VERSION "HNNBNNNYNNNNNNNNNNNNNNNNNNNNNNNNNNNNNNNNNN/4/%%%/4/'%**4NNN///"

NS_ :

BS_:

BU_: Airbag Allrad_Haldex BAP_Tester DCC_Gen3 EBKV_MQBW ESC_MQBW Gateway_Max Lenkhilfe_REPS

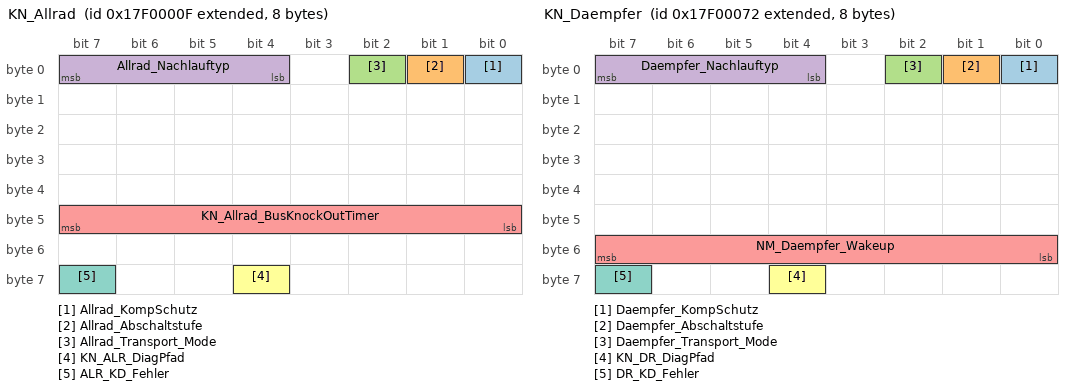
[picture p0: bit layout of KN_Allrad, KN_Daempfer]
BO_ 2549088271 KN_Allrad: 8 Allrad_Haldex
 SG_ Allrad_KompSchutz : 0|1@1+ (1.0,0.0) [0.0|1] ""  Vector__XXX
 SG_ Allrad_Abschaltstufe : 1|1@1+ (1.0,0.0) [0.0|1] ""  Vector__XXX
 SG_ Allrad_Transport_Mode : 2|1@1+ (1.0,0.0) [0.0|1] ""  Vector__XXX
 SG_ Allrad_Nachlauftyp : 4|4@1+ (1.0,0.0) [0.0|15] ""  Gateway_Max
 SG_ KN_Allrad_BusKnockOutTimer : 40|8@1+ (1,0) [0|254] ""  Vector__XXX
 SG_ KN_ALR_DiagPfad : 60|1@1+ (1.0,0.0) [0.0|1] ""  Gateway_Max
 SG_ ALR_KD_Fehler : 63|1@1+ (1.0,0.0) [0.0|1] ""  Gateway_Max

BO_ 2549088370 KN_Daempfer: 8 DCC_Gen3
 SG_ Daempfer_KompSchutz : 0|1@1+ (1.0,0.0) [0.0|1] ""  Vector__XXX
 SG_ Daempfer_Abschaltstufe : 1|1@1+ (1.0,0.0) [0.0|1] ""  Vector__XXX
 SG_ Daempfer_Transport_Mode : 2|1@1+ (1.0,0.0) [0.0|1] ""  Vector__XXX
 SG_ Daempfer_Nachlauftyp : 4|4@1+ (1.0,0.0) [0.0|15] ""  Gateway_Max
 SG_ NM_Daempfer_Wakeup : 48|8@1+ (1.0,0.0) [0.0|255] ""  Vector__XXX
 SG_ KN_DR_DiagPfad : 60|1@1+ (1.0,0.0) [0.0|1] ""  Gateway_Max
 SG_ DR_KD_Fehler : 63|1@1+ (1.0,0.0) [0.0|1] ""  Gateway_Max

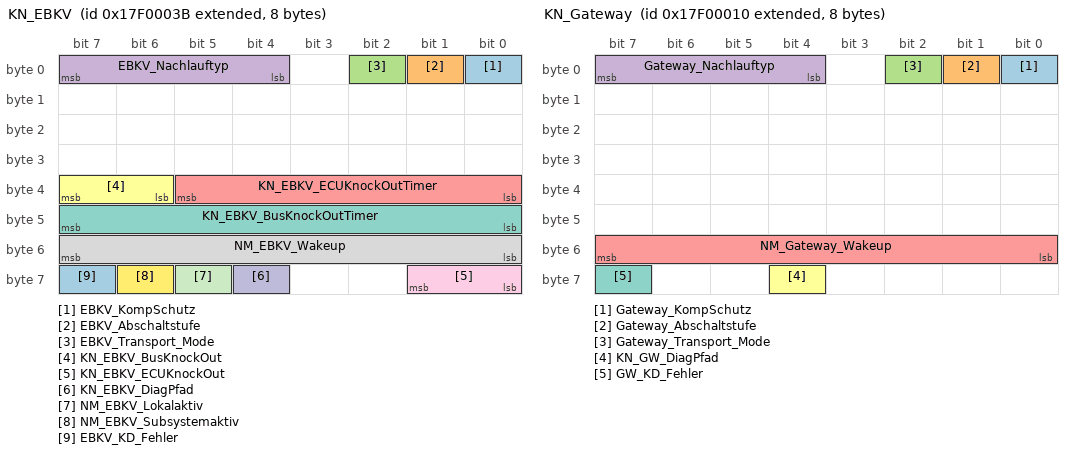
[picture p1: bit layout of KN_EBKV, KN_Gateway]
BO_ 2549088315 KN_EBKV: 8 EBKV_MQBW
 SG_ EBKV_KompSchutz : 0|1@1+ (1.0,0.0) [0.0|1] ""  Vector__XXX
 SG_ EBKV_Abschaltstufe : 1|1@1+ (1.0,0.0) [0.0|1] ""  Vector__XXX
 SG_ EBKV_Transport_Mode : 2|1@1+ (1.0,0.0) [0.0|1] ""  Vector__XXX
 SG_ EBKV_Nachlauftyp : 4|4@1+ (1.0,0.0) [0.0|15] ""  Gateway_Max
 SG_ KN_EBKV_ECUKnockOutTimer : 32|6@1+ (1,0) [0|62] "Unit_Minut"  Vector__XXX
 SG_ KN_EBKV_BusKnockOut : 38|2@1+ (1.0,0.0) [0.0|3] ""  Vector__XXX
 SG_ KN_EBKV_BusKnockOutTimer : 40|8@1+ (1,0) [0|254] ""  Vector__XXX
 SG_ NM_EBKV_Wakeup : 48|8@1+ (1.0,0.0) [0.0|255] ""  Vector__XXX
 SG_ KN_EBKV_ECUKnockOut : 56|2@1+ (1.0,0.0) [0.0|3] ""  Vector__XXX
 SG_ KN_EBKV_DiagPfad : 60|1@1+ (1.0,0.0) [0.0|1] ""  Gateway_Max
 SG_ NM_EBKV_Lokalaktiv : 61|1@1+ (1.0,0.0) [0.0|1] ""  Vector__XXX
 SG_ NM_EBKV_Subsystemaktiv : 62|1@1+ (1.0,0.0) [0.0|1] ""  Vector__XXX
 SG_ EBKV_KD_Fehler : 63|1@1+ (1.0,0.0) [0.0|1] ""  Gateway_Max

BO_ 2549088272 KN_Gateway: 8 Gateway_Max
 SG_ Gateway_KompSchutz : 0|1@1+ (1.0,0.0) [0.0|1] ""  Vector__XXX
 SG_ Gateway_Abschaltstufe : 1|1@1+ (1.0,0.0) [0.0|1] ""  Vector__XXX
 SG_ Gateway_Transport_Mode : 2|1@1+ (1.0,0.0) [0.0|1] ""  Vector__XXX
 SG_ Gateway_Nachlauftyp : 4|4@1+ (1.0,0.0) [0.0|15] ""  Vector__XXX
 SG_ NM_Gateway_Wakeup : 48|8@1+ (1.0,0.0) [0.0|255] ""  Vector__XXX
 SG_ KN_GW_DiagPfad : 60|1@1+ (1.0,0.0) [0.0|1] ""  Vector__XXX
 SG_ GW_KD_Fehler : 63|1@1+ (1.0,0.0) [0.0|1] ""  Vector__XXX

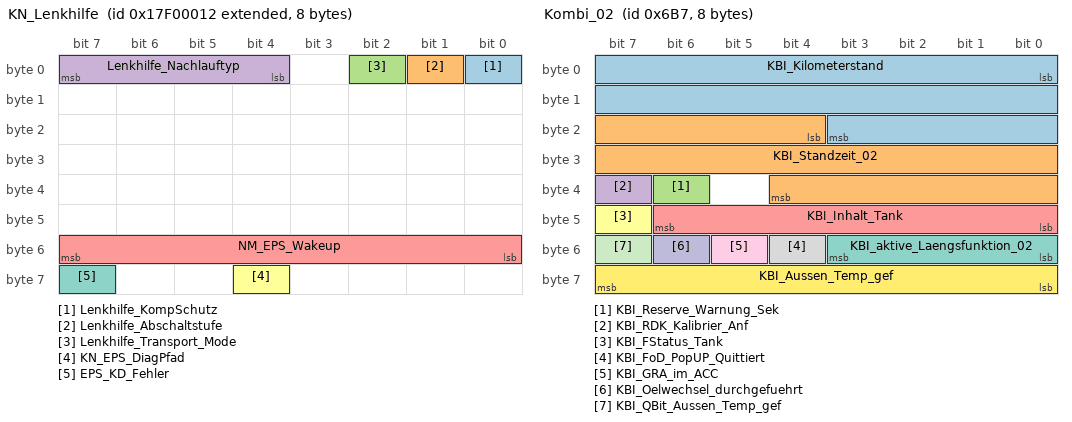
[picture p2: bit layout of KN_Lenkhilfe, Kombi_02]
BO_ 2549088274 KN_Lenkhilfe: 8 Lenkhilfe_REPS
 SG_ Lenkhilfe_KompSchutz : 0|1@1+ (1.0,0.0) [0.0|1] ""  Vector__XXX
 SG_ Lenkhilfe_Abschaltstufe : 1|1@1+ (1.0,0.0) [0.0|1] ""  Vector__XXX
 SG_ Lenkhilfe_Transport_Mode : 2|1@1+ (1.0,0.0) [0.0|1] ""  Vector__XXX
 SG_ Lenkhilfe_Nachlauftyp : 4|4@1+ (1.0,0.0) [0.0|15] ""  Gateway_Max
 SG_ NM_EPS_Wakeup : 48|8@1+ (1.0,0.0) [0.0|255] ""  Vector__XXX
 SG_ KN_EPS_DiagPfad : 60|1@1+ (1.0,0.0) [0.0|1] ""  Gateway_Max
 SG_ EPS_KD_Fehler : 63|1@1+ (1.0,0.0) [0.0|1] ""  Gateway_Max

BO_ 779 Kombi_01: 8 Gateway_Max
 SG_ KBI_ABS_Lampe : 0|1@1+ (1.0,0.0) [0.0|1] ""  Vector__XXX
 SG_ KBI_ESP_Lampe : 1|1@1+ (1.0,0.0) [0.0|1] ""  Vector__XXX
 SG_ KBI_BKL_Lampe : 2|1@1+ (1.0,0.0) [0.0|1] ""  Vector__XXX
 SG_ KBI_Airbag_Lampe : 3|1@1+ (1.0,0.0) [0.0|1] ""  Vector__XXX
 SG_ KBI_SILA_gueltig : 4|1@1+ (1.0,0.0) [0.0|1] ""  Vector__XXX
 SG_ KBI_Lenkung_Lampe : 5|1@1+ (1,0) [0|1] ""  Vector__XXX
 SG_ KBI_Vorglueh_System_Lampe : 6|1@1+ (1.0,0.0) [0.0|1] ""  Vector__XXX
 SG_ KBI_NV_in_Anzeige : 7|1@1+ (1.0,0.0) [0.0|1] ""  Vector__XXX
 SG_ Kombi_01_BZ : 8|4@1+ (1,0) [0|15] ""  Vector__XXX
 SG_ KBI_Anzeigestatus_ACC : 12|1@1+ (1.0,0.0) [0.0|1] ""  Vector__XXX
 SG_ KBI_Anzeigestatus_GRA : 13|2@1+ (1.0,0.0) [0.0|3] ""  Vector__XXX
 SG_ KBI_Oeldruck_Schalter : 15|1@1+ (1.0,0.0) [0.0|1] ""  Vector__XXX
 SG_ KBI_Tankwarnung : 16|1@1+ (1.0,0.0) [0.0|1] ""  Vector__XXX
 SG_ KBI_MFA_v_Einheit_01 : 17|1@1+ (1.0,0.0) [0.0|1] ""  Vector__XXX
 SG_ KBI_im_Stellgliedtest : 18|1@1+ (1.0,0.0) [0.0|1] ""  Vector__XXX
 SG_ KBI_Anzeigefehler_LDW : 19|2@1+ (1.0,0.0) [0.0|3] ""  Vector__XXX
 SG_ KBI_Tankwarnung_ungueltig : 21|1@1+ (1.0,0.0) [0.0|1] ""  Vector__XXX
 SG_ KBI_Oeldruckwarnung : 22|1@1+ (1.0,0.0) [0.0|1] ""  Vector__XXX
 SG_ KBI_Handbremse : 23|1@1+ (1.0,0.0) [0.0|1] ""  Vector__XXX
 SG_ KBI_V_Digital : 24|9@1+ (1,0) [0|511] ""  Vector__XXX
 SG_ KBI_PLA_in_Anzeige : 33|1@1+ (1.0,0.0) [0.0|1] ""  Vector__XXX
 SG_ KBI_Anzeigefehler_NV : 34|1@1+ (1.0,0.0) [0.0|1] ""  Vector__XXX
 SG_ KBI_Anzeigestatus_LIM : 35|2@1+ (1.0,0.0) [0.0|3] ""  Vector__XXX
 SG_ KBI_ARA_in_Anzeige : 37|1@1+ (1.0,0.0) [0.0|1] ""  Vector__XXX
 SG_ KBI_Taster_Lift : 38|1@1+ (1.0,0.0) [0.0|1] ""  Vector__XXX
 SG_ KBI_Taster_Fahrwerk : 39|1@1+ (1.0,0.0) [0.0|1] ""  Vector__XXX
 SG_ KBI_Audioabsenkung_MIB : 40|2@1+ (1.0,0.0) [0.0|3] ""  Vector__XXX
 SG_ KBI_Bestaetigung_ESP_Off : 42|2@1+ (1.0,0.0) [0.0|3] ""  ESC_MQBW
 SG_ KBI_Anzeigestatus_RHP : 44|2@1+ (1.0,0.0) [0.0|3] ""  Vector__XXX
 SG_ KBI_angez_Geschw : 48|10@1+ (0.32,0) [0.00|325.12] "Unit_KiloMeterPerHour"  Airbag
 SG_ KBI_Konsistenz_ACC : 59|1@1+ (1.0,0.0) [0.0|1] ""  Vector__XXX
 SG_ KBI_Fehler_Anzeige_ACC : 60|1@1+ (1.0,0.0) [0.0|1] ""  Vector__XXX
 SG_ KBI_Anzeigefehler_SWA : 61|2@1+ (1.0,0.0) [0.0|3] ""  Vector__XXX
 SG_ KBI_Systemstatus : 63|1@1+ (1.0,0.0) [0.0|1] ""  Vector__XXX

BO_ 1719 Kombi_02: 8 Gateway_Max
 SG_ KBI_Kilometerstand : 0|20@1+ (1,0) [0|1048573] "Unit_KiloMeter"  Vector__XXX
 SG_ KBI_Standzeit_02 : 20|17@1+ (1,0) [0|131068] "Unit_Secon"  Allrad_Haldex,ESC_MQBW
 SG_ KBI_Reserve_Warnung_Sek : 38|1@1+ (1.0,0.0) [0.0|1] ""  Vector__XXX
 SG_ KBI_RDK_Kalibrier_Anf : 39|1@1+ (1.0,0.0) [0.0|1] ""  Vector__XXX
 SG_ KBI_Inhalt_Tank : 40|7@1+ (1,0) [0|125] "Unit_Liter"  Vector__XXX
 SG_ KBI_FStatus_Tank : 47|1@1+ (1.0,0.0) [0.0|1] ""  Vector__XXX
 SG_ KBI_aktive_Laengsfunktion_02 : 48|4@1+ (1.0,0.0) [0.0|15] ""  Vector__XXX
 SG_ KBI_FoD_PopUP_Quittiert : 52|1@1+ (1.0,0.0) [0.0|1] ""  Vector__XXX
 SG_ KBI_GRA_im_ACC : 53|1@1+ (1.0,0.0) [0.0|1] ""  Vector__XXX
 SG_ KBI_Oelwechsel_durchgefuehrt : 54|1@1+ (1.0,0.0) [0.0|1] ""  Vector__XXX
 SG_ KBI_QBit_Aussen_Temp_gef : 55|1@1+ (1.0,0.0) [0.0|1] ""  Airbag,Allrad_Haldex,ESC_MQBW
 SG_ KBI_Aussen_Temp_gef : 56|8@1+ (0.5,-50) [-50.0|75.0] "Unit_DegreCelsi"  Airbag,Allrad_Haldex,ESC_MQBW

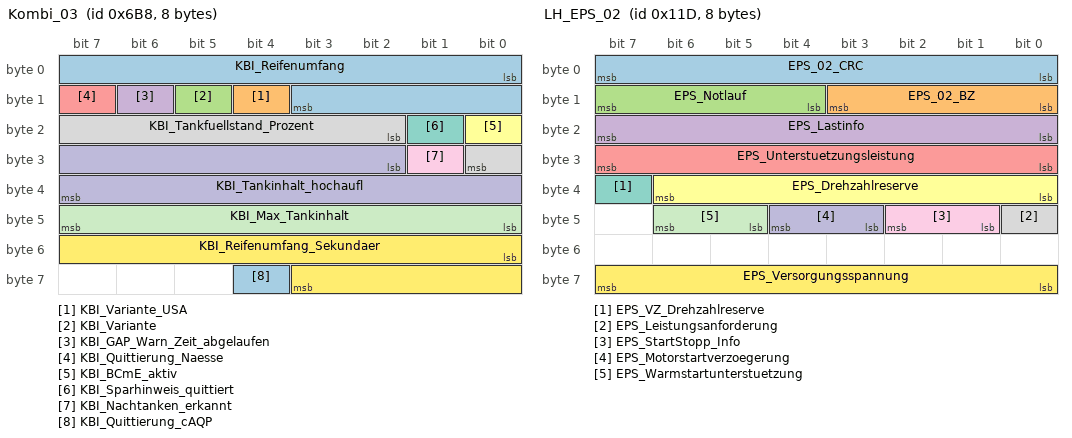
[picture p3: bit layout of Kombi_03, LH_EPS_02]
BO_ 1720 Kombi_03: 8 Gateway_Max
 SG_ KBI_Reifenumfang : 0|12@1+ (1,0) [0|4095] "Unit_MilliMeter"  ESC_MQBW
 SG_ KBI_Variante_USA : 12|1@1+ (1.0,0.0) [0.0|1] ""  Vector__XXX
 SG_ KBI_Variante : 13|1@1+ (1.0,0.0) [0.0|1] ""  Vector__XXX
 SG_ KBI_GAP_Warn_Zeit_abgelaufen : 14|1@1+ (1.0,0.0) [0.0|1] ""  Vector__XXX
 SG_ KBI_Quittierung_Naesse : 15|1@1+ (1.0,0.0) [0.0|1] ""  Vector__XXX
 SG_ KBI_BCmE_aktiv : 16|1@1+ (1.0,0.0) [0.0|1] ""  Vector__XXX
 SG_ KBI_Sparhinweis_quittiert : 17|1@1+ (1.0,0.0) [0.0|1] ""  Vector__XXX
 SG_ KBI_Tankfuellstand_Prozent : 18|7@1+ (1,0) [0|100] "Unit_PerCent"  Vector__XXX
 SG_ KBI_Nachtanken_erkannt : 25|1@1+ (1.0,0.0) [0.0|1] ""  Vector__XXX
 SG_ KBI_Tankinhalt_hochaufl : 26|14@1+ (0.01,0) [0.00|163.81] "Unit_Liter"  Vector__XXX
 SG_ KBI_Max_Tankinhalt : 40|8@1+ (0.5,0) [0.0|126.5] ""  Vector__XXX
 SG_ KBI_Reifenumfang_Sekundaer : 48|12@1+ (1,0) [0|4095] "Unit_MilliMeter"  Vector__XXX
 SG_ KBI_Quittierung_cAQP : 60|1@1+ (1.0,0.0) [0.0|1] ""  Vector__XXX

BO_ 2621440277 KS_Airbag_01_Req_FD: 16 Gateway_Max
 SG_ KS_Airbag_01_Req_FD_Data : 0|128@1+ (1.0,0.0) [0.0|340282366920938463463374607431768211455] ""  Airbag

BO_ 2621571349 KS_Airbag_01_Resp_FD: 16 Airbag
 SG_ KS_Airbag_01_Resp_FD_Data : 0|128@1+ (1.0,0.0) [0.0|340282366920938463463374607431768211455] ""  Gateway_Max

BO_ 810 LH_EPS_01: 8 Lenkhilfe_REPS
 SG_ EPS_01_CRC : 0|8@1+ (1,0) [0|255] ""  Gateway_Max
 SG_ EPS_01_BZ : 8|4@1+ (1,0) [0|15] ""  Gateway_Max
 SG_ EPS_SpannungsAnf : 12|2@1+ (1.0,0.0) [0.0|3] ""  Gateway_Max
 SG_ EPS_Endanschlag : 14|2@1+ (1.0,0.0) [0.0|3] ""  Gateway_Max
 SG_ EPS_Akustiksignal : 16|1@1+ (1.0,0.0) [0.0|1] ""  Gateway_Max
 SG_ EPS_Fehlerlampe : 17|1@1+ (1.0,0.0) [0.0|1] ""  Gateway_Max
 SG_ EPS_Warnungen : 19|3@1+ (1.0,0.0) [0.0|7] ""  Gateway_Max
 SG_ EPS_PLA_Abbruch : 22|4@1+ (1,0) [0|15] ""  Gateway_Max
 SG_ EPS_PLA_Fehler : 26|4@1+ (1,0) [0|15] ""  Gateway_Max
 SG_ EPS_PLA_Status : 30|4@1+ (1.0,0.0) [0.0|15] ""  Gateway_Max
 SG_ EPS_Charisma_FahrPr : 34|4@1+ (1.0,0.0) [0.0|15] ""  Gateway_Max
 SG_ EPS_Charisma_Status : 38|2@1+ (1.0,0.0) [0.0|3] ""  Gateway_Max
 SG_ EPS_VZ_Zst_Offset_Geradeaus : 40|1@1+ (1.0,0.0) [0.0|1] ""  Gateway_Max
 SG_ EPS_Lenkerposition : 41|2@1+ (1.0,0.0) [0.0|3] ""  Gateway_Max
 SG_ EPS_Anf_KL : 43|1@1+ (1.0,0.0) [0.0|1] ""  Gateway_Max
 SG_ EPS_ARA_Status : 44|4@1+ (1.0,0.0) [0.0|15] ""  Gateway_Max
 SG_ EPS_Zst_Offset_Geradeaus : 48|9@1+ (0.00306,0) [0.00000|1.55754] "Unit_MilliMeter"  Gateway_Max

BO_ 285 LH_EPS_02: 8 Lenkhilfe_REPS
 SG_ EPS_02_CRC : 0|8@1+ (1,0) [0|255] ""  Gateway_Max
 SG_ EPS_02_BZ : 8|4@1+ (1,0) [0|15] ""  Gateway_Max
 SG_ EPS_Notlauf : 12|4@1+ (1.0,0.0) [0.0|15] ""  Gateway_Max
 SG_ EPS_Lastinfo : 16|8@1+ (1,0) [0|253] "Unit_Amper"  Gateway_Max
 SG_ EPS_Unterstuetzungsleistung : 24|8@1+ (0.5,0) [0.0|100.0] "Unit_PerCent"  Gateway_Max
 SG_ EPS_Drehzahlreserve : 32|7@1+ (10,0) [0|1000] "Unit_DegreOfArcPerSecon"  Gateway_Max
 SG_ EPS_VZ_Drehzahlreserve : 39|1@1+ (1.0,0.0) [0.0|1] ""  Gateway_Max
 SG_ EPS_Leistungsanforderung : 40|1@1+ (1.0,0.0) [0.0|1] ""  Gateway_Max
 SG_ EPS_StartStopp_Info : 41|2@1+ (1.0,0.0) [0.0|3] ""  Gateway_Max
 SG_ EPS_Motorstartverzoegerung : 43|2@1+ (1.0,0.0) [0.0|3] ""  Gateway_Max
 SG_ EPS_Warmstartunterstuetzung : 45|2@1+ (1.0,0.0) [0.0|3] ""  Gateway_Max
 SG_ EPS_Versorgungsspannung : 56|8@1+ (0.05,5.05) [5.05|17.70] "Unit_Volt"  Gateway_Max

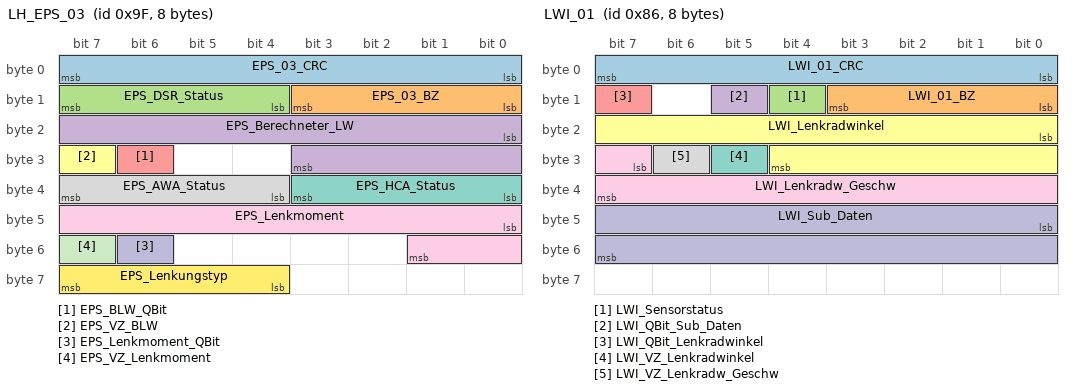
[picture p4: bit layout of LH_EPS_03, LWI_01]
BO_ 159 LH_EPS_03: 8 Lenkhilfe_REPS
 SG_ EPS_03_CRC : 0|8@1+ (1,0) [0|255] ""  Gateway_Max
 SG_ EPS_03_BZ : 8|4@1+ (1,0) [0|15] ""  Gateway_Max
 SG_ EPS_DSR_Status : 12|4@1+ (1.0,0.0) [0.0|15] ""  Gateway_Max
 SG_ EPS_Berechneter_LW : 16|12@1+ (0.15,0) [0.00|613.95] "Unit_DegreOfArc"  Gateway_Max
 SG_ EPS_BLW_QBit : 30|1@1+ (1.0,0.0) [0.0|1] ""  Gateway_Max
 SG_ EPS_VZ_BLW : 31|1@1+ (1.0,0.0) [0.0|1] ""  Gateway_Max
 SG_ EPS_HCA_Status : 32|4@1+ (1.0,0.0) [0.0|15] ""  Gateway_Max
 SG_ EPS_AWA_Status : 36|4@1+ (1.0,0.0) [0.0|15] ""  Gateway_Max
 SG_ EPS_Lenkmoment : 40|10@1+ (0.01,0) [0.00|8.00] "Unit_NewtoMeter"  Gateway_Max
 SG_ EPS_Lenkmoment_QBit : 54|1@1+ (1.0,0.0) [0.0|1] ""  Gateway_Max
 SG_ EPS_VZ_Lenkmoment : 55|1@1+ (1.0,0.0) [0.0|1] ""  Gateway_Max
 SG_ EPS_Lenkungstyp : 60|4@1+ (1.0,0.0) [0.0|15] ""  Gateway_Max

BO_ 110 LH_EPS_05_Auth: 12 Lenkhilfe_REPS
 SG_ EPS_05_CRC : 0|8@1+ (1,0) [0|255] ""  ESC_MQBW,Gateway_Max
 SG_ EPS_05_BZ : 8|4@1+ (1,0) [0|15] ""  ESC_MQBW,Gateway_Max
 SG_ EPS_QBit_Zahnstangen_Grad : 29|1@1+ (1.0,0.0) [0.0|1] ""  Gateway_Max
 SG_ EPS_Sensorikstatus : 30|1@1+ (1.0,0.0) [0.0|1] ""  Gateway_Max
 SG_ EPS_QBit_Zahnstangen_Pos : 31|1@1+ (1.0,0.0) [0.0|1] ""  ESC_MQBW,Gateway_Max
 SG_ EPS_Zahnstangen_Pos_02 : 32|15@1+ (0.00306,0) [0.00000|100.00080] "Unit_MilliMeter"  DCC_Gen3,ESC_MQBW,Gateway_Max
 SG_ EPS_VZ_Zahnstangenposition : 47|1@1+ (1.0,0.0) [0.0|1] ""  DCC_Gen3,ESC_MQBW,Gateway_Max
 SG_ EPS_Zahnstangen_Grad : 48|15@1+ (0.0000078125,0) [0E-10|0.2559843750] "Unit_MeterPerSecon"  DCC_Gen3,ESC_MQBW,Gateway_Max
 SG_ EPS_VZ_Zahnstangen_Grad : 63|1@1+ (1.0,0.0) [0.0|1] ""  DCC_Gen3,ESC_MQBW,Gateway_Max
 SG_ SOK_LH_EPS_05_Signatur : 64|32@1+ (1,0) [0|4294967295] ""  Gateway_Max

BO_ 981 Licht_Anf_01: 8 Gateway_Max
 SG_ Licht_Anf_01_CRC : 0|8@1+ (1,0) [0|255] ""  Vector__XXX
 SG_ Licht_Anf_01_BZ : 8|4@1+ (1,0) [0|15] ""  Vector__XXX
 SG_ BCM1_Kurvenlicht_links_Anf : 12|1@1+ (1.0,0.0) [0.0|1] ""  Vector__XXX
 SG_ BCM1_Kurvenlicht_rechts_Anf : 13|1@1+ (1.0,0.0) [0.0|1] ""  Vector__XXX
 SG_ BCM1_Standlicht_Anf : 14|1@1+ (1.0,0.0) [0.0|1] ""  Vector__XXX
 SG_ BCM1_Abblendlicht_Anf : 15|1@1+ (1.0,0.0) [0.0|1] ""  Vector__XXX
 SG_ BCM1_Fernlicht_Anf : 16|1@1+ (1.0,0.0) [0.0|1] ""  Vector__XXX
 SG_ BCM1_Nebellicht_Anf : 17|1@1+ (1.0,0.0) [0.0|1] ""  Vector__XXX
 SG_ BCM1_Parklicht_li_Anf : 18|1@1+ (1.0,0.0) [0.0|1] ""  Vector__XXX
 SG_ BCM1_Parklicht_re_Anf : 19|1@1+ (1.0,0.0) [0.0|1] ""  Vector__XXX
 SG_ BCM1_Nebelschluss_Ahg_Anf : 20|1@1+ (1.0,0.0) [0.0|1] ""  Vector__XXX
 SG_ BCM1_Nebelschluss_Fzg_Anf : 21|1@1+ (1.0,0.0) [0.0|1] ""  Vector__XXX
 SG_ BCM1_Schlusslicht_Anf : 22|1@1+ (1.0,0.0) [0.0|1] ""  Vector__XXX
 SG_ BCM_Rueckfahrlicht_Anf : 23|1@1+ (1.0,0.0) [0.0|1] ""  EBKV_MQBW
 SG_ BCM1_Signaturlicht_Anf : 24|1@1+ (1.0,0.0) [0.0|1] ""  Vector__XXX
 SG_ BCM1_Umfeldleuchten_Anf : 25|1@1+ (1.0,0.0) [0.0|1] ""  Vector__XXX
 SG_ BCM1_Tagfahrlicht_Anf : 26|1@1+ (1.0,0.0) [0.0|1] ""  Vector__XXX
 SG_ BCM1_Regenlicht_Anf : 27|1@1+ (1.0,0.0) [0.0|1] ""  Vector__XXX
 SG_ BCM1_Autobahnlicht_Anf : 28|1@1+ (1.0,0.0) [0.0|1] ""  Vector__XXX
 SG_ BCM1_Touristen_Licht_Anf : 29|1@1+ (1.0,0.0) [0.0|1] ""  Vector__XXX
 SG_ BCM1_CH_aktiv : 30|1@1+ (1.0,0.0) [0.0|1] ""  Vector__XXX
 SG_ BCM1_LH_aktiv : 31|1@1+ (1.0,0.0) [0.0|1] ""  Vector__XXX
 SG_ BCM1_Gleitende_Leuchtw_Anf : 32|1@1+ (1.0,0.0) [0.0|1] ""  Vector__XXX
 SG_ BCM1_GLW_Fernlicht_Anf : 33|1@1+ (1.0,0.0) [0.0|1] ""  Vector__XXX
 SG_ BCM1_Adaptive_Lichtvert_Anf : 34|1@1+ (1.0,0.0) [0.0|1] ""  Vector__XXX
 SG_ BCM1_Animationssperrung : 39|1@1+ (1.0,0.0) [0.0|1] ""  Vector__XXX
 SG_ BCM1_CH_LH_aktiv : 40|1@1+ (1.0,0.0) [0.0|1] ""  Vector__XXX
 SG_ BCM1_Allwetterlicht_Anf : 41|1@1+ (1.0,0.0) [0.0|1] ""  Vector__XXX
 SG_ TFL_Matrix_Variante01_Anf : 42|1@1+ (1.0,0.0) [0.0|1] ""  Vector__XXX
 SG_ TFL_Matrix_Variante02_Anf : 43|1@1+ (1.0,0.0) [0.0|1] ""  Vector__XXX
 SG_ TFL_Matrix_Variante03_Anf : 44|1@1+ (1.0,0.0) [0.0|1] ""  Vector__XXX
 SG_ TFL_Matrix_Variante04_Anf : 45|1@1+ (1.0,0.0) [0.0|1] ""  Vector__XXX

BO_ 982 Licht_hinten_01: 8 Gateway_Max
 SG_ Licht_hinten_01_BZ : 0|4@1+ (1,0) [0|15] ""  ESC_MQBW
 SG_ BCM2_Bremsl_durch_ECD_invers : 4|1@1+ (1.0,0.0) [0.0|1] ""  ESC_MQBW
 SG_ BCM2_Bremsl_durch_ECD : 5|1@1+ (1.0,0.0) [0.0|1] ""  ESC_MQBW
 SG_ LH_Aussenlicht_def : 7|1@1+ (1.0,0.0) [0.0|1] ""  Vector__XXX
 SG_ LH_Standlicht_H_aktiv : 8|1@1+ (1.0,0.0) [0.0|1] ""  Vector__XXX
 SG_ LH_Parklicht_HL_aktiv : 9|1@1+ (1.0,0.0) [0.0|1] ""  Vector__XXX
 SG_ LH_Parklicht_HR_aktiv : 10|1@1+ (1.0,0.0) [0.0|1] ""  Vector__XXX
 SG_ LH_Bremslicht_H_aktiv : 11|1@1+ (1.0,0.0) [0.0|1] ""  Vector__XXX
 SG_ LH_Nebelschluss_aktiv : 12|1@1+ (1.0,0.0) [0.0|1] ""  Vector__XXX
 SG_ LH_Rueckfahrlicht_aktiv : 13|1@1+ (1.0,0.0) [0.0|1] ""  Vector__XXX
 SG_ LH_Blinker_HL_akt : 14|1@1+ (1.0,0.0) [0.0|1] ""  Vector__XXX
 SG_ LH_Blinker_HR_akt : 15|1@1+ (1.0,0.0) [0.0|1] ""  Vector__XXX
 SG_ LH_Blinker_li_def : 16|1@1+ (1.0,0.0) [0.0|1] ""  Vector__XXX
 SG_ LH_Bremsl_li_def : 17|1@1+ (1.0,0.0) [0.0|1] ""  ESC_MQBW
 SG_ LH_Schlusslicht_li_def : 18|1@1+ (1.0,0.0) [0.0|1] ""  Vector__XXX
 SG_ LH_Rueckf_li_def : 19|1@1+ (1.0,0.0) [0.0|1] ""  Vector__XXX
 SG_ LH_Nebel_li_def : 20|1@1+ (1.0,0.0) [0.0|1] ""  Vector__XXX
 SG_ LH_Schluss_Brems_Nebel_li_def : 21|1@1+ (1.0,0.0) [0.0|1] ""  Vector__XXX
 SG_ LH_Schluss_Brems_Nebel_re_def : 22|1@1+ (1.0,0.0) [0.0|1] ""  Vector__XXX
 SG_ LH_Zusatzschlussl_def : 23|1@1+ (1.0,0.0) [0.0|1] ""  Vector__XXX
 SG_ LH_Schluss_Brems_li_def : 24|1@1+ (1.0,0.0) [0.0|1] ""  Vector__XXX
 SG_ LH_Schluss_Nebel_li_def : 25|1@1+ (1.0,0.0) [0.0|1] ""  Vector__XXX
 SG_ LH_SL_BRL_BLK_li_def : 26|1@1+ (1.0,0.0) [0.0|1] ""  Vector__XXX
 SG_ LH_Brems_Blk_li_def : 27|1@1+ (1.0,0.0) [0.0|1] ""  Vector__XXX
 SG_ LH_Diag_Status_re_def : 28|1@1+ (1.0,0.0) [0.0|1] ""  Vector__XXX
 SG_ LH_Diag_Status_li_def : 29|1@1+ (1.0,0.0) [0.0|1] ""  Vector__XXX
 SG_ LH_Diag_LED_li_def : 30|1@1+ (1.0,0.0) [0.0|1] ""  Vector__XXX
 SG_ LH_Diag_LED_re_def : 31|1@1+ (1.0,0.0) [0.0|1] ""  Vector__XXX
 SG_ LH_Blinker_re_def : 32|1@1+ (1.0,0.0) [0.0|1] ""  Vector__XXX
 SG_ LH_Bremsl_re_def : 33|1@1+ (1.0,0.0) [0.0|1] ""  ESC_MQBW
 SG_ LH_Schlusslicht_re_def : 34|1@1+ (1.0,0.0) [0.0|1] ""  Vector__XXX
 SG_ LH_Rueckf_re_def : 35|1@1+ (1.0,0.0) [0.0|1] ""  Vector__XXX
 SG_ LH_Nebel_re_def : 36|1@1+ (1.0,0.0) [0.0|1] ""  Vector__XXX
 SG_ LH_Schluss_Brems_re_def : 40|1@1+ (1.0,0.0) [0.0|1] ""  Vector__XXX
 SG_ LH_Schluss_Nebel_re_def : 41|1@1+ (1.0,0.0) [0.0|1] ""  Vector__XXX
 SG_ LH_SL_BRL_BLK_re_def : 42|1@1+ (1.0,0.0) [0.0|1] ""  Vector__XXX
 SG_ LH_Brems_Blk_re_def : 43|1@1+ (1.0,0.0) [0.0|1] ""  Vector__XXX
 SG_ LH_Kennzl_def : 48|1@1+ (1.0,0.0) [0.0|1] ""  Vector__XXX
 SG_ LH_3_Bremsl_def : 49|1@1+ (1.0,0.0) [0.0|1] ""  Vector__XXX
 SG_ LH_Nebel_mi_def : 50|1@1+ (1.0,0.0) [0.0|1] ""  Vector__XXX
 SG_ LH_Rueckf_mi_def : 51|1@1+ (1.0,0.0) [0.0|1] ""  Vector__XXX
 SG_ LH_Bremsl_li_ges_def : 54|1@1+ (1.0,0.0) [0.0|1] ""  ESC_MQBW
 SG_ LH_Bremsl_re_ges_def : 55|1@1+ (1.0,0.0) [0.0|1] ""  ESC_MQBW

BO_ 134 LWI_01: 8 Lenkhilfe_REPS
 SG_ LWI_01_CRC : 0|8@1+ (1,0) [0|255] ""  Airbag,ESC_MQBW,Gateway_Max
 SG_ LWI_01_BZ : 8|4@1+ (1,0) [0|15] ""  Airbag,Allrad_Haldex,ESC_MQBW,Gateway_Max
 SG_ LWI_Sensorstatus : 12|1@1+ (1.0,0.0) [0.0|1] ""  Airbag,Allrad_Haldex,ESC_MQBW,Gateway_Max
 SG_ LWI_QBit_Sub_Daten : 13|1@1+ (1.0,0.0) [0.0|1] ""  Gateway_Max
 SG_ LWI_QBit_Lenkradwinkel : 15|1@1+ (1.0,0.0) [0.0|1] ""  Airbag,Allrad_Haldex,ESC_MQBW,Gateway_Max
 SG_ LWI_Lenkradwinkel : 16|13@1+ (0.1,0) [0.0|800.0] "Unit_DegreOfArc"  Airbag,Allrad_Haldex,ESC_MQBW,Gateway_Max
 SG_ LWI_VZ_Lenkradwinkel : 29|1@1+ (1.0,0.0) [0.0|1] ""  Airbag,Allrad_Haldex,ESC_MQBW,Gateway_Max
 SG_ LWI_VZ_Lenkradw_Geschw : 30|1@1+ (1.0,0.0) [0.0|1] ""  ESC_MQBW,Gateway_Max
 SG_ LWI_Lenkradw_Geschw : 31|9@1+ (5,0) [0|2500] "Unit_DegreOfArcPerSecon"  Airbag,ESC_MQBW,Gateway_Max
 SG_ LWI_Sub_Daten : 40|16@1+ (1,0) [0|65535] ""  Gateway_Max

BO_ 2463978889 Mem_BFS_Fond_03: 8 Gateway_Max
 SG_ Mem_BFS_Fond_03_CRC : 0|8@1+ (1,0) [0|255] ""  Airbag
 SG_ Mem_BFS_Fond_03_BZ : 8|4@1+ (1,0) [0|15] ""  Airbag
 SG_ Mem_HBFSFo_Warnung_Softstop : 12|2@1+ (1.0,0.0) [0.0|3] ""  Vector__XXX
 SG_ Mem_HBFSFo_Stoerung : 14|2@1+ (1.0,0.0) [0.0|3] ""  Vector__XXX
 SG_ Mem_HBFSFo_globaler_Lehnenwinkel : 16|8@1+ (1,0) [0|253] ""  Airbag
 SG_ Mem_HBFSFo_globaler_Sitzflachenw : 24|8@1+ (1,0) [0|253] ""  Airbag
 SG_ Mem_HBFSFo_Sperre_Sitzdisplay : 32|1@1+ (1.0,0.0) [0.0|1] ""  Vector__XXX
 SG_ Mem_HBFSFo_Abschaltanf_SRAB : 33|2@1+ (1.0,0.0) [0.0|3] ""  Airbag
 SG_ Mem_HBFSFo_Anzeige_Komfort_HBFS : 35|3@1+ (1.0,0.0) [0.0|7] ""  Vector__XXX
 SG_ Mem_HBFSFo_Status_Schalter_Ki_Si : 38|2@1+ (1.0,0.0) [0.0|3] ""  Airbag
 SG_ Mem_HBFSFo_ARMTuer_aktiv : 40|1@1+ (1.0,0.0) [0.0|1] ""  Vector__XXX
 SG_ Mem_HBFSFo_ARMTunnel_aktiv : 41|1@1+ (1.0,0.0) [0.0|1] ""  Vector__XXX
 SG_ Mem_HBFSFo_SHV_aktiv : 42|1@1+ (1.0,0.0) [0.0|1] ""  Vector__XXX
 SG_ Mem_HBFSFo_SLV_aktiv : 43|1@1+ (1.0,0.0) [0.0|1] ""  Vector__XXX
 SG_ Mem_HBFSFo_SLV_hinten : 44|1@1+ (1.0,0.0) [0.0|1] ""  Vector__XXX
 SG_ Mem_HBFSFo_BATV_aktiv : 45|1@1+ (1.0,0.0) [0.0|1] ""  Vector__XXX
 SG_ Mem_HBFSFo_EE_Entriegl_Motor : 46|1@1+ (1.0,0.0) [0.0|1] ""  Vector__XXX
 SG_ Mem_HBFSFo_EE_Verr_Sensor_re : 47|3@1+ (1.0,0.0) [0.0|7] ""  Vector__XXX
 SG_ Mem_HBFSFo_Verr_Sensor_oben_re : 50|3@1+ (1.0,0.0) [0.0|7] ""  Vector__XXX
 SG_ Mem_HBFSFo_Verr_Sensor_unten_re : 53|3@1+ (1.0,0.0) [0.0|7] ""  Vector__XXX
 SG_ Mem_HBFSFo_LNV_aktiv : 56|1@1+ (1.0,0.0) [0.0|1] ""  Vector__XXX
 SG_ Mem_HBFSFo_SNV_aktiv : 57|1@1+ (1.0,0.0) [0.0|1] ""  Vector__XXX
 SG_ Mem_HBFSFo_KSV_aktiv : 58|1@1+ (1.0,0.0) [0.0|1] ""  Vector__XXX
 SG_ Mem_HBFSFo_LKV_aktiv : 59|1@1+ (1.0,0.0) [0.0|1] ""  Vector__XXX
 SG_ Mem_HBFSFo_STV_aktiv : 60|1@1+ (1.0,0.0) [0.0|1] ""  Vector__XXX
 SG_ Mem_HBFSFo_BANV_aktiv : 61|1@1+ (1.0,0.0) [0.0|1] ""  Vector__XXX
 SG_ Mem_HBFSFo_LED_EA_Taster : 62|2@1+ (1.0,0.0) [0.0|3] ""  Vector__XXX

BO_ 2463978890 Mem_FS_Fond_03: 8 Gateway_Max
 SG_ Mem_FS_Fond_03_CRC : 0|8@1+ (1,0) [0|255] ""  Airbag
 SG_ Mem_FS_Fond_03_BZ : 8|4@1+ (1,0) [0|15] ""  Airbag
 SG_ Mem_HFSFo_Warnung_Softstop : 12|2@1+ (1.0,0.0) [0.0|3] ""  Vector__XXX
 SG_ Mem_HFSFo_Stoerung : 14|2@1+ (1.0,0.0) [0.0|3] ""  Vector__XXX
 SG_ Mem_HFSFo_globaler_Lehnenwinkel : 16|8@1+ (1,0) [0|253] ""  Airbag
 SG_ Mem_HFSFo_globaler_Sitzflachenwi : 24|8@1+ (1,0) [0|253] ""  Airbag
 SG_ Mem_HFSFo_Sperre_Sitzdisplay : 32|1@1+ (1.0,0.0) [0.0|1] ""  Vector__XXX
 SG_ Mem_HFSFo_Abschaltanf_SRAB : 33|2@1+ (1.0,0.0) [0.0|3] ""  Airbag
 SG_ Mem_HFSFo_Anzeige_Komfort_HFS : 35|3@1+ (1.0,0.0) [0.0|7] ""  Vector__XXX
 SG_ Mem_HFSFo_Status_Schalter_Ki_Si : 38|2@1+ (1.0,0.0) [0.0|3] ""  Airbag
 SG_ Mem_HFSFo_ARMTuer_aktiv : 40|1@1+ (1.0,0.0) [0.0|1] ""  Vector__XXX
 SG_ Mem_HFSFo_ARMTunnel_aktiv : 41|1@1+ (1.0,0.0) [0.0|1] ""  Vector__XXX
 SG_ Mem_HFSFo_SHV_aktiv : 42|1@1+ (1.0,0.0) [0.0|1] ""  Vector__XXX
 SG_ Mem_HFSFo_SLV_aktiv : 43|1@1+ (1.0,0.0) [0.0|1] ""  Vector__XXX
 SG_ Mem_HFSFo_SLV_hinten : 44|1@1+ (1.0,0.0) [0.0|1] ""  Vector__XXX
 SG_ Mem_HFSFo_BATV_aktiv : 45|1@1+ (1.0,0.0) [0.0|1] ""  Vector__XXX
 SG_ Mem_HFSFo_EE_Verr_Sensor_li : 46|3@1+ (1.0,0.0) [0.0|7] ""  Vector__XXX
 SG_ Mem_HFSFo_Verr_Sensor_oben_li : 49|3@1+ (1.0,0.0) [0.0|7] ""  Vector__XXX
 SG_ Mem_HFSFo_Verr_Sensor_unten_li : 52|3@1+ (1.0,0.0) [0.0|7] ""  Vector__XXX
 SG_ Mem_HFSFo_LNV_aktiv : 55|1@1+ (1.0,0.0) [0.0|1] ""  Vector__XXX
 SG_ Mem_HFSFo_SNV_aktiv : 56|1@1+ (1.0,0.0) [0.0|1] ""  Vector__XXX
 SG_ Mem_HFSFo_KSV_aktiv : 57|1@1+ (1.0,0.0) [0.0|1] ""  Vector__XXX
 SG_ Mem_HFSFo_LKV_aktiv : 58|1@1+ (1.0,0.0) [0.0|1] ""  Vector__XXX
 SG_ Mem_HFSFo_STV_aktiv : 59|1@1+ (1.0,0.0) [0.0|1] ""  Vector__XXX
 SG_ Mem_HFSFo_BANV_aktiv : 60|1@1+ (1.0,0.0) [0.0|1] ""  Vector__XXX
 SG_ Mem_HFSFo_LED_EA_Taster : 61|2@1+ (1.0,0.0) [0.0|3] ""  Vector__XXX
 SG_ Mem_HFSFo_EA_Position : 63|1@1+ (1.0,0.0) [0.0|1] ""  Vector__XXX

BO_ 245 MFDR_01: 24 ESC_MQBW
 SG_ MFDR_01_CRC : 0|8@1+ (1,0) [0|255] ""  Vector__XXX
 SG_ MFDR_01_BZ : 8|4@1+ (1,0) [0|15] ""  Vector__XXX
 SG_ MFDR_01_Sendestatus : 12|1@1+ (1.0,0.0) [0.0|1] ""  Vector__XXX
 SG_ MFDR_Active_DCC : 18|2@1+ (1.0,0.0) [0.0|3] ""  DCC_Gen3
 SG_ MFDR_Kurvenrichtung : 20|2@1+ (1.0,0.0) [0.0|3] ""  DCC_Gen3
 SG_ MFDR_UnterUebersteuern : 22|10@1+ (0.002,-1) [-1.000|1.042] "Unit_RadiaPerSecon"  Vector__XXX
 SG_ MFDR_Sollfaktor_DCC_HL : 32|8@1+ (0.8,-100) [-100.0|100.0] "Unit_PerCent"  Vector__XXX
 SG_ MFDR_Sollfaktor_DCC_HR : 40|8@1+ (0.8,-100) [-100.0|100.0] "Unit_PerCent"  Vector__XXX
 SG_ MFDR_Sollfaktor_DCC_VL : 48|8@1+ (0.8,-100) [-100.0|100.0] "Unit_PerCent"  Vector__XXX
 SG_ MFDR_Sollfaktor_DCC_VR : 56|8@1+ (0.8,-100) [-100.0|100.0] "Unit_PerCent"  Vector__XXX
 SG_ MFDR_Beschleunigung_yAchse : 64|12@1+ (0.00782,-16) [-16.00000|16.00726] "Unit_MeterPerSeconSquar"  Vector__XXX
 SG_ MFDR_DeltaKuppMom_Soll_L : 76|12@1+ (1.2211,-2500) [-2500.0000|2497.9623] "Unit_NewtoMeter"  Vector__XXX
 SG_ MFDR_DeltaKuppMom_Soll_R : 88|12@1+ (1.2211,-2500) [-2500.0000|2497.9623] "Unit_NewtoMeter"  Vector__XXX
 SG_ MFDR_Offset_DCC_HL : 100|10@1+ (2,-500) [-500|1542] "Unit_MilliAmper"  DCC_Gen3
 SG_ MFDR_Offset_DCC_HR : 110|10@1+ (2,-500) [-500|1542] "Unit_MilliAmper"  DCC_Gen3
 SG_ MFDR_Offset_DCC_VL : 120|10@1+ (2,-500) [-500|1542] "Unit_MilliAmper"  DCC_Gen3
 SG_ MFDR_Offset_DCC_VR : 130|10@1+ (2,-500) [-500|1542] "Unit_MilliAmper"  DCC_Gen3

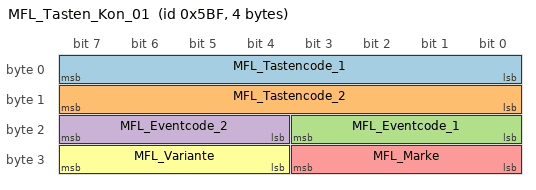
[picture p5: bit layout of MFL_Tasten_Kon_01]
BO_ 1471 MFL_Tasten_Kon_01: 4 Gateway_Max
 SG_ MFL_Tastencode_1 : 0|8@1+ (1.0,0.0) [0.0|255] ""  Vector__XXX
 SG_ MFL_Tastencode_2 : 8|8@1+ (1.0,0.0) [0.0|255] ""  Vector__XXX
 SG_ MFL_Eventcode_1 : 16|4@1+ (1.0,0.0) [0.0|15] ""  Vector__XXX
 SG_ MFL_Eventcode_2 : 20|4@1+ (1.0,0.0) [0.0|15] ""  Vector__XXX
 SG_ MFL_Marke : 24|4@1+ (1.0,0.0) [0.0|15] ""  Vector__XXX
 SG_ MFL_Variante : 28|4@1+ (1,0) [0|15] ""  Vector__XXX

BO_ 1600 Motor_07: 8 Gateway_Max
 SG_ MO_QBit_Ansaugluft_Temp : 0|1@1+ (1.0,0.0) [0.0|1] ""  Vector__XXX
 SG_ MO_QBit_Oel_Temp : 1|1@1+ (1.0,0.0) [0.0|1] ""  Vector__XXX
 SG_ MO_QBit_Kuehlmittel_Temp : 2|1@1+ (1.0,0.0) [0.0|1] ""  Vector__XXX
 SG_ MO_KL15_Abschaltempfehlung : 3|1@1+ (1.0,0.0) [0.0|1] ""  Lenkhilfe_REPS
 SG_ MO_HYB_Fehler_HV_Netz : 4|1@1+ (1.0,0.0) [0.0|1] ""  Vector__XXX
 SG_ MO_aktives_Getriebeheizen : 5|1@1+ (1.0,0.0) [0.0|1] ""  Vector__XXX
 SG_ MO_Absperrventil_oeffnen : 6|2@1+ (1.0,0.0) [0.0|3] ""  Vector__XXX
 SG_ MO_Ansaugluft_Temp : 8|8@1+ (0.75,-48) [-48.00|141.75] "Unit_DegreCelsi"  Vector__XXX
 SG_ MO_Oel_Temp : 16|8@1+ (1,-60) [-60|192] "Unit_DegreCelsi"  Vector__XXX
 SG_ MO_Kuehlmittel_Temp : 24|8@1+ (0.75,-48) [-48.00|141.75] "Unit_DegreCelsi"  Vector__XXX
 SG_ MO_Hoeheninfo : 32|8@1+ (0.00781,0) [0.00000|1.98374] ""  ESC_MQBW
 SG_ MO_Kennfeldk : 40|1@1+ (1.0,0.0) [0.0|1] ""  Vector__XXX
 SG_ MO_Versionsinfo_02 : 41|5@1+ (1.0,0.0) [0.0|31] ""  Vector__XXX
 SG_ MO_QBit_Hoeheninfo : 46|1@1+ (1.0,0.0) [0.0|1] ""  Vector__XXX
 SG_ MO_Getriebe_kuehlen : 47|1@1+ (1.0,0.0) [0.0|1] ""  Vector__XXX
 SG_ MO_Mom_Traegheit_02 : 48|5@1+ (0.01,0) [0.00|0.31] "Unit_KiloGramMeterSquar"  ESC_MQBW
 SG_ MO_Heizungspumpenansteuerung : 53|4@1+ (10,0) [0|100] "Unit_PerCent"  Vector__XXX
 SG_ MO_SpannungsAnf : 57|1@1+ (1.0,0.0) [0.0|1] ""  Vector__XXX
 SG_ MO_Nachlaufzeit_Heizungspumpe : 58|6@1+ (15,0) [0|945] "Unit_Secon"  Vector__XXX

CM_ BO_ 779 "MQB";
CM_ BO_ 810 "MQB: 50ms (für CAN-SG), geändertes Charisma, Entfall KD-Fehler";
CM_ BO_ 159 "C7 und B8

Zykluszeit 10ms zyklisch";
CM_ BO_ 982 "MQB";
CM_ BO_ 134 "ab MQB mit CRC in Byte 1";
CM_ BO_ 1600 "ab MQB mit QBit Höheneinfo und MO_Versionsinfo_02";

CM_ SG_ 2549088271 Allrad_Abschaltstufe "Funktionseinschränkung aufgrund aktiver Abschaltstufe";
CM_ SG_ 2549088271 Allrad_KompSchutz "Funktionseinschraenkung aufgrund Komponentenschutz aktiv";
CM_ SG_ 2549088271 Allrad_Nachlauftyp "Abgebildet wird die von der Hardware vorgegebene Möglichkeit, die Kommunikation nach Klemme 15 = AUS aufrecht zu erhalten. Es wird ein Init-Wert gesendet.";
CM_ SG_ 2549088271 Allrad_Transport_Mode "Funktionseinschränkung aufgrund aktivem Transport Mode und/oder Transport Schutz";
CM_ SG_ 2549088271 ALR_KD_Fehler "Bei gesetztem Bit ist mindestens ein Kundendienstfehler eingetragen";
CM_ SG_ 2549088271 KN_Allrad_BusKnockOutTimer "Ausgabe des BusKnockOut-Timer";
CM_ SG_ 2549088271 KN_ALR_DiagPfad "Kennzeichnung der Diagnosefähigkeit des BusInterfaces eines Steuergerätes (Knoten)
Umfang LAH 80127

Bei Nutzung des Signal explizit pro angebundenem BusInterface zu setzen:
MLBevo auf FlexRay A-Kanal = 0 (aktiv)
MQB A0 auf A-CAN = 0 (aktiv)
MQB AB ";

CM_ SG_ 2549088370 Daempfer_Abschaltstufe "Funktionseinschränkung aufgrund aktiver Abschaltstufe";
CM_ SG_ 2549088370 Daempfer_KompSchutz "Funktionseinschränkung aufgrund Komponentenschutz aktiv";
CM_ SG_ 2549088370 Daempfer_Nachlauftyp "Abgebildet wird die von der Hardware vorgegebene Möglichkeit, die Kommunikation nach Klemme 15 = AUS aufrecht zu erhalten. Es wird ein Init-Wert gesendet.
0 = Kommunikation nur bei KL15=EIN (kein Nachlauf, nicht weckfähig)
1 = Kommunikation nach KL15=AU";
CM_ SG_ 2549088370 Daempfer_Transport_Mode "Funktionseinschränkung aufgrund aktivem Transport Mode und/oder Transport Schutz";
CM_ SG_ 2549088370 KN_DR_DiagPfad "Kennzeichnung der Diagnosefähigkeit des BusInterfaces eines Steuergerätes (Knoten)
Umfang LAH 80127

Bei Nutzung des Signal explizit pro angebundenem BusInterface zu setzen:
MQB AB auf A-CAN,F-CAN = 0 (aktiv)
MQB A0 auf A-CAN = 0 (aktiv)
MQB2020 auf";
CM_ SG_ 2549088370 NM_Daempfer_Wakeup "enthält die Weckursache; stehen mehrere Weckursachen parallel an, dann muss der kleinste Wert übertragen werden";

CM_ SG_ 2549088315 EBKV_Abschaltstufe "Funktionseinschränkung aufgrund aktiver Abschaltstufe";
CM_ SG_ 2549088315 EBKV_KompSchutz "Funktionseinschränkung aufgrund Komponentenschutz aktiv";
CM_ SG_ 2549088315 EBKV_Nachlauftyp "Abgebildet wird die von der Hardware vorgegebene Möglichkeit, die Kommunikation nach Klemme 15 = AUS aufrecht zu erhalten. Es wird ein Init-Wert gesendet.
0 = Kommunikation nur bei KL15=EIN (kein Nachlauf, nicht weckfähig)
1 = Kommunikation nach KL15=AU";
CM_ SG_ 2549088315 EBKV_Transport_Mode "Funktionseinschränkung aufgrund aktivem Transport Mode und/oder Transport Schutz";
CM_ SG_ 2549088315 KN_EBKV_BusKnockOut "Ausgabe des BusKnockout-Status in der Knotenbotschaft";
CM_ SG_ 2549088315 KN_EBKV_BusKnockOutTimer "Ausgabe des BusKnockOut-Timer in der Knotenbotschaft";
CM_ SG_ 2549088315 KN_EBKV_DiagPfad "Kennzeichnung der Diagnosefähigkeit des BusInterfaces eines Steuergerätes (Knoten)
Umfang LAH 80127

Bei Nutzung des Signal explizit pro angebundenem BusInterface zu setzen:
MQB AB auf A-CAN,F-CAN = 0 (aktiv)
MQB2020 auf F-CAN = 0 (aktiv)
MLBevo auf";
CM_ SG_ 2549088315 KN_EBKV_ECUKnockOut "Ausgabe des ECUKnockout-Status in der Knotenbotschaft";
CM_ SG_ 2549088315 KN_EBKV_ECUKnockOutTimer "Ausgabe des ECUKnockOut-Timer in der Knotenbotschaft";
CM_ SG_ 2549088315 NM_EBKV_Lokalaktiv "Zeigt an ob das SG nach Klemme15 AUS und nach entsprechender MAX Aktivzeit noch aktiv war";
CM_ SG_ 2549088315 NM_EBKV_Subsystemaktiv "Zeigt an ob ein Subsystem des SGs nach Klemme15 AUS und nach entsprechender MAX Aktivzeit noch aktiv war";
CM_ SG_ 2549088315 NM_EBKV_Wakeup "enthält die Weckursache; stehen mehrere Weckursachen parallel an, dann muss der kleinste Wert übertragen werden";

CM_ SG_ 2549088272 Gateway_Abschaltstufe "Funktionseinschränkung aufgrund aktiver Abschaltstufe";
CM_ SG_ 2549088272 Gateway_KompSchutz "Funktionseinschränkung aufgrund Komponentenschutz aktiv";
CM_ SG_ 2549088272 Gateway_Nachlauftyp "Abgebildet wird die von der Hardware vorgegebene Möglichkeit, die Kommunikation nach Klemme 15 = AUS aufrecht zu erhalten. Es wird ein Init-Wert gesendet.";
CM_ SG_ 2549088272 Gateway_Transport_Mode "Funktionseinschränkung aufgrund aktivem Transport Mode und/oder Transport Schutz";
CM_ SG_ 2549088272 GW_KD_Fehler "Kundendienstfehlerbit Gateway zur Anzeige eines im Gateway abgelegten Fehlerspeichereintrages.";
CM_ SG_ 2549088272 KN_GW_DiagPfad "Kennzeichnung der Diagnosefähigkeit des BusInterfaces eines Steuergerätes (Knoten)
Umfang LAH 80127

Bei Nutzung des Signal explizit pro angebundenem BusInterface zu setzen:
MQB auf Diag-CAN = 0 (aktiv)
MLBevo auf Diag-CAN = 0 (aktiv)
alle weiteren ";
CM_ SG_ 2549088272 NM_Gateway_Wakeup "enthält die Weckursache; stehen mehrere Weckursachen parallel an, dann muss der kleinste Wert übertragen werden";

CM_ SG_ 2549088274 KN_EPS_DiagPfad "Kennzeichnung der Diagnosefähigkeit des BusInterfaces eines Steuergerätes (Knoten)
Umfang LAH 80127

Bei Nutzung des Signal explizit pro angebundenem BusInterface zu setzen:
MQB AB auf A-CAN,F-CAN = 0 (aktiv)
MQB A0 auf A-CAN = 0 (aktiv)
MQB2020 auf";
CM_ SG_ 2549088274 Lenkhilfe_Abschaltstufe "Funktionseinschränkung aufgrund aktiver Abschaltstufe";
CM_ SG_ 2549088274 Lenkhilfe_KompSchutz "Funktionseinschränkung aufgrund Komponentenschutz aktiv";
CM_ SG_ 2549088274 Lenkhilfe_Nachlauftyp "Abgebildet wird die von der Hardware vorgegebene Möglichkeit, die Kommunikation nach Klemme 15 = AUS aufrecht zu erhalten. Es wird ein Init-Wert gesendet.";
CM_ SG_ 2549088274 Lenkhilfe_Transport_Mode "Funktionseinschränkung aufgrund aktivem Transport Mode und/oder Transport Schutz";
CM_ SG_ 2549088274 NM_EPS_Wakeup "enthält die Weckursache; stehen mehrere Weckursachen parallel an, dann muss der kleinste Wert übertragen werden";

CM_ SG_ 779 KBI_ABS_Lampe "ABS-Sicherheits-Lampe wurde eingeschaltet.";
CM_ SG_ 779 KBI_Airbag_Lampe "Airbag Sicherheits-Lampe wurde eingeschaltet ";
CM_ SG_ 779 KBI_angez_Geschw "Im Tacho angezeigte Geschwindigkeit inklusive der Voreilung

";
CM_ SG_ 779 KBI_Anzeigefehler_NV "Über dieses Signal teilt das Kombiinstrument dem Nightvision-Steuergerät mit, dass ein Fehler vom Kombiinstrument diagnostiziert wurde, der zur Abschaltung der Nightvision-Funktion führen muss.";
CM_ SG_ 779 KBI_Anzeigefehler_SWA "Signal bezieht sich nur auf die SWA-Lampe, Vorhalt für Kombis mit SWA-Lampe. ";
CM_ SG_ 779 KBI_Anzeigestatus_ACC "Status der ACC-Anzeige im nicht permanenten Displaybereich";
CM_ SG_ 779 KBI_Anzeigestatus_GRA "Anzeigestatus der GRA High Wunschgeschwindigkeitsanzeige im Kombiinstrument.
Bei VW bedeutet 'nicht vorhanden' GRA-low fähig (LED immer verbaut).
0 = nicht vorhanden
1 = Wunschgeschwindigkeits-Anzeigemöglichkeit vorhanden
2 = reserviert
3 = Fehler (B";
CM_ SG_ 779 KBI_Anzeigestatus_LIM "Anzeigestatus der Speedlimiter Wunschgeschwindigkeitsanzeige im Kombiinstrument (permanenter Anzeigebereich)
0 = nicht vorhanden
1 = Wunschgeschwindigkeits-Anzeigemöglichkeit vorhanden
2 = reserviert
3 = Fehler (Botschaftsüberwachung, Timeout, Akustik";
CM_ SG_ 779 KBI_Anzeigestatus_RHP "Anzeigestatus des roten RHP-Symbols.";
CM_ SG_ 779 KBI_ARA_in_Anzeige "Anzeige von ARA im Kombi aktiv";
CM_ SG_ 779 KBI_Audioabsenkung_MIB "Anforderung der Audioabsenkung im MIB";
CM_ SG_ 779 KBI_Bestaetigung_ESP_Off "ESP Off Bestätigung vom Kombi ans ESC";
CM_ SG_ 779 KBI_BKL_Lampe "Sicherheits-Lampe Bremskontrolle wurde eingeschaltet;
";
CM_ SG_ 779 KBI_ESP_Lampe "ESP-Sicherheits-Lampe wurde eingeschaltet ";
CM_ SG_ 779 KBI_Fehler_Anzeige_ACC "Rückmeldung an ACC, dass mindestens eine der ACC-relevanten Anzeigen -rote Fahrerübernahme, Mitteldisplay, Gong - fehlerhaft sind.";
CM_ SG_ 779 KBI_Handbremse "Handbremsen-Information vom Kombi.
Das Signal bezieht sich ausschließlich auf den Zustand der konventionellen Handbremse.";
CM_ SG_ 779 KBI_im_Stellgliedtest "Kombi im Stellgliedtest, Signal muss eingelesen werden, um Fehlfunktion aufgrund der Bewegung der Stellglieder (Drehzahlmesser, Tacho) des Kombis zu verhindern";
CM_ SG_ 779 KBI_Konsistenz_ACC "Rückmeldung an ACC, dass die Botschaften zur Ansteuerung von Anzeigen nicht bzw. nicht konsistent empfangen wurden (Timeout-, BZ-, CHK- und DLC-Fehler)                                                                                                        ";
CM_ SG_ 779 KBI_Lenkung_Lampe "Sicherheits-Lampe der Lenkung (Lenkhilfe EPS, Audi-Dynamic-Steering ...) wurde eingeschaltet.

0x0 = Lenkungs-Lampe aus
0x1 = Lenkungs-Lampe ein";
CM_ SG_ 779 KBI_MFA_v_Einheit_01 "Einheit der Geschwindigkeit, die vom Fahrer im Car-Menü gewählt wurde. Veränderliche Grösse, im Gegensatz zur Einheit des Tachokranzes.";
CM_ SG_ 779 KBI_NV_in_Anzeige "Das Bit gibt dem NV die Information, ob NV-Bild im Kombi in der Anzeige ist. (Information ist notwendig um Kontrasverstellungen nur dann zuzulassen, wenn der Fahrer das Feedback über das  Kombidisplay bekommt.)";
CM_ SG_ 779 KBI_Oeldruck_Schalter "Das Signal bildet den Status des Öldrucks über den am Kombi angeschlossenen Öldruckschalter ab.";
CM_ SG_ 779 KBI_Oeldruckwarnung "Öldruckwarnung im Kombi aktiv";
CM_ SG_ 779 KBI_PLA_in_Anzeige "Das Signal wird als aktive Rückmeldung genutzt, ob die Info des PLA im Kombi angezeigt wird. Wenn nach Anforderung des Displays das Signal zweimal auf 0 ist, wird der Parkvorgang abgebrochen.
Ein Kombi, dass PLA Anzeige nicht unterstützt, schickt dauerha";
CM_ SG_ 779 KBI_SILA_gueltig "Rückmeldeinformation (Bit 1-6) ist gültig";
CM_ SG_ 779 KBI_Systemstatus "Signalisiert erkannte FuSi-relevante Fehler im Kombi
(keinen Ausfall der Akustik oder des Displays)";
CM_ SG_ 779 KBI_Tankwarnung "Fahrer wird gewarnt, dass er den Reservebereich erreicht hat. Fzg.spezifische Warnschwelle";
CM_ SG_ 779 KBI_Tankwarnung_ungueltig "Validiert den Inhalt des Signales KBI_Tankwarnung";
CM_ SG_ 779 KBI_Taster_Fahrwerk "Betätigung Taster 'Fahrwerk' im Kombi";
CM_ SG_ 779 KBI_Taster_Lift "Betätigung Taster 'Lift' im Kombi J1 zur Verarbeitung im Porsche EFP Steuergerät";
CM_ SG_ 779 KBI_V_Digital "Ausgabe der im Kombi angezeigten digitalen Geschwindigkeit.

Einheit ist im KBI_MFA_v_Einheit_01 definiert";
CM_ SG_ 779 KBI_Vorglueh_System_Lampe "Rückmeldung der Vorglühlampe bzw. Motor Systemlampe (MO_Systemlampe) an den Motor (bei Diesel und Otto!). Hardwaremässig gleiche LED im Kombi (EPC- oder Glühwendel), Unterscheidung nur über Ziffernblatt.";

CM_ SG_ 1719 KBI_aktive_Laengsfunktion_02 "Auswahl, der vom Fahrer gewünschten Laengsregelfunktion";
CM_ SG_ 1719 KBI_FoD_PopUP_Quittiert "Angezeigte FoD-Warnung im Kombi wurde vom Fahrer quittiert; 
Signal wird für die Dauer von 2 Sekunden gesendet";
CM_ SG_ 1719 KBI_FStatus_Tank "Signal wird gesetzt:

a) Während der Fehlerentprellzeit (20 s Entprellung)

b) Bei erkanntem Fehler wird der Tankinhalt während der laufenden KL15-Phase über den 
    Verbrauch zurückgerechnet. In dieser Zeit ist das Bit ebenfalls gesetzt. Nach einem";
CM_ SG_ 1719 KBI_GRA_im_ACC "Gibt den vom Fahrer ausgewählten Modus (ACC oder GRA_im_ACC) an.";
CM_ SG_ 1719 KBI_Inhalt_Tank "Restmenge 2 bzw. 2,5l nicht auflösbar

";
CM_ SG_ 1719 KBI_Kilometerstand "Fehler wird ausgegeben, falls Kilometerstand nicht restaurierbar
";
CM_ SG_ 1719 KBI_Oelwechsel_durchgefuehrt "Nach einen Ölwechsel (Service) ist die Ethanol Warmfahrwarnung zu unterdrücken.";
CM_ SG_ 1719 KBI_QBit_Aussen_Temp_gef "0x0 = gültiger Wert
0x1 = Ersatz-, Init- oder Fehlerwert";
CM_ SG_ 1719 KBI_RDK_Kalibrier_Anf "Bei gesetztem Bit soll die RDK die aktuellen Istdrücke zu Solldrücken übernehmen (nur bei Nichtverbau einer Headunit erforderlich).";
CM_ SG_ 1719 KBI_Reserve_Warnung_Sek "Signalisiert die Reservewarnung für die Energiespeicher CNG, LPG, HV-Batterie.
Fahrer wird gewarnt, dass er den Reservebereich erreicht hat. Fzg.spezifische Warnschwelle.";
CM_ SG_ 1719 KBI_Standzeit_02 "Zähler welcher die Standzeit des Motors wiedergibt.
Das Signal beschreibt den Anteil der Motor-Standzeit zwischen Zündung aus und nächstem Motorstart.";

CM_ SG_ 1720 KBI_BCmE_aktiv "Anzeige BCmE aktiv (BCmE-Screen oder Einsparhinweis in der Anzeige)";
CM_ SG_ 1720 KBI_GAP_Warn_Zeit_abgelaufen "Die Zeit, z.B. 1460 Tage, bis zur finalen Warnstufe der Gasanlagenprüfung wurde berechnet. Berechnung erfolgt auf Basis der aktuellen Uhrzeit mit einem Tageszähler. Keine Berechnung des Zählers bei Kl.30 AUS.";
CM_ SG_ 1720 KBI_Max_Tankinhalt "Mitteilung des maximalen Tankinhalts an das Reichweitenmodul";
CM_ SG_ 1720 KBI_Nachtanken_erkannt "Statusinformation Nachtankmodus";
CM_ SG_ 1720 KBI_Quittierung_cAQP "Quittierungsbestätigung vom Fahrer für Funktion cAQP";
CM_ SG_ 1720 KBI_Quittierung_Naesse "Quittierungsbestätigung vom Fahrer";
CM_ SG_ 1720 KBI_Reifenumfang "Mittlerer Radumfang aus der K-Zahl gerechnet in Millimeter.  Byte 2 Bit 5,4 reserviert, Byte 2 Bit 3..0 und Byte 1 Bit 7..0; Wertebereich 0..4096 mm
";
CM_ SG_ 1720 KBI_Reifenumfang_Sekundaer "Fahrzeuge mit unterschiedlichen Reifenumfängen Vorderachse / Hinterachse:

Primärachse: KBI_Reifenumfang
Sekundärachse: KBI_Reifenumfang_Sekundaer
";
CM_ SG_ 1720 KBI_Sparhinweis_quittiert "angezeigter Sparhinweis ist quittiert. Signal wird nach zwei Sendebotschaften wieder auf '0' gesetzt.";
CM_ SG_ 1720 KBI_Tankfuellstand_Prozent "Tankfüllstand in %";
CM_ SG_ 1720 KBI_Tankinhalt_hochaufl "angezeigter Tankinhalt hochauflösend zur Restreichweitenberechnung";
CM_ SG_ 1720 KBI_Variante "Zeigt an ob es sich um ein konventionelles Zeiger-Kombiinstrument handelt oder um eine Volldisplay-Kombiinstrument";
CM_ SG_ 1720 KBI_Variante_USA "In diesem Signal wird die HW-Variante des Kombis ausgegeben, ACC plausibilisiert auf dieses Signal hin seine US-Codierung";

CM_ SG_ 2621440277 KS_Airbag_01_Req_FD_Data "Komponentenschutz über ISO TP.";

CM_ SG_ 2621571349 KS_Airbag_01_Resp_FD_Data "Komponentenschutz über ISO TP.";

CM_ SG_ 810 EPS_01_CRC "Für MLB:
'Berechnung siehe Lastenheft 'Kommunikationsabsicherung für FlexRay und CAN''

Ab MQB und MLBevo:
'Berechnung siehe Lastenheft 'End-to-End Kommunikationsabsicherung''

Endwerte siehe Begleitdokument 'S-PDU Kennungsfolgen'
";
CM_ SG_ 810 EPS_Akustiksignal "Ansteuerung eines Akustiksignals im Kombi";
CM_ SG_ 810 EPS_Anf_KL "Nach Überschreiten einer oberen Grenztemperatur innerhalb des Steuergerätes der Lenkhilfe fordert die EPS die Zuschaltung einer externen Kühlung durch den Kühlerlüfter an.
Es besteht kein technischer Zusammenhang mit einer Batterie_ab - Erkennung in der ";
CM_ SG_ 810 EPS_ARA_Status "Anforderung vom Anhängerrangierassistent. 
16 Statuswerte";
CM_ SG_ 810 EPS_Charisma_FahrPr "MLBevo: Aktuelles Fahrprogramm des Charisma-Teilnehmers (siehe Systemlastenheft Drive Select)
MQB: Istwert der Kennlinie (siehe Systemlastenheft MQB FPA)";
CM_ SG_ 810 EPS_Charisma_Status "Rückmeldung an den Charisma-Master

Wert 0x3 ist nur für Fahrzeuge ab MQB relevant";
CM_ SG_ 810 EPS_Endanschlag "Die EPS muss applikativ ein Lenkhubmapping umsetzen. Das Lenkhubmapping muss für jeden NR-Reglerstatus den Defaultendanschlag oder die Lenkhubaufweitung zuordnen.";
CM_ SG_ 810 EPS_Fehlerlampe "Steuert direkt die Fehlerlampe Lenkhilfe (gelb); kein Aufprüfen bei Neustart, keine Rückleseinformation in Kombi-Botschaft (nur für VW526 Hybrid)";
CM_ SG_ 810 EPS_Lenkerposition "Position des Lenkers im Fahrzeug";
CM_ SG_ 810 EPS_PLA_Abbruch "Art des Fehlers ohne Eintrag, 16 Werte möglich (siehe LH EPS/PLA)";
CM_ SG_ 810 EPS_PLA_Fehler "Art des Fehlers ohne Eintrag, 16 Werte möglich (siehe LH EPS/PLA)";
CM_ SG_ 810 EPS_PLA_Status "Zustand der Statusmaschine der EPS für die korrespondierenden Statusmaschine im PLA.";
CM_ SG_ 810 EPS_SpannungsAnf "Forderung des EPS-SG's zur Spannungsanhebung.";
CM_ SG_ 810 EPS_VZ_Zst_Offset_Geradeaus "Vorzeichen des Offset Geradeauslauf gem. Schnittstellenbeschreibung Lenkhilfe";
CM_ SG_ 810 EPS_Warnungen "Diese Bits werden verwendet, um im Kombi Texte, Lampen oder Bilder für die Lenkhilfe darzustellen
Audi MLB/RSe:
Text_1: Lenkung defekt (Prio 1)
Text_2: Lenkung Systemstörung (Prio 2)
VW526:
Text_1 (ID_TXT_1026.1): Ausfall Lenkunterstützung
Text_2 (I";
CM_ SG_ 810 EPS_Zst_Offset_Geradeaus "Lenkungsinterner Offset Geradeauslauf Nutzung gemaess Schnittstellendokumentation Lenkhilfe";

CM_ SG_ 285 EPS_02_CRC "Für MLB:
'Berechnung siehe Lastenheft 'Kommunikationsabsicherung für FlexRay und CAN''

Ab MQB und MLBevo:
'Berechnung siehe Lastenheft 'End-to-End Kommunikationsabsicherung''

Endwerte siehe Begleitdokument 'S-PDU Kennungsfolgen'
";
CM_ SG_ 285 EPS_Drehzahlreserve "Signal beschreibt wieviel Drehzahlreserve in EPS besteht (abhängig von Bordnetzspannung)";
CM_ SG_ 285 EPS_Lastinfo "entspricht Stromaufnahme des Lenkhilfe-SG, Auflösung = 1A";
CM_ SG_ 285 EPS_Leistungsanforderung "Signal informiert BEM, daß EPS einen erhöhten Leistungs-/Spannungsbedarf hat";
CM_ SG_ 285 EPS_Motorstartverzoegerung "Das Signal gibt eine Empfehlung, ob der Motorstart verzögert werden sollte. Es beschreibt aber kein Motorstartverbot. Der Motor darf trotz gesetztem Bit einen Motorstart vollziehen.";
CM_ SG_ 285 EPS_Notlauf "Bit-Feld zeigt an, dass sich die Lenkhilfe in einem Notlaufprogramm 
befindet und durch welche Ursache dieses aktiviert wurde; 
das Betriebsverhalten der Lenkhilfe wird an das bestehende Defizit angepasst.

Erläuterung Notlauf-Ursachen:

- Unterspan";
CM_ SG_ 285 EPS_StartStopp_Info "Das Signal gibt eine Motorstoppempfehlung für StartStop. 
Bei einem zu großem Handlenkmoment von X Nm wird eine Empfehlung ausgesprochen keinen Motorstopp durchzuführen.";
CM_ SG_ 285 EPS_Unterstuetzungsleistung "Die Unterstützungsleistung gibt prozentual an, in welchem Verhältnis die tatsächlich abgegebene Leistung zur Nominalleistung steht, d.h.:

0% = keine Servounterstützung

100% = maximale Servounterstützung (Nominalleistung);

0% < Unterstützungsleist";
CM_ SG_ 285 EPS_Versorgungsspannung "Gibt die am Steuergerät anliegende Spannung aus.
";
CM_ SG_ 285 EPS_VZ_Drehzahlreserve "Vorzeichen zur Drehzahlsreserve";
CM_ SG_ 285 EPS_Warmstartunterstuetzung "Erweiterte Spannungsanforderung für den Start-Stopp-Wiederstart";

CM_ SG_ 159 EPS_03_CRC "Für MLB:
'Berechnung siehe Lastenheft 'Kommunikationsabsicherung für FlexRay und CAN''

Ab MQB und MLBevo:
'Berechnung siehe Lastenheft 'End-to-End Kommunikationsabsicherung''

Endwerte siehe Begleitdokument 'S-PDU Kennungsfolgen'";
CM_ SG_ 159 EPS_AWA_Status "beschreibt den Status der AWA-Funktion im EPS-Steuergerät. (Ausweich-Assistent)";
CM_ SG_ 159 EPS_Berechneter_LW "Berechneter Lenkradwinkel (BLW)
MLB: Ausgabe des berechneten Lenkwinkels mit Geradeauslaufkorrektur aus der Position des Lenkmotors (Absolutwert)
MQB: Ausgabe des berechneten Lenkwinkels aus der Position des Lenkmotors (Absolutwert) und ggf. unter Berüc";
CM_ SG_ 159 EPS_BLW_QBit "beschreibt die Qualität/Vertrauenswürdigkeit des berechneten LW";
CM_ SG_ 159 EPS_DSR_Status "Interner DSR-Status des EPS-Steuergerätes";
CM_ SG_ 159 EPS_HCA_Status "Beschreibt den Status der HCA-Funktion im EPS-Steuergerät.";
CM_ SG_ 159 EPS_Lenkmoment "Gibt das durch den Momentensensor detektiertes Lenkhandmoment (Absolutmoment) aus

Wertebereich von 0x321 - 0x3FD reserviert (z.Zt. nicht bedient)";
CM_ SG_ 159 EPS_Lenkungstyp "Signal beschreibt den eingebauten Lenkungstyp. Enthält z. B. implizit auch die Information, welche Ritzelübersetzung verbaut ist. Wichtig für die Regelsysteme HCA und DSR.
Im MQB gilt das 'EPS LH CAN-Schnittstelle'.";
CM_ SG_ 159 EPS_VZ_BLW "Vorzeichen Berechneter Lenkwinkel

(für EPS_Berechneter_LW)";
CM_ SG_ 159 EPS_VZ_Lenkmoment "Vorzeichen Lenkhandmoment";

CM_ SG_ 110 EPS_05_BZ "4bit Botschaftszähler, wird mit jeder Sendebotschaft inkrementiert";
CM_ SG_ 110 EPS_05_CRC "Für MLB:
Berechnung siehe Lastenheft 'Kommunikationsabsicherung für FlexRay und CAN'
Ab MQB und MLBevo:
Berechnung siehe Lastenheft 'End-to-End Kommunikationsabsicherung'

Endwerte siehe Begleitdokument 'S-PDU Kennungsfolgen'";
CM_ SG_ 110 EPS_QBit_Zahnstangen_Grad "QBit zum Signal EPS_Zahnstangen_Grad";
CM_ SG_ 110 EPS_QBit_Zahnstangen_Pos "beschreibt die Qualität/Vertrauenswürdigkeit der Zahnstangenposition";
CM_ SG_ 110 EPS_Sensorikstatus "Status des Sensors";
CM_ SG_ 110 EPS_VZ_Zahnstangen_Grad "Vorzeichen Zahnstangengradient";
CM_ SG_ 110 EPS_VZ_Zahnstangenposition "Vorzeichen der Position/Verschiebung der Zahnstange bzgl. Lenkungsmitte
Vorzeichen:
(Fahreransicht: positiv = links von der Nullstellung des Lenkrades)
Nullstellung = +0mm";
CM_ SG_ 110 EPS_Zahnstangen_Grad "Zahnstangengeschwindigkeit";
CM_ SG_ 110 EPS_Zahnstangen_Pos_02 "Position der Zahnstange des Lenkgetriebes in mm";
CM_ SG_ 110 SOK_LH_EPS_05_Signatur "Signatur im Rahmen der durch SOK geschützen Broadcast-Kommunikation

Geschützte Funktion: FAS-Systeme, Bremse-Funktionen
Geschützte Botschaft: LH_EPS_05";

CM_ SG_ 981 BCM1_Abblendlicht_Anf "Anforderung Abblendlicht
";
CM_ SG_ 981 BCM1_Adaptive_Lichtvert_Anf "Funktion 'Adaptive Lichtverteilung' im AFS-SG  Ein- und Ausschalten";
CM_ SG_ 981 BCM1_Allwetterlicht_Anf "Anforderung eines Allwetterlichts (über AFS-SG realisiert): Licht für schlechte Sichtverhältnisse";
CM_ SG_ 981 BCM1_Animationssperrung "Sperrung der Scheinwerfer- und Heckleuchten-Animationen. Grund für Sperrung sind allgemeine Rahmenbedingungen, wie beispielseweise eine LDS-Stellung ungleich 'Auto'";
CM_ SG_ 981 BCM1_Autobahnlicht_Anf "Anforderung Autobahnlicht
";
CM_ SG_ 981 BCM1_CH_aktiv "Coming Home (zusätzlich zum Signal 'BCM1_CH_LH_aktiv' in der Botschaft BCM1_01)";
CM_ SG_ 981 BCM1_CH_LH_aktiv "Status Comming / Leaving Home
";
CM_ SG_ 981 BCM1_Fernlicht_Anf "Anforderung Fernlicht
";
CM_ SG_ 981 BCM1_Gleitende_Leuchtw_Anf "Funktion 'Gleitende Leuchtweite' im AFS-SG  freischalten";
CM_ SG_ 981 BCM1_GLW_Fernlicht_Anf "Harte Fernlichtanforderung von BCM1 an die Funktion 'gleitende Leuchtweite' im AFS-SG";
CM_ SG_ 981 BCM1_Kurvenlicht_links_Anf "Ansteuerung linkes Kurvenlicht/Abbiegelicht duch BCM1";
CM_ SG_ 981 BCM1_Kurvenlicht_rechts_Anf "Ansteuerung rechtes Kurvenlicht/Abbiegelicht duch BCM1";
CM_ SG_ 981 BCM1_LH_aktiv "Leaving Home (zusätzlich zum Signal 'BCM1_CH_LH_aktiv' in der Botschaft BCM1_01)";
CM_ SG_ 981 BCM1_Nebellicht_Anf "Anforderung Nebellicht
";
CM_ SG_ 981 BCM1_Nebelschluss_Ahg_Anf "Anforderung: Nebelschlusslicht Anhänger (Sollzustand)
";
CM_ SG_ 981 BCM1_Nebelschluss_Fzg_Anf "Anforderung: Nebelschlusslicht Fahrzeug (Sollzustand)";
CM_ SG_ 981 BCM1_Parklicht_li_Anf "Anforderung: Parklicht links (Sollzustand)
";
CM_ SG_ 981 BCM1_Parklicht_re_Anf "Anforderung: Parklicht rechts (Sollzustand)
";
CM_ SG_ 981 BCM1_Regenlicht_Anf "Anforderung: Regenlicht (Sollzustand)
";
CM_ SG_ 981 BCM1_Schlusslicht_Anf "Anforderung: Schlusslicht Fahrzeug (Sollzustand)
";
CM_ SG_ 981 BCM1_Signaturlicht_Anf "Signal zur Anforderung des Signaturlichts";
CM_ SG_ 981 BCM1_Standlicht_Anf "Anforderung: Schlusslicht (Sollzustand)";
CM_ SG_ 981 BCM1_Tagfahrlicht_Anf "Anforderung: Tagfahrlicht (Sollzustand)";
CM_ SG_ 981 BCM1_Touristen_Licht_Anf "Anforderung: Touristenlicht (Sollzustand)";
CM_ SG_ 981 BCM1_Umfeldleuchten_Anf "Anforderung für Umfeldleuchten";
CM_ SG_ 981 BCM_Rueckfahrlicht_Anf "Anforderung Rückfahrlicht (Sollzustand). 
Das Signal wird entprellt (typisch 400ms) und bei KL15EIN gesendet. Das Signal ist unabhängig von der Position des Heckdeckels (kein Überhitzungsschutz).";
CM_ SG_ 981 Licht_Anf_01_BZ "4bit Botschaftszaehler, wird mit jeder Sendebotschaft inkrementiert";
CM_ SG_ 981 Licht_Anf_01_CRC "Für MLB:
'Berechnung siehe Lastenheft 'Kommunikationsabsicherung für FlexRay und CAN''

Ab MQB und MLBevo:
'Berechnung siehe Lastenheft 'End-to-End Kommunikationsabsicherung''

Endwerte siehe Begleitdokument 'S-PDU Kennungsfolgen'";
CM_ SG_ 981 TFL_Matrix_Variante01_Anf "Gibt die einzustellende Variante der Tagfahrlicht-Matrix an.";
CM_ SG_ 981 TFL_Matrix_Variante02_Anf "Gibt die einzustellende Variante der Tagfahrlicht-Matrix an.";
CM_ SG_ 981 TFL_Matrix_Variante03_Anf "Gibt die einzustellende Variante der Tagfahrlicht-Matrix an.";
CM_ SG_ 981 TFL_Matrix_Variante04_Anf "Gibt die einzustellende Variante der Tagfahrlicht-Matrix an.";

CM_ SG_ 982 BCM2_Bremsl_durch_ECD "Bremslicht (ECD-Bremsung)
";
CM_ SG_ 982 BCM2_Bremsl_durch_ECD_invers "Inversbit Bremslicht (ECD-Bremsung) (Kommunikationsabsicherung)";
CM_ SG_ 982 LH_3_Bremsl_def "Fehlerstatus 3. Bremsleuchte
";
CM_ SG_ 982 LH_Aussenlicht_def "Aussenlicht kann nicht mehr korrekt angesteuert werden (EEPROM Codierung kann nicht mehr ausgelesen werden)
";
CM_ SG_ 982 LH_Blinker_HL_akt "Blinker hinten links
";
CM_ SG_ 982 LH_Blinker_HR_akt "Blinker hinten rechts
";
CM_ SG_ 982 LH_Blinker_li_def "Fehlerstatus Blinker hinten links
";
CM_ SG_ 982 LH_Blinker_re_def "Fehlerstatus Blinker hinten rechts
";
CM_ SG_ 982 LH_Brems_Blk_li_def "Konfiguration BRL + BLK links 
";
CM_ SG_ 982 LH_Brems_Blk_re_def "Konfiguration BRL + BLK rechts
";
CM_ SG_ 982 LH_Bremsl_li_def "Fehlerstatus Bremslicht hinten links (Detektion Einzelausfall)
";
CM_ SG_ 982 LH_Bremsl_li_ges_def "Fehlerstatus Bremslicht hinten links (Detektion Totalausfall)
";
CM_ SG_ 982 LH_Bremsl_re_def "Fehlerstatus Bremslicht hinten rechts  (Detektion Einzelausfall)
";
CM_ SG_ 982 LH_Bremsl_re_ges_def "Fehlerstatus Bremslicht hinten rechts (Detektion Totalausfall)";
CM_ SG_ 982 LH_Bremslicht_H_aktiv "Bremslicht hinten
";
CM_ SG_ 982 LH_Diag_LED_li_def "Heckleuchte links defekt";
CM_ SG_ 982 LH_Diag_LED_re_def "Heckleuchte rechts defekt";
CM_ SG_ 982 LH_Diag_Status_li_def "Außenlicht Diagnose 
Systemstörung links";
CM_ SG_ 982 LH_Diag_Status_re_def "Außenlicht Diagnose Systemstörung rechts ";
CM_ SG_ 982 LH_Kennzl_def "Fehlerstatus Kennzeichenbeleuchtung hinten
";
CM_ SG_ 982 LH_Nebel_li_def "Fehlererkennung Nebelschlusslicht hinten links";
CM_ SG_ 982 LH_Nebel_mi_def "Fehlererkennung Nebelschlusslicht hinten Mitte


";
CM_ SG_ 982 LH_Nebel_re_def "Fehlererkennung Nebelschlusslicht hinten rechts
";
CM_ SG_ 982 LH_Nebelschluss_aktiv "Nebelschlusslicht
";
CM_ SG_ 982 LH_Parklicht_HL_aktiv "Parklicht hinten links 
";
CM_ SG_ 982 LH_Parklicht_HR_aktiv "Parklicht hinten rechts 
";
CM_ SG_ 982 LH_Rueckf_li_def "Fehlererkennung Rückfahrlicht hinten links
";
CM_ SG_ 982 LH_Rueckf_mi_def "Fehlererkennung Rückfahrlicht Mitte
";
CM_ SG_ 982 LH_Rueckf_re_def "Fehlererkennung Rückfahrlicht hinten rechts
";
CM_ SG_ 982 LH_Rueckfahrlicht_aktiv "Rueckfahrlicht";
CM_ SG_ 982 LH_Schluss_Brems_li_def "Konfiguration SL+ BRL + PL links und SL+ BRL  links
";
CM_ SG_ 982 LH_Schluss_Brems_Nebel_li_def "Signal wird gesetzt, wenn eine Unterbrechung oder  ein Kurzschluss am Lampenausgang für Schluss_Brems_Nebelschlusslicht erkannt wird.";
CM_ SG_ 982 LH_Schluss_Brems_Nebel_re_def "Signal wird gesetzt, wenn eine Unterbrechung oder  ein Kurzschluss am Lampenausgang für Schluss_Brems_Nebelschlusslicht erkannt wird.";
CM_ SG_ 982 LH_Schluss_Brems_re_def "Konfiguration SL+ BRL + PL rechts und SL+ BRL  rechts
";
CM_ SG_ 982 LH_Schluss_Nebel_li_def "Konfiguration SL + NSL links oder SL + NSL + PL links
";
CM_ SG_ 982 LH_Schluss_Nebel_re_def "Konfiguration SL + NSL rechts oder SL + NSL + PL rechts
";
CM_ SG_ 982 LH_Schlusslicht_li_def "Fehlererkennung Schlusslicht hinten links
";
CM_ SG_ 982 LH_Schlusslicht_re_def "Fehlererkennung Schlusslicht hinten rechts";
CM_ SG_ 982 LH_SL_BRL_BLK_li_def "Konfiguration SL + BRL + BLK links oder SL + BRL + BLK + PL links
";
CM_ SG_ 982 LH_SL_BRL_BLK_re_def "Konfiguration SL + BRL + BLK rechts oder SL + BRL + BLK + PL rechts
";
CM_ SG_ 982 LH_Standlicht_H_aktiv "Standlicht hinten
";
CM_ SG_ 982 LH_Zusatzschlussl_def "mindestens ein Zusatzschlusslicht in der Heckbeleuchtung defekt.";
CM_ SG_ 982 Licht_hinten_01_BZ "überlaufender 4bit Botschaftszaehler; wird in jeder Sendebotschaft inkrementiert";

CM_ SG_ 134 LWI_01_CRC "Für MLB:
'Berechnung siehe Lastenheft 'Kommunikationsabsicherung für FlexRay und CAN''

Ab MQB und MLBevo:
'Berechnung siehe Lastenheft 'End-to-End Kommunikationsabsicherung'

Endwerte siehe Begleitdokument 'S-PDU Kennungsfolgen'";
CM_ SG_ 134 LWI_Lenkradw_Geschw "Wertebereich = +/- 2500 Grad/s
Auflösung = 5 Grad/s

Hinweis: Zusätzlich gestellte Winkel bei Dynamiklenkung beachten !";
CM_ SG_ 134 LWI_Lenkradwinkel "Wertebereich = +/- 800 Grad
Auflösung = 0,1 Grad
ACHTUNG: spezifizierte Interne Auflösung des Sensors beträgt aber nur Schrittweite 0,5 Grad!

Hinweis:
MLB: Zusätzlich gestellte Winkel bei Dynamiklenkung beachten !
MQB: Nicht konstante Lenkübersetzu";
CM_ SG_ 134 LWI_QBit_Lenkradwinkel "Das QBit wird auch bei nicht abgeglichenem Lenkradwinkelsensor gesetzt";
CM_ SG_ 134 LWI_QBit_Sub_Daten "Es gilt die Signalspezifikation laut LAH";
CM_ SG_ 134 LWI_Sub_Daten "Verschlüsseltes Datenpaket vom Sub-Rechner des LWS, Verwendung nur durch SCU und ESP_ADS
Verwendung gemäß 'Sicherheitsanforderungen an Empfängersteuergeräte'

Im MLB gilt die Signalspezifikation: LAH 8K0953B
Im MLBevo gilt die Signalspezifikation LAH.";
CM_ SG_ 134 LWI_VZ_Lenkradw_Geschw "Vorzeichen Lenkradwinkelgeschwindigkeit gemäss DIN70000; 
Nullstellung = +0";
CM_ SG_ 134 LWI_VZ_Lenkradwinkel "Vorzeichen Lenkradwinkel gemäss DIN70000; 
Nullstellung = +0";

CM_ SG_ 2463978889 Mem_BFS_Fond_03_BZ "4bit Botschaftszähler, wird mit jeder Sendebotschaft inkrementiert";
CM_ SG_ 2463978889 Mem_BFS_Fond_03_CRC "Für MLB:
Berechnung siehe Lastenheft 'Kommunikationsabsicherung für FlexRay und CAN'
Ab MQB und MLBevo:
Berechnung siehe Lastenheft 'End-to-End Kommunikationsabsicherung'

Endwerte siehe Begleitdokument 'S-PDU Kennungsfolgen'";
CM_ SG_ 2463978889 Mem_HBFSFo_Abschaltanf_SRAB "Lehnenwinkel SRAB HBFS";
CM_ SG_ 2463978889 Mem_HBFSFo_Anzeige_Komfort_HBFS "Meldung Komfortposition überschritten HBFS";
CM_ SG_ 2463978889 Mem_HBFSFo_ARMTuer_aktiv "Verstellung Armlehne Tuer";
CM_ SG_ 2463978889 Mem_HBFSFo_ARMTunnel_aktiv "Verstellung Armlehne  Tunnel";
CM_ SG_ 2463978889 Mem_HBFSFo_BANV_aktiv "Verstellung Beinauflageneigung";
CM_ SG_ 2463978889 Mem_HBFSFo_BATV_aktiv "Verstellung Beinauflagentiefe";
CM_ SG_ 2463978889 Mem_HBFSFo_EE_Entriegl_Motor "EasyEntry Entriegelungsmotor rechts";
CM_ SG_ 2463978889 Mem_HBFSFo_EE_Verr_Sensor_re "EasyEntry Verriegelungssensor rechts außen";
CM_ SG_ 2463978889 Mem_HBFSFo_globaler_Lehnenwinkel "globaler Lehnenwinkel HBFS";
CM_ SG_ 2463978889 Mem_HBFSFo_globaler_Sitzflachenw "globaler Sitzflächenwinkel HBFS";
CM_ SG_ 2463978889 Mem_HBFSFo_KSV_aktiv "Verstellung Kopfstütze";
CM_ SG_ 2463978889 Mem_HBFSFo_LED_EA_Taster "EasyEntry Taster rechts LED Rotanzeige";
CM_ SG_ 2463978889 Mem_HBFSFo_LKV_aktiv "Verstellung Lehnenkopf";
CM_ SG_ 2463978889 Mem_HBFSFo_LNV_aktiv "Verstellung Lehnenneigung";
CM_ SG_ 2463978889 Mem_HBFSFo_SHV_aktiv "Verstellung Sitzhöhe";
CM_ SG_ 2463978889 Mem_HBFSFo_SLV_aktiv "Sitzlängsverstellung";
CM_ SG_ 2463978889 Mem_HBFSFo_SLV_hinten "SLV rechts (hinterste Position)";
CM_ SG_ 2463978889 Mem_HBFSFo_SNV_aktiv "Verstellung Sitzneigung";
CM_ SG_ 2463978889 Mem_HBFSFo_Sperre_Sitzdisplay "Aufforderung MCC4-ABT Sperre/Kindersicherung HBFS zu aktivieren, durch Betätigung Hardkey HBFS für kindgerechte Sitzposition";
CM_ SG_ 2463978889 Mem_HBFSFo_Status_Schalter_Ki_Si "Status Schalter HBFS an ZAE";
CM_ SG_ 2463978889 Mem_HBFSFo_Stoerung "Störung des HBFS-Sitz-SG an Kombi";
CM_ SG_ 2463978889 Mem_HBFSFo_STV_aktiv "Verstellung Sitztiefe";
CM_ SG_ 2463978889 Mem_HBFSFo_Verr_Sensor_oben_re "Lehne oben rechts (Verriegelung)";
CM_ SG_ 2463978889 Mem_HBFSFo_Verr_Sensor_unten_re "Lehne unten rechts (Verriegelung)";
CM_ SG_ 2463978889 Mem_HBFSFo_Warnung_Softstop "HMI Warnung nach Softstop Lehnenverstellung";

CM_ SG_ 2463978890 Mem_FS_Fond_03_BZ "4bit Botschaftszähler, wird mit jeder Sendebotschaft inkrementiert";
CM_ SG_ 2463978890 Mem_FS_Fond_03_CRC "Für MLB:
Berechnung siehe Lastenheft 'Kommunikationsabsicherung für FlexRay und CAN'
Ab MQB und MLBevo:
Berechnung siehe Lastenheft 'End-to-End Kommunikationsabsicherung'

Endwerte siehe Begleitdokument 'S-PDU Kennungsfolgen'";
CM_ SG_ 2463978890 Mem_HFSFo_Abschaltanf_SRAB "Lehnenwinkel SRAB HFS";
CM_ SG_ 2463978890 Mem_HFSFo_Anzeige_Komfort_HFS "Meldung Komfortposition überschritten HFS";
CM_ SG_ 2463978890 Mem_HFSFo_ARMTuer_aktiv "Verstellung Armlehne Tuer";
CM_ SG_ 2463978890 Mem_HFSFo_ARMTunnel_aktiv "Verstellung Armlehne Tunnel";
CM_ SG_ 2463978890 Mem_HFSFo_BANV_aktiv "Verstellung Beinauflageneigung";
CM_ SG_ 2463978890 Mem_HFSFo_BATV_aktiv "Verstellung Beinauflagentiefe";
CM_ SG_ 2463978890 Mem_HFSFo_EA_Position "Sitz links EA Position";
CM_ SG_ 2463978890 Mem_HFSFo_EE_Verr_Sensor_li "EasyEntry Verriegelungssensor links außen & innen";
CM_ SG_ 2463978890 Mem_HFSFo_globaler_Lehnenwinkel "globaler Lehnenwinkel HFS";
CM_ SG_ 2463978890 Mem_HFSFo_globaler_Sitzflachenwi "globaler Sitzflächenwinkel HFS";
CM_ SG_ 2463978890 Mem_HFSFo_KSV_aktiv "Verstellung Kopfstütze";
CM_ SG_ 2463978890 Mem_HFSFo_LED_EA_Taster "EasyEntry Taster links LED Rotanzeige";
CM_ SG_ 2463978890 Mem_HFSFo_LKV_aktiv "Verstellung Lehnenkopf";
CM_ SG_ 2463978890 Mem_HFSFo_LNV_aktiv "Verstellung Lehnenneigung";
CM_ SG_ 2463978890 Mem_HFSFo_SHV_aktiv "Verstellung Sitzhöhe";
CM_ SG_ 2463978890 Mem_HFSFo_SLV_aktiv "Sitzlängsverstellung";
CM_ SG_ 2463978890 Mem_HFSFo_SLV_hinten "SLV links (hinterste Position)";
CM_ SG_ 2463978890 Mem_HFSFo_SNV_aktiv "Verstellung Sitzneigung";
CM_ SG_ 2463978890 Mem_HFSFo_Sperre_Sitzdisplay "Aufforderung MCC4-ABT Sperre/Kindersicherung HFS zu aktivieren, durch Betätigung Hardkey HFS für kindgerechte Sitzposition";
CM_ SG_ 2463978890 Mem_HFSFo_Status_Schalter_Ki_Si "Status Schalter HFS an ZAE";
CM_ SG_ 2463978890 Mem_HFSFo_Stoerung "Störung des HFS-Sitz-SG an Kombi";
CM_ SG_ 2463978890 Mem_HFSFo_STV_aktiv "Verstellung Sitztiefe";
CM_ SG_ 2463978890 Mem_HFSFo_Verr_Sensor_oben_li "Lehne oben links (Verriegelung)";
CM_ SG_ 2463978890 Mem_HFSFo_Verr_Sensor_unten_li "Lehne unten links (Verriegelung)";
CM_ SG_ 2463978890 Mem_HFSFo_Warnung_Softstop "HMI Warnung nach Softstop Lehnenverstellung";

CM_ SG_ 245 MFDR_01_BZ "4bit Botschaftszähler, wird mit jeder Sendebotschaft inkrementiert";
CM_ SG_ 245 MFDR_01_CRC "Für MLB:
Berechnung siehe Lastenheft 'Kommunikationsabsicherung für FlexRay und CAN'
Ab MQB und MLBevo:
Berechnung siehe Lastenheft 'End-to-End Kommunikationsabsicherung'

Endwerte siehe Begleitdokument 'S-PDU Kennungsfolgen'";
CM_ SG_ 245 MFDR_01_Sendestatus "Gibt den Sendestatus der Botschaft MFDR_01 an (notwendig für IL-Unterstützung)";
CM_ SG_ 245 MFDR_Active_DCC "Status ob im mFDR dieDCC-Teilfunktion zur Verfügung steht.";
CM_ SG_ 245 MFDR_Beschleunigung_yAchse "Beschleunigungswert in y-Achse, bezogen auf den Schwerpunkt
Positive Werte: Linkskurve";
CM_ SG_ 245 MFDR_DeltaKuppMom_Soll_L "Solldeltamoment an der Kupplung kommandiert vom mFDR. Postive Werte erhöhen entsprechend das linke Kupplungsmoment, niedrigere Werte reduzieren das linke Kupplungsmoment.";
CM_ SG_ 245 MFDR_DeltaKuppMom_Soll_R "Solldeltamoment an der Kupplung kommandiert vom mFDR. Postive Werte erhöhen entsprechend das rechte Kupplungsmoment, niedrigere Werte reduzieren das rechte Kupplungsmoment.";
CM_ SG_ 245 MFDR_Kurvenrichtung "Anzeigen der Kurvenrichtung
0 Linkskurve
1 Rechtskurve
2 Init
3 Fehler";
CM_ SG_ 245 MFDR_Offset_DCC_HL "Signal zur Generierung eines Strom-Offsets im DCC";
CM_ SG_ 245 MFDR_Offset_DCC_HR "Signal zur Generierung eines Strom-Offsets im DCC";
CM_ SG_ 245 MFDR_Offset_DCC_VL "Signal zur Generierung eines Strom-Offsets im DCC";
CM_ SG_ 245 MFDR_Offset_DCC_VR "Signal zur Generierung eines Strom-Offsets im DCC";
CM_ SG_ 245 MFDR_Sollfaktor_DCC_HL "Signal zur Modulation der Dämpferhärte in Abhängigkeit der Querdynamik";
CM_ SG_ 245 MFDR_Sollfaktor_DCC_HR "Signal zur Modulation der Dämpferhärte in Abhängigkeit der Querdynamik";
CM_ SG_ 245 MFDR_Sollfaktor_DCC_VL "Signal zur Modulation der Dämpferhärte in Abhängigkeit der Querdynamik";
CM_ SG_ 245 MFDR_Sollfaktor_DCC_VR "Signal zur Modulation der Dämpferhärte in Abhängigkeit der Querdynamik";
CM_ SG_ 245 MFDR_UnterUebersteuern "-1 … 0 Untersteuern (Aus Gierratenabweichung)
0 … 1 Übersteuern (Aus Gierratenabweichung)";

CM_ SG_ 1471 MFL_Eventcode_1 "Siehe Q-LAH MFL-Protokoll";
CM_ SG_ 1471 MFL_Eventcode_2 "Siehe Q-LAH MFL-Protokoll";
CM_ SG_ 1471 MFL_Marke "Marke für markenspezifische Variantennummer des MFL";
CM_ SG_ 1471 MFL_Tastencode_1 "Beschreibt die Funktion einer fest zugeordneten Taste/Walze auf dem MFL. Bei Betätigung ändert sich der Wert von 0x0 auf den jeweiligen Tastencode.";
CM_ SG_ 1471 MFL_Tastencode_2 "Beschreibt die Funktion einer fest zugeordneten Taste/Walze auf dem MFL. Ist MFL_Tastencode_1 wegen Betätigung einer Taste/Walze bereits mit einem Wert ungleich 0x0 belegt, so ändert sich bei Betätigung einer weiteren Taste/Walze der Wert dieses Signals v";
CM_ SG_ 1471 MFL_Variante "Markenspezifische Variantennummer des MFL";

CM_ SG_ 1600 MO_Absperrventil_oeffnen "Signal an Klima-SG das Absperrrventil anzusteuern. Ab D4 auch 0x3 Ventil_schließen.

Im MQB wird hier der Soll-Status des Absperrventils ausgegeben.
Achtung: bei z. B. klemmendem Ventil entspricht das Signal nicht dem tatsächlichen Status!";
CM_ SG_ 1600 MO_aktives_Getriebeheizen "Information für Getriebe, ob ein Ventil für Getriebheizen angesteuert werden muss";
CM_ SG_ 1600 MO_Ansaugluft_Temp "In Fahrzeugen ohne Außentemperatur vom Kombi kann aus der Ansauglufttemperatur auf die Außentemperatur geschlossen werden. Beim SDI ist das mit einer gewissen Genauigkeit gegeben. Genutzt wird es vom ASG.";
CM_ SG_ 1600 MO_Getriebe_kuehlen "Anforderung Getriebekühlventilansteuerung";
CM_ SG_ 1600 MO_Heizungspumpenansteuerung "Anforderung Heizungspumpenansteuerung
MQB und Hybrid: Status der Heizungsunterstützungspumpe am MSG
";
CM_ SG_ 1600 MO_Hoeheninfo "Korrekturfaktor Höhe (1 entspricht 1013 mbar)";
CM_ SG_ 1600 MO_HYB_Fehler_HV_Netz "Im HV-Bordnetz ist fehlerbedingt kein generatorischer Betrieb möglich. Das 12V-Bordnetz wird über den DC/DC-Wandler allein aus der Traktionsbatterie gespeist. Um diesen Zustand möglichst lange aufrechterhalten zu können, sollten Komfort-Verbraucher abgesc";
CM_ SG_ 1600 MO_Kennfeldk "Die Kennfeldkühlung ist in diesem Fahrzeug verbaut und hat keinen Systemfehler";
CM_ SG_ 1600 MO_KL15_Abschaltempfehlung "Kessy Abschaltempfehlung nach Verlassen des Fahrzeugs";
CM_ SG_ 1600 MO_Kuehlmittel_Temp "Kuehlmitteltemperatur";
CM_ SG_ 1600 MO_Mom_Traegheit_02 "Massenträgheit (J) der Motors bzw. der Antriebsmaschinen in kgm².

Zur Berücksichtigung des E-Motor in Hybrid-Projekten:
in MLB-Projekten wird nur der J-Wert des Verbrennungsmotors und nicht der J-Wert des E-Motors berücksichtigt.
In MQB/MLBevo-Projek";
CM_ SG_ 1600 MO_Nachlaufzeit_Heizungspumpe "Nachlaufzeit für Heizungspumpe für Turboladerschutz";
CM_ SG_ 1600 MO_Oel_Temp "Realer Meßbereich ca. -40..150 Grad";
CM_ SG_ 1600 MO_QBit_Ansaugluft_Temp "
";
CM_ SG_ 1600 MO_QBit_Hoeheninfo "Qualifizierungsbit der Höheninfo. Gesetzt bei Ersatzwert, Init oder Fehler.";
CM_ SG_ 1600 MO_QBit_Kuehlmittel_Temp "
";
CM_ SG_ 1600 MO_SpannungsAnf "Forderung des Motor-SGs zur Spannungsanhebung";
CM_ SG_ 1600 MO_Versionsinfo_02 "Versioninformation vom Motor zur Steuerung bei inkompatiblen KMatrix-Änderung bzw. Einführung von neuen Funktionen, die in den Empfängern verriegelt werden müssen. Zu jedem Ereignis wird ein fixer Zählerstand zugeordnet, um dem Empfänger die funktionale Ä";
BA_DEF_REL_ BU_SG_REL_  "GenSigTimeoutTime" INT 0 65535;
BA_DEF_ BO_  "DiagRequest" ENUM "No", "Yes";
BA_DEF_ BO_  "DiagResponse" ENUM "No", "Yes";
BA_DEF_ BO_  "DiagState" ENUM "No", "Yes";
BA_DEF_ BO_  "GenMsgChkConstant" HEX 0 4095;
BA_DEF_ BO_  "GenMsgCycleTime" INT 0 65535;
BA_DEF_ BO_  "GenMsgCycleTimeFast" INT 0 65535;
BA_DEF_ BO_  "GenMsgDelayTime" INT 0 100000;
BA_DEF_ BO_  "GenMsgILSupport" ENUM "No", "Yes";
BA_DEF_ BO_  "GenMsgNrOfRepetition" INT 0 100;
BA_DEF_ BO_  "GenMsgPDUConstants" STRING;
BA_DEF_ BO_  "GenMsgSendType" ENUM "Cyclic", "not_used", "not_used", "not_used", "not_used", "not_used", "not_used", "IfActive", "NoMsgSendType";
BA_DEF_ BO_  "GenMsgStartDelayTime" INT 0 100000;
BA_DEF_ BO_  "NmMessage" ENUM "No", "Yes";
BA_DEF_ BO_  "NmhMessage" ENUM "No", "Yes";
BA_DEF_ BO_  "MsgType" ENUM "Application", "NM ", "NMH", "TP2.0", "ISO-TP ", "BAP", "EID", "KS", "XCP_PRE_CONFIGURED", "XCP_RUNTIME_CONFIGURED";
BA_DEF_ BO_  "VAGTP20_API" HEX 0 255;
BA_DEF_ BO_  "VAGTP20_DynConnection" ENUM "No", "Yes";
BA_DEF_ BO_  "VAGTP20_DynSetup" ENUM "No", "Yes";
BA_DEF_ BO_  "VAGTP20_StatConnection" ENUM "No", "Yes";
BA_DEF_ BO_  "CANFD_BRS" ENUM "0", "1";
BA_DEF_ BO_  "VFrameFormat" ENUM "StandardCAN", "ExtendedCAN", "reserved", "reserved", "reserved", "reserved", "reserved", "reserved", "reserved", "reserved", "reserved", "reserved", "reserved", "reserved", "StandardCAN_FD", "ExtendedCAN_FD";
BA_DEF_ SG_  "GenSigActiveRepetitions" INT -2147483648 2147483647;
BA_DEF_ SG_  "GenSigInactiveValue" INT -2147483648 2147483647;
BA_DEF_ SG_  "GenSigSendType" ENUM "Cyclic", "OnWrite", "OnWriteWithRepetition", "OnChange", "OnChangeWithRepetition", "IfActive", "IfActiveWithRepetition", "NoSigSendType", "OnChangeAndIfActive", "OnChangeAndIfActiveWithRepetition";
BA_DEF_ SG_  "GenSigStartValue" INT -2147483648 2147483647;
BA_DEF_ SG_  "NWM-WakeupAllowed" ENUM "No", "Yes";
BA_DEF_ SG_  "GenSigFuncType" ENUM "NoFunction", "MsgCounter", "CRC-8", "XOR", "XOR-2", "DatedBit", "SW-Kl15", "CHK", "Constant", "Protocol", "CRC-8-SAE_J1850", "CRC-32", "DataLength", "DataID", "MsgCounter16", "SOK-Signatur", "Cluster";
BA_DEF_ SG_  "GenSigSwitchedByIgnition" ENUM "No", "Yes";
BA_DEF_ SG_  "Fehlerwert" HEX 0 2147483647;
BA_DEF_ SG_  "GenSigMissingSourceValue" HEX 0 2147483647;
BA_DEF_DEF_REL_  "GenSigTimeoutTime" 0;
BA_DEF_DEF_  "DiagRequest" "No";
BA_DEF_DEF_  "DiagResponse" "No";
BA_DEF_DEF_  "DiagState" "No";
BA_DEF_DEF_  "GenMsgChkConstant" 0;
BA_DEF_DEF_  "GenMsgCycleTime" 0;
BA_DEF_DEF_  "GenMsgCycleTimeFast" 0;
BA_DEF_DEF_  "GenMsgDelayTime" 0;
BA_DEF_DEF_  "GenMsgILSupport" "No";
BA_DEF_DEF_  "GenMsgNrOfRepetition" 0;
BA_DEF_DEF_  "GenMsgPDUConstants" "";
BA_DEF_DEF_  "GenMsgSendType" "NoMsgSendType";
BA_DEF_DEF_  "GenMsgStartDelayTime" 0;
BA_DEF_DEF_  "NmMessage" "No";
BA_DEF_DEF_  "NmhMessage" "No";
BA_DEF_DEF_  "MsgType" "Application";
BA_DEF_DEF_  "VAGTP20_API" 0;
BA_DEF_DEF_  "VAGTP20_DynConnection" "No";
BA_DEF_DEF_  "VAGTP20_DynSetup" "No";
BA_DEF_DEF_  "VAGTP20_StatConnection" "No";
BA_DEF_DEF_  "CANFD_BRS" "1";
BA_DEF_DEF_  "VFrameFormat" "StandardCAN";
BA_DEF_DEF_  "GenSigActiveRepetitions" 0;
BA_DEF_DEF_  "GenSigInactiveValue" 0;
BA_DEF_DEF_  "GenSigSendType" "NoSigSendType";
BA_DEF_DEF_  "GenSigStartValue" 0;
BA_DEF_DEF_  "NWM-WakeupAllowed" "No";
BA_DEF_DEF_  "GenSigFuncType" "NoFunction";
BA_DEF_DEF_  "GenSigSwitchedByIgnition" "Yes";
BA_DEF_DEF_  "Fehlerwert" 0;
BA_DEF_DEF_  "GenSigMissingSourceValue" 0;
BA_ "GenMsgCycleTime" BO_ 2549088271 500;
BA_ "GenMsgILSupport" BO_ 2549088271 1;
BA_ "GenMsgSendType" BO_ 2549088271 0;
BA_ "VFrameFormat" BO_ 2549088271 15;
BA_ "GenMsgCycleTime" BO_ 2549088370 500;
BA_ "GenMsgILSupport" BO_ 2549088370 1;
BA_ "GenMsgSendType" BO_ 2549088370 0;
BA_ "VFrameFormat" BO_ 2549088370 15;
BA_ "GenMsgCycleTime" BO_ 2549088315 500;
BA_ "GenMsgILSupport" BO_ 2549088315 1;
BA_ "GenMsgSendType" BO_ 2549088315 0;
BA_ "VFrameFormat" BO_ 2549088315 15;
BA_ "GenMsgCycleTime" BO_ 2549088272 500;
BA_ "GenMsgILSupport" BO_ 2549088272 1;
BA_ "GenMsgSendType" BO_ 2549088272 0;
BA_ "VFrameFormat" BO_ 2549088272 15;
BA_ "GenMsgCycleTime" BO_ 2549088274 500;
BA_ "GenMsgILSupport" BO_ 2549088274 1;
BA_ "GenMsgSendType" BO_ 2549088274 0;
BA_ "VFrameFormat" BO_ 2549088274 15;
BA_ "GenMsgCycleTime" BO_ 779 50;
BA_ "GenMsgILSupport" BO_ 779 1;
BA_ "GenMsgSendType" BO_ 779 0;
BA_ "VFrameFormat" BO_ 779 14;
BA_ "GenMsgCycleTime" BO_ 1719 1000;
BA_ "GenMsgDelayTime" BO_ 1719 100;
BA_ "GenMsgILSupport" BO_ 1719 1;
BA_ "GenMsgSendType" BO_ 1719 0;
BA_ "VFrameFormat" BO_ 1719 14;
BA_ "GenMsgCycleTime" BO_ 1720 1000;
BA_ "GenMsgILSupport" BO_ 1720 1;
BA_ "GenMsgSendType" BO_ 1720 0;
BA_ "VFrameFormat" BO_ 1720 14;
BA_ "MsgType" BO_ 2621440277 4;
BA_ "VFrameFormat" BO_ 2621440277 15;
BA_ "MsgType" BO_ 2621571349 4;
BA_ "VFrameFormat" BO_ 2621571349 15;
BA_ "GenMsgChkConstant" BO_ 810 41;
BA_ "GenMsgCycleTime" BO_ 810 50;
BA_ "GenMsgILSupport" BO_ 810 1;
BA_ "GenMsgPDUConstants" BO_ 810 "0x29,0x29,0x29,0x29,0x29,0x29,0x29,0x29,0x29,0x29,0x29,0x29,0x29,0x29,0x29,0x29";
BA_ "GenMsgSendType" BO_ 810 0;
BA_ "VFrameFormat" BO_ 810 14;
BA_ "GenMsgChkConstant" BO_ 285 28;
BA_ "GenMsgCycleTime" BO_ 285 20;
BA_ "GenMsgILSupport" BO_ 285 1;
BA_ "GenMsgPDUConstants" BO_ 285 "0x1c,0x1c,0x1c,0x1c,0x1c,0x1c,0x1c,0x1c,0x1c,0x1c,0x1c,0x1c,0x1c,0x1c,0x1c,0x1c";
BA_ "GenMsgSendType" BO_ 285 0;
BA_ "VFrameFormat" BO_ 285 14;
BA_ "GenMsgChkConstant" BO_ 159 245;
BA_ "GenMsgCycleTime" BO_ 159 10;
BA_ "GenMsgILSupport" BO_ 159 1;
BA_ "GenMsgPDUConstants" BO_ 159 "0xf5,0xf5,0xf5,0xf5,0xf5,0xf5,0xf5,0xf5,0xf5,0xf5,0xf5,0xf5,0xf5,0xf5,0xf5,0xf5";
BA_ "GenMsgSendType" BO_ 159 0;
BA_ "VFrameFormat" BO_ 159 14;
BA_ "GenMsgCycleTime" BO_ 110 5;
BA_ "GenMsgILSupport" BO_ 110 1;
BA_ "GenMsgPDUConstants" BO_ 110 "0xd9,0xb3,0x09,0xa6,0x77,0x68,0xc5,0x85,0xf0,0xf1,0x0d,0xdd,0xad,0x0c,0x0a,0xae";
BA_ "GenMsgSendType" BO_ 110 0;
BA_ "VFrameFormat" BO_ 110 14;
BA_ "GenMsgCycleTime" BO_ 981 100;
BA_ "GenMsgDelayTime" BO_ 981 50;
BA_ "GenMsgILSupport" BO_ 981 1;
BA_ "GenMsgPDUConstants" BO_ 981 "0xc5,0x39,0xc7,0xf9,0x92,0xd8,0x24,0xce,0xf1,0xb5,0x7a,0xc4,0xbc,0x60,0xe3,0xd1";
BA_ "GenMsgSendType" BO_ 981 0;
BA_ "VFrameFormat" BO_ 981 14;
BA_ "GenMsgCycleTime" BO_ 982 100;
BA_ "GenMsgDelayTime" BO_ 982 20;
BA_ "GenMsgILSupport" BO_ 982 1;
BA_ "GenMsgSendType" BO_ 982 0;
BA_ "VFrameFormat" BO_ 982 14;
BA_ "GenMsgChkConstant" BO_ 134 134;
BA_ "GenMsgCycleTime" BO_ 134 10;
BA_ "GenMsgILSupport" BO_ 134 1;
BA_ "GenMsgPDUConstants" BO_ 134 "0x86,0x86,0x86,0x86,0x86,0x86,0x86,0x86,0x86,0x86,0x86,0x86,0x86,0x86,0x86,0x86";
BA_ "GenMsgSendType" BO_ 134 0;
BA_ "VFrameFormat" BO_ 134 14;
BA_ "GenMsgCycleTime" BO_ 2463978889 200;
BA_ "GenMsgDelayTime" BO_ 2463978889 50;
BA_ "GenMsgILSupport" BO_ 2463978889 1;
BA_ "GenMsgPDUConstants" BO_ 2463978889 "0xb9,0x10,0x32,0xe5,0x9c,0x92,0x71,0x3d,0x4d,0x6d,0x46,0x18,0xa9,0xf3,0x7d,0x37";
BA_ "GenMsgSendType" BO_ 2463978889 0;
BA_ "VFrameFormat" BO_ 2463978889 15;
BA_ "GenMsgCycleTime" BO_ 2463978890 200;
BA_ "GenMsgDelayTime" BO_ 2463978890 50;
BA_ "GenMsgILSupport" BO_ 2463978890 1;
BA_ "GenMsgPDUConstants" BO_ 2463978890 "0xba,0xd2,0x62,0x4e,0x72,0xe8,0x4b,0xd9,0x35,0x68,0x92,0x0d,0x5d,0xae,0xf6,0x50";
BA_ "GenMsgSendType" BO_ 2463978890 0;
BA_ "VFrameFormat" BO_ 2463978890 15;
BA_ "GenMsgCycleTime" BO_ 245 10;
BA_ "GenMsgCycleTimeFast" BO_ 245 5;
BA_ "GenMsgILSupport" BO_ 245 1;
BA_ "GenMsgNrOfRepetition" BO_ 245 5;
BA_ "GenMsgPDUConstants" BO_ 245 "0xb9,0x36,0xea,0x3b,0x68,0xe0,0x8c,0x5f,0xe7,0x31,0x49,0x30,0x77,0xee,0x08,0x18";
BA_ "GenMsgSendType" BO_ 245 0;
BA_ "VFrameFormat" BO_ 245 14;
BA_ "GenMsgCycleTimeFast" BO_ 1471 1000;
BA_ "GenMsgDelayTime" BO_ 1471 30;
BA_ "GenMsgILSupport" BO_ 1471 1;
BA_ "GenMsgNrOfRepetition" BO_ 1471 5;
BA_ "VFrameFormat" BO_ 1471 14;
BA_ "GenMsgCycleTime" BO_ 1600 500;
BA_ "GenMsgILSupport" BO_ 1600 1;
BA_ "GenMsgSendType" BO_ 1600 0;
BA_ "VFrameFormat" BO_ 1600 14;
BA_ "GenSigSendType" SG_ 2549088271 Allrad_Abschaltstufe 0;
BA_ "GenSigSendType" SG_ 2549088271 Allrad_KompSchutz 0;
BA_ "GenSigSendType" SG_ 2549088271 Allrad_Nachlauftyp 0;
BA_ "GenSigSendType" SG_ 2549088271 Allrad_Transport_Mode 0;
BA_ "GenSigSendType" SG_ 2549088271 ALR_KD_Fehler 0;
BA_ "GenSigSendType" SG_ 2549088271 KN_Allrad_BusKnockOutTimer 0;
BA_ "GenSigSwitchedByIgnition" SG_ 2549088271 KN_Allrad_BusKnockOutTimer 0;
BA_ "GenSigSendType" SG_ 2549088271 KN_ALR_DiagPfad 0;
BA_ "GenSigSwitchedByIgnition" SG_ 2549088271 KN_ALR_DiagPfad 0;
BA_ "GenSigSendType" SG_ 2549088370 Daempfer_Abschaltstufe 0;
BA_ "GenSigSendType" SG_ 2549088370 Daempfer_KompSchutz 0;
BA_ "GenSigSendType" SG_ 2549088370 Daempfer_Nachlauftyp 0;
BA_ "GenSigStartValue" SG_ 2549088370 Daempfer_Nachlauftyp 2;
BA_ "GenSigSendType" SG_ 2549088370 Daempfer_Transport_Mode 0;
BA_ "GenSigSendType" SG_ 2549088370 DR_KD_Fehler 0;
BA_ "GenSigSendType" SG_ 2549088370 KN_DR_DiagPfad 0;
BA_ "GenSigSwitchedByIgnition" SG_ 2549088370 KN_DR_DiagPfad 0;
BA_ "GenSigSendType" SG_ 2549088370 NM_Daempfer_Wakeup 0;
BA_ "GenSigSwitchedByIgnition" SG_ 2549088370 NM_Daempfer_Wakeup 0;
BA_ "GenSigSendType" SG_ 2549088315 EBKV_Abschaltstufe 0;
BA_ "GenSigSwitchedByIgnition" SG_ 2549088315 EBKV_Abschaltstufe 0;
BA_ "GenSigSendType" SG_ 2549088315 EBKV_KD_Fehler 0;
BA_ "GenSigSwitchedByIgnition" SG_ 2549088315 EBKV_KD_Fehler 0;
BA_ "GenSigSendType" SG_ 2549088315 EBKV_KompSchutz 0;
BA_ "GenSigSwitchedByIgnition" SG_ 2549088315 EBKV_KompSchutz 0;
BA_ "GenSigSendType" SG_ 2549088315 EBKV_Nachlauftyp 0;
BA_ "GenSigStartValue" SG_ 2549088315 EBKV_Nachlauftyp 2;
BA_ "GenSigSwitchedByIgnition" SG_ 2549088315 EBKV_Nachlauftyp 0;
BA_ "GenSigSendType" SG_ 2549088315 EBKV_Transport_Mode 0;
BA_ "GenSigSwitchedByIgnition" SG_ 2549088315 EBKV_Transport_Mode 0;
BA_ "GenSigSendType" SG_ 2549088315 KN_EBKV_BusKnockOut 0;
BA_ "GenSigSwitchedByIgnition" SG_ 2549088315 KN_EBKV_BusKnockOut 0;
BA_ "GenSigSendType" SG_ 2549088315 KN_EBKV_BusKnockOutTimer 0;
BA_ "GenSigSwitchedByIgnition" SG_ 2549088315 KN_EBKV_BusKnockOutTimer 0;
BA_ "GenSigSendType" SG_ 2549088315 KN_EBKV_DiagPfad 0;
BA_ "GenSigSwitchedByIgnition" SG_ 2549088315 KN_EBKV_DiagPfad 0;
BA_ "GenSigSendType" SG_ 2549088315 KN_EBKV_ECUKnockOut 0;
BA_ "GenSigSwitchedByIgnition" SG_ 2549088315 KN_EBKV_ECUKnockOut 0;
BA_ "GenSigSendType" SG_ 2549088315 KN_EBKV_ECUKnockOutTimer 0;
BA_ "GenSigSwitchedByIgnition" SG_ 2549088315 KN_EBKV_ECUKnockOutTimer 0;
BA_ "GenSigSendType" SG_ 2549088315 NM_EBKV_Lokalaktiv 0;
BA_ "GenSigSwitchedByIgnition" SG_ 2549088315 NM_EBKV_Lokalaktiv 0;
BA_ "GenSigSendType" SG_ 2549088315 NM_EBKV_Subsystemaktiv 0;
BA_ "GenSigSwitchedByIgnition" SG_ 2549088315 NM_EBKV_Subsystemaktiv 0;
BA_ "GenSigSendType" SG_ 2549088315 NM_EBKV_Wakeup 0;
BA_ "NWM-WakeupAllowed" SG_ 2549088315 NM_EBKV_Wakeup 1;
BA_ "GenSigSwitchedByIgnition" SG_ 2549088315 NM_EBKV_Wakeup 0;
BA_ "GenSigSendType" SG_ 2549088272 Gateway_Abschaltstufe 0;
BA_ "GenSigSwitchedByIgnition" SG_ 2549088272 Gateway_Abschaltstufe 0;
BA_ "GenSigSendType" SG_ 2549088272 Gateway_KompSchutz 0;
BA_ "GenSigSwitchedByIgnition" SG_ 2549088272 Gateway_KompSchutz 0;
BA_ "GenSigSendType" SG_ 2549088272 Gateway_Nachlauftyp 0;
BA_ "GenSigStartValue" SG_ 2549088272 Gateway_Nachlauftyp 2;
BA_ "GenSigSwitchedByIgnition" SG_ 2549088272 Gateway_Nachlauftyp 0;
BA_ "GenSigSendType" SG_ 2549088272 Gateway_Transport_Mode 0;
BA_ "GenSigSwitchedByIgnition" SG_ 2549088272 Gateway_Transport_Mode 0;
BA_ "GenSigSendType" SG_ 2549088272 GW_KD_Fehler 0;
BA_ "GenSigSendType" SG_ 2549088272 KN_GW_DiagPfad 0;
BA_ "GenSigSwitchedByIgnition" SG_ 2549088272 KN_GW_DiagPfad 0;
BA_ "GenSigSendType" SG_ 2549088272 NM_Gateway_Wakeup 0;
BA_ "NWM-WakeupAllowed" SG_ 2549088272 NM_Gateway_Wakeup 1;
BA_ "GenSigSwitchedByIgnition" SG_ 2549088272 NM_Gateway_Wakeup 0;
BA_ "GenSigSendType" SG_ 2549088274 EPS_KD_Fehler 0;
BA_ "GenSigSwitchedByIgnition" SG_ 2549088274 EPS_KD_Fehler 0;
BA_ "GenSigSendType" SG_ 2549088274 KN_EPS_DiagPfad 0;
BA_ "GenSigSwitchedByIgnition" SG_ 2549088274 KN_EPS_DiagPfad 0;
BA_ "GenSigSendType" SG_ 2549088274 Lenkhilfe_Abschaltstufe 0;
BA_ "GenSigSwitchedByIgnition" SG_ 2549088274 Lenkhilfe_Abschaltstufe 0;
BA_ "GenSigSendType" SG_ 2549088274 Lenkhilfe_KompSchutz 0;
BA_ "GenSigSwitchedByIgnition" SG_ 2549088274 Lenkhilfe_KompSchutz 0;
BA_ "GenSigSendType" SG_ 2549088274 Lenkhilfe_Nachlauftyp 0;
BA_ "GenSigStartValue" SG_ 2549088274 Lenkhilfe_Nachlauftyp 2;
BA_ "GenSigSwitchedByIgnition" SG_ 2549088274 Lenkhilfe_Nachlauftyp 0;
BA_ "GenSigSendType" SG_ 2549088274 Lenkhilfe_Transport_Mode 0;
BA_ "GenSigSwitchedByIgnition" SG_ 2549088274 Lenkhilfe_Transport_Mode 0;
BA_ "GenSigSendType" SG_ 2549088274 NM_EPS_Wakeup 0;
BA_ "NWM-WakeupAllowed" SG_ 2549088274 NM_EPS_Wakeup 1;
BA_ "GenSigSwitchedByIgnition" SG_ 2549088274 NM_EPS_Wakeup 0;
BA_ "GenSigSendType" SG_ 779 KBI_ABS_Lampe 0;
BA_ "GenSigSwitchedByIgnition" SG_ 779 KBI_ABS_Lampe 0;
BA_ "GenSigSendType" SG_ 779 KBI_Airbag_Lampe 0;
BA_ "GenSigSwitchedByIgnition" SG_ 779 KBI_Airbag_Lampe 0;
BA_ "GenSigSendType" SG_ 779 KBI_angez_Geschw 0;
BA_ "GenSigSwitchedByIgnition" SG_ 779 KBI_angez_Geschw 0;
BA_ "GenSigSendType" SG_ 779 KBI_Anzeigefehler_LDW 0;
BA_ "GenSigSwitchedByIgnition" SG_ 779 KBI_Anzeigefehler_LDW 0;
BA_ "GenSigSendType" SG_ 779 KBI_Anzeigefehler_NV 0;
BA_ "GenSigSwitchedByIgnition" SG_ 779 KBI_Anzeigefehler_NV 0;
BA_ "GenSigSendType" SG_ 779 KBI_Anzeigefehler_SWA 0;
BA_ "GenSigSwitchedByIgnition" SG_ 779 KBI_Anzeigefehler_SWA 0;
BA_ "GenSigSendType" SG_ 779 KBI_Anzeigestatus_ACC 0;
BA_ "GenSigSwitchedByIgnition" SG_ 779 KBI_Anzeigestatus_ACC 0;
BA_ "GenSigSendType" SG_ 779 KBI_Anzeigestatus_GRA 0;
BA_ "GenSigSwitchedByIgnition" SG_ 779 KBI_Anzeigestatus_GRA 0;
BA_ "Fehlerwert" SG_ 779 KBI_Anzeigestatus_GRA 3;
BA_ "GenSigSendType" SG_ 779 KBI_Anzeigestatus_LIM 0;
BA_ "GenSigSwitchedByIgnition" SG_ 779 KBI_Anzeigestatus_LIM 0;
BA_ "Fehlerwert" SG_ 779 KBI_Anzeigestatus_LIM 3;
BA_ "GenSigSendType" SG_ 779 KBI_Anzeigestatus_RHP 0;
BA_ "GenSigSwitchedByIgnition" SG_ 779 KBI_Anzeigestatus_RHP 0;
BA_ "GenSigSendType" SG_ 779 KBI_ARA_in_Anzeige 0;
BA_ "GenSigSwitchedByIgnition" SG_ 779 KBI_ARA_in_Anzeige 0;
BA_ "GenSigSendType" SG_ 779 KBI_Audioabsenkung_MIB 0;
BA_ "GenSigSwitchedByIgnition" SG_ 779 KBI_Audioabsenkung_MIB 0;
BA_ "GenSigSendType" SG_ 779 KBI_Bestaetigung_ESP_Off 0;
BA_ "GenSigSwitchedByIgnition" SG_ 779 KBI_Bestaetigung_ESP_Off 0;
BA_ "GenSigSendType" SG_ 779 KBI_BKL_Lampe 0;
BA_ "GenSigSwitchedByIgnition" SG_ 779 KBI_BKL_Lampe 0;
BA_ "GenSigSendType" SG_ 779 KBI_ESP_Lampe 0;
BA_ "GenSigSwitchedByIgnition" SG_ 779 KBI_ESP_Lampe 0;
BA_ "GenSigSendType" SG_ 779 KBI_Fehler_Anzeige_ACC 0;
BA_ "GenSigSwitchedByIgnition" SG_ 779 KBI_Fehler_Anzeige_ACC 0;
BA_ "GenSigSendType" SG_ 779 KBI_Handbremse 0;
BA_ "GenSigSwitchedByIgnition" SG_ 779 KBI_Handbremse 0;
BA_ "GenSigSendType" SG_ 779 KBI_im_Stellgliedtest 0;
BA_ "GenSigSwitchedByIgnition" SG_ 779 KBI_im_Stellgliedtest 0;
BA_ "GenSigSendType" SG_ 779 KBI_Konsistenz_ACC 0;
BA_ "GenSigSwitchedByIgnition" SG_ 779 KBI_Konsistenz_ACC 0;
BA_ "GenSigSendType" SG_ 779 KBI_Lenkung_Lampe 0;
BA_ "GenSigSwitchedByIgnition" SG_ 779 KBI_Lenkung_Lampe 0;
BA_ "GenSigSendType" SG_ 779 KBI_MFA_v_Einheit_01 0;
BA_ "GenSigSwitchedByIgnition" SG_ 779 KBI_MFA_v_Einheit_01 0;
BA_ "GenSigSendType" SG_ 779 KBI_NV_in_Anzeige 0;
BA_ "GenSigSwitchedByIgnition" SG_ 779 KBI_NV_in_Anzeige 0;
BA_ "GenSigSendType" SG_ 779 KBI_Oeldruck_Schalter 0;
BA_ "GenSigSwitchedByIgnition" SG_ 779 KBI_Oeldruck_Schalter 0;
BA_ "GenSigSendType" SG_ 779 KBI_Oeldruckwarnung 0;
BA_ "GenSigSwitchedByIgnition" SG_ 779 KBI_Oeldruckwarnung 0;
BA_ "GenSigSendType" SG_ 779 KBI_PLA_in_Anzeige 0;
BA_ "GenSigSwitchedByIgnition" SG_ 779 KBI_PLA_in_Anzeige 0;
BA_ "GenSigSendType" SG_ 779 KBI_SILA_gueltig 0;
BA_ "GenSigSwitchedByIgnition" SG_ 779 KBI_SILA_gueltig 0;
BA_ "GenSigSendType" SG_ 779 KBI_Systemstatus 0;
BA_ "GenSigSwitchedByIgnition" SG_ 779 KBI_Systemstatus 0;
BA_ "GenSigSendType" SG_ 779 KBI_Tankwarnung 0;
BA_ "GenSigSwitchedByIgnition" SG_ 779 KBI_Tankwarnung 0;
BA_ "GenSigSendType" SG_ 779 KBI_Tankwarnung_ungueltig 0;
BA_ "GenSigStartValue" SG_ 779 KBI_Tankwarnung_ungueltig 1;
BA_ "GenSigSwitchedByIgnition" SG_ 779 KBI_Tankwarnung_ungueltig 0;
BA_ "GenSigSendType" SG_ 779 KBI_Taster_Fahrwerk 0;
BA_ "GenSigSwitchedByIgnition" SG_ 779 KBI_Taster_Fahrwerk 0;
BA_ "GenSigSendType" SG_ 779 KBI_Taster_Lift 0;
BA_ "GenSigSwitchedByIgnition" SG_ 779 KBI_Taster_Lift 0;
BA_ "GenSigSendType" SG_ 779 KBI_V_Digital 0;
BA_ "GenSigSwitchedByIgnition" SG_ 779 KBI_V_Digital 0;
BA_ "GenSigSendType" SG_ 779 KBI_Vorglueh_System_Lampe 0;
BA_ "GenSigSwitchedByIgnition" SG_ 779 KBI_Vorglueh_System_Lampe 0;
BA_ "GenSigSendType" SG_ 779 Kombi_01_BZ 0;
BA_ "GenSigFuncType" SG_ 779 Kombi_01_BZ 1;
BA_ "GenSigSwitchedByIgnition" SG_ 779 Kombi_01_BZ 0;
BA_ "GenSigSendType" SG_ 1719 KBI_aktive_Laengsfunktion_02 3;
BA_ "GenSigSendType" SG_ 1719 KBI_Aussen_Temp_gef 0;
BA_ "GenSigStartValue" SG_ 1719 KBI_Aussen_Temp_gef 254;
BA_ "GenSigSwitchedByIgnition" SG_ 1719 KBI_Aussen_Temp_gef 0;
BA_ "Fehlerwert" SG_ 1719 KBI_Aussen_Temp_gef 255;
BA_ "GenSigSendType" SG_ 1719 KBI_FoD_PopUP_Quittiert 3;
BA_ "GenSigSendType" SG_ 1719 KBI_FStatus_Tank 0;
BA_ "GenSigSwitchedByIgnition" SG_ 1719 KBI_FStatus_Tank 0;
BA_ "GenSigSendType" SG_ 1719 KBI_GRA_im_ACC 3;
BA_ "GenSigSwitchedByIgnition" SG_ 1719 KBI_GRA_im_ACC 0;
BA_ "GenSigSendType" SG_ 1719 KBI_Inhalt_Tank 0;
BA_ "GenSigStartValue" SG_ 1719 KBI_Inhalt_Tank 126;
BA_ "GenSigSwitchedByIgnition" SG_ 1719 KBI_Inhalt_Tank 0;
BA_ "Fehlerwert" SG_ 1719 KBI_Inhalt_Tank 127;
BA_ "GenSigSendType" SG_ 1719 KBI_Kilometerstand 0;
BA_ "GenSigStartValue" SG_ 1719 KBI_Kilometerstand 1048574;
BA_ "GenSigSwitchedByIgnition" SG_ 1719 KBI_Kilometerstand 0;
BA_ "Fehlerwert" SG_ 1719 KBI_Kilometerstand 1048575;
BA_ "GenSigSendType" SG_ 1719 KBI_Oelwechsel_durchgefuehrt 0;
BA_ "GenSigSwitchedByIgnition" SG_ 1719 KBI_Oelwechsel_durchgefuehrt 0;
BA_ "GenSigSendType" SG_ 1719 KBI_QBit_Aussen_Temp_gef 0;
BA_ "GenSigStartValue" SG_ 1719 KBI_QBit_Aussen_Temp_gef 1;
BA_ "GenSigSwitchedByIgnition" SG_ 1719 KBI_QBit_Aussen_Temp_gef 0;
BA_ "GenSigSendType" SG_ 1719 KBI_RDK_Kalibrier_Anf 3;
BA_ "GenSigSwitchedByIgnition" SG_ 1719 KBI_RDK_Kalibrier_Anf 0;
BA_ "GenSigSendType" SG_ 1719 KBI_Reserve_Warnung_Sek 3;
BA_ "GenSigSwitchedByIgnition" SG_ 1719 KBI_Reserve_Warnung_Sek 0;
BA_ "GenSigSendType" SG_ 1719 KBI_Standzeit_02 0;
BA_ "GenSigStartValue" SG_ 1719 KBI_Standzeit_02 131070;
BA_ "GenSigSwitchedByIgnition" SG_ 1719 KBI_Standzeit_02 0;
BA_ "Fehlerwert" SG_ 1719 KBI_Standzeit_02 131071;
BA_ "GenSigSendType" SG_ 1720 KBI_BCmE_aktiv 0;
BA_ "GenSigSwitchedByIgnition" SG_ 1720 KBI_BCmE_aktiv 0;
BA_ "GenSigSendType" SG_ 1720 KBI_GAP_Warn_Zeit_abgelaufen 0;
BA_ "GenSigSwitchedByIgnition" SG_ 1720 KBI_GAP_Warn_Zeit_abgelaufen 0;
BA_ "GenSigSendType" SG_ 1720 KBI_Max_Tankinhalt 0;
BA_ "GenSigStartValue" SG_ 1720 KBI_Max_Tankinhalt 254;
BA_ "GenSigSwitchedByIgnition" SG_ 1720 KBI_Max_Tankinhalt 0;
BA_ "Fehlerwert" SG_ 1720 KBI_Max_Tankinhalt 255;
BA_ "GenSigSendType" SG_ 1720 KBI_Nachtanken_erkannt 0;
BA_ "GenSigSwitchedByIgnition" SG_ 1720 KBI_Nachtanken_erkannt 0;
BA_ "GenSigSendType" SG_ 1720 KBI_Quittierung_cAQP 0;
BA_ "GenSigSwitchedByIgnition" SG_ 1720 KBI_Quittierung_cAQP 0;
BA_ "GenSigSendType" SG_ 1720 KBI_Quittierung_Naesse 0;
BA_ "GenSigSwitchedByIgnition" SG_ 1720 KBI_Quittierung_Naesse 0;
BA_ "GenSigSendType" SG_ 1720 KBI_Reifenumfang 0;
BA_ "GenSigFuncType" SG_ 1720 KBI_Reifenumfang 8;
BA_ "GenSigSwitchedByIgnition" SG_ 1720 KBI_Reifenumfang 0;
BA_ "GenSigSendType" SG_ 1720 KBI_Reifenumfang_Sekundaer 0;
BA_ "GenSigSwitchedByIgnition" SG_ 1720 KBI_Reifenumfang_Sekundaer 0;
BA_ "GenSigSendType" SG_ 1720 KBI_Sparhinweis_quittiert 0;
BA_ "GenSigSwitchedByIgnition" SG_ 1720 KBI_Sparhinweis_quittiert 0;
BA_ "GenSigSendType" SG_ 1720 KBI_Tankfuellstand_Prozent 0;
BA_ "GenSigStartValue" SG_ 1720 KBI_Tankfuellstand_Prozent 126;
BA_ "GenSigSwitchedByIgnition" SG_ 1720 KBI_Tankfuellstand_Prozent 0;
BA_ "Fehlerwert" SG_ 1720 KBI_Tankfuellstand_Prozent 127;
BA_ "GenSigSendType" SG_ 1720 KBI_Tankinhalt_hochaufl 0;
BA_ "GenSigStartValue" SG_ 1720 KBI_Tankinhalt_hochaufl 16382;
BA_ "GenSigSwitchedByIgnition" SG_ 1720 KBI_Tankinhalt_hochaufl 0;
BA_ "Fehlerwert" SG_ 1720 KBI_Tankinhalt_hochaufl 16383;
BA_ "GenSigSendType" SG_ 1720 KBI_Variante 0;
BA_ "GenSigSwitchedByIgnition" SG_ 1720 KBI_Variante 0;
BA_ "GenSigSendType" SG_ 1720 KBI_Variante_USA 0;
BA_ "GenSigSwitchedByIgnition" SG_ 1720 KBI_Variante_USA 0;
BA_ "GenSigSendType" SG_ 2621440277 KS_Airbag_01_Req_FD_Data 3;
BA_ "GenSigFuncType" SG_ 2621440277 KS_Airbag_01_Req_FD_Data 9;
BA_ "GenSigSwitchedByIgnition" SG_ 2621440277 KS_Airbag_01_Req_FD_Data 0;
BA_ "GenSigSendType" SG_ 2621571349 KS_Airbag_01_Resp_FD_Data 3;
BA_ "GenSigFuncType" SG_ 2621571349 KS_Airbag_01_Resp_FD_Data 9;
BA_ "GenSigSwitchedByIgnition" SG_ 2621571349 KS_Airbag_01_Resp_FD_Data 0;
BA_ "GenSigSendType" SG_ 810 EPS_01_BZ 0;
BA_ "GenSigFuncType" SG_ 810 EPS_01_BZ 1;
BA_ "GenSigSwitchedByIgnition" SG_ 810 EPS_01_BZ 0;
BA_ "GenSigSendType" SG_ 810 EPS_01_CRC 0;
BA_ "GenSigFuncType" SG_ 810 EPS_01_CRC 2;
BA_ "GenSigSwitchedByIgnition" SG_ 810 EPS_01_CRC 0;
BA_ "GenSigSendType" SG_ 810 EPS_Akustiksignal 0;
BA_ "GenSigSwitchedByIgnition" SG_ 810 EPS_Akustiksignal 0;
BA_ "GenSigSendType" SG_ 810 EPS_Anf_KL 0;
BA_ "GenSigSwitchedByIgnition" SG_ 810 EPS_Anf_KL 0;
BA_ "GenSigSendType" SG_ 810 EPS_ARA_Status 0;
BA_ "GenSigSwitchedByIgnition" SG_ 810 EPS_ARA_Status 0;
BA_ "GenSigSendType" SG_ 810 EPS_Charisma_FahrPr 0;
BA_ "GenSigSwitchedByIgnition" SG_ 810 EPS_Charisma_FahrPr 0;
BA_ "GenSigSendType" SG_ 810 EPS_Charisma_Status 0;
BA_ "GenSigSwitchedByIgnition" SG_ 810 EPS_Charisma_Status 0;
BA_ "GenSigSendType" SG_ 810 EPS_Endanschlag 0;
BA_ "Fehlerwert" SG_ 810 EPS_Endanschlag 3;
BA_ "GenSigSendType" SG_ 810 EPS_Fehlerlampe 0;
BA_ "GenSigSwitchedByIgnition" SG_ 810 EPS_Fehlerlampe 0;
BA_ "GenSigSendType" SG_ 810 EPS_Lenkerposition 0;
BA_ "GenSigFuncType" SG_ 810 EPS_Lenkerposition 8;
BA_ "GenSigSwitchedByIgnition" SG_ 810 EPS_Lenkerposition 0;
BA_ "GenSigSendType" SG_ 810 EPS_PLA_Abbruch 0;
BA_ "GenSigSwitchedByIgnition" SG_ 810 EPS_PLA_Abbruch 0;
BA_ "GenSigSendType" SG_ 810 EPS_PLA_Fehler 0;
BA_ "GenSigSwitchedByIgnition" SG_ 810 EPS_PLA_Fehler 0;
BA_ "GenSigSendType" SG_ 810 EPS_PLA_Status 0;
BA_ "GenSigSwitchedByIgnition" SG_ 810 EPS_PLA_Status 0;
BA_ "GenSigSendType" SG_ 810 EPS_SpannungsAnf 0;
BA_ "GenSigSwitchedByIgnition" SG_ 810 EPS_SpannungsAnf 0;
BA_ "GenSigSendType" SG_ 810 EPS_VZ_Zst_Offset_Geradeaus 0;
BA_ "GenSigSwitchedByIgnition" SG_ 810 EPS_VZ_Zst_Offset_Geradeaus 0;
BA_ "GenSigSendType" SG_ 810 EPS_Warnungen 0;
BA_ "GenSigSwitchedByIgnition" SG_ 810 EPS_Warnungen 0;
BA_ "GenSigSendType" SG_ 810 EPS_Zst_Offset_Geradeaus 0;
BA_ "GenSigStartValue" SG_ 810 EPS_Zst_Offset_Geradeaus 510;
BA_ "GenSigSwitchedByIgnition" SG_ 810 EPS_Zst_Offset_Geradeaus 0;
BA_ "Fehlerwert" SG_ 810 EPS_Zst_Offset_Geradeaus 511;
BA_ "GenSigSendType" SG_ 285 EPS_02_BZ 0;
BA_ "GenSigFuncType" SG_ 285 EPS_02_BZ 1;
BA_ "GenSigSwitchedByIgnition" SG_ 285 EPS_02_BZ 0;
BA_ "GenSigSendType" SG_ 285 EPS_02_CRC 0;
BA_ "GenSigFuncType" SG_ 285 EPS_02_CRC 2;
BA_ "GenSigSwitchedByIgnition" SG_ 285 EPS_02_CRC 0;
BA_ "GenSigSendType" SG_ 285 EPS_Drehzahlreserve 0;
BA_ "GenSigStartValue" SG_ 285 EPS_Drehzahlreserve 126;
BA_ "GenSigSwitchedByIgnition" SG_ 285 EPS_Drehzahlreserve 0;
BA_ "Fehlerwert" SG_ 285 EPS_Drehzahlreserve 127;
BA_ "GenSigSendType" SG_ 285 EPS_Lastinfo 0;
BA_ "GenSigStartValue" SG_ 285 EPS_Lastinfo 254;
BA_ "GenSigSwitchedByIgnition" SG_ 285 EPS_Lastinfo 0;
BA_ "Fehlerwert" SG_ 285 EPS_Lastinfo 255;
BA_ "GenSigSendType" SG_ 285 EPS_Leistungsanforderung 0;
BA_ "GenSigSwitchedByIgnition" SG_ 285 EPS_Leistungsanforderung 0;
BA_ "GenSigSendType" SG_ 285 EPS_Motorstartverzoegerung 0;
BA_ "GenSigSwitchedByIgnition" SG_ 285 EPS_Motorstartverzoegerung 0;
BA_ "GenSigSendType" SG_ 285 EPS_Notlauf 0;
BA_ "GenSigSwitchedByIgnition" SG_ 285 EPS_Notlauf 0;
BA_ "GenSigSendType" SG_ 285 EPS_StartStopp_Info 0;
BA_ "GenSigSwitchedByIgnition" SG_ 285 EPS_StartStopp_Info 0;
BA_ "GenSigSendType" SG_ 285 EPS_Unterstuetzungsleistung 0;
BA_ "GenSigStartValue" SG_ 285 EPS_Unterstuetzungsleistung 254;
BA_ "GenSigSwitchedByIgnition" SG_ 285 EPS_Unterstuetzungsleistung 0;
BA_ "Fehlerwert" SG_ 285 EPS_Unterstuetzungsleistung 255;
BA_ "GenSigSendType" SG_ 285 EPS_Versorgungsspannung 0;
BA_ "GenSigStartValue" SG_ 285 EPS_Versorgungsspannung 254;
BA_ "GenSigSwitchedByIgnition" SG_ 285 EPS_Versorgungsspannung 0;
BA_ "Fehlerwert" SG_ 285 EPS_Versorgungsspannung 255;
BA_ "GenSigSendType" SG_ 285 EPS_VZ_Drehzahlreserve 0;
BA_ "GenSigSwitchedByIgnition" SG_ 285 EPS_VZ_Drehzahlreserve 0;
BA_ "GenSigSendType" SG_ 285 EPS_Warmstartunterstuetzung 0;
BA_ "GenSigSwitchedByIgnition" SG_ 285 EPS_Warmstartunterstuetzung 0;
BA_ "GenSigSendType" SG_ 159 EPS_03_BZ 0;
BA_ "GenSigFuncType" SG_ 159 EPS_03_BZ 1;
BA_ "GenSigSwitchedByIgnition" SG_ 159 EPS_03_BZ 0;
BA_ "GenSigSendType" SG_ 159 EPS_03_CRC 0;
BA_ "GenSigFuncType" SG_ 159 EPS_03_CRC 2;
BA_ "GenSigSwitchedByIgnition" SG_ 159 EPS_03_CRC 0;
BA_ "GenSigSendType" SG_ 159 EPS_AWA_Status 0;
BA_ "GenSigStartValue" SG_ 159 EPS_AWA_Status 14;
BA_ "GenSigSwitchedByIgnition" SG_ 159 EPS_AWA_Status 0;
BA_ "GenSigSendType" SG_ 159 EPS_Berechneter_LW 0;
BA_ "GenSigStartValue" SG_ 159 EPS_Berechneter_LW 4094;
BA_ "GenSigSwitchedByIgnition" SG_ 159 EPS_Berechneter_LW 0;
BA_ "Fehlerwert" SG_ 159 EPS_Berechneter_LW 4095;
BA_ "GenSigSendType" SG_ 159 EPS_BLW_QBit 0;
BA_ "GenSigSwitchedByIgnition" SG_ 159 EPS_BLW_QBit 0;
BA_ "GenSigSendType" SG_ 159 EPS_DSR_Status 0;
BA_ "GenSigSwitchedByIgnition" SG_ 159 EPS_DSR_Status 0;
BA_ "GenSigSendType" SG_ 159 EPS_HCA_Status 0;
BA_ "GenSigStartValue" SG_ 159 EPS_HCA_Status 3;
BA_ "GenSigSwitchedByIgnition" SG_ 159 EPS_HCA_Status 0;
BA_ "GenSigSendType" SG_ 159 EPS_Lenkmoment 0;
BA_ "GenSigStartValue" SG_ 159 EPS_Lenkmoment 1022;
BA_ "GenSigSwitchedByIgnition" SG_ 159 EPS_Lenkmoment 0;
BA_ "Fehlerwert" SG_ 159 EPS_Lenkmoment 1023;
BA_ "GenSigSendType" SG_ 159 EPS_Lenkmoment_QBit 0;
BA_ "GenSigStartValue" SG_ 159 EPS_Lenkmoment_QBit 1;
BA_ "GenSigSwitchedByIgnition" SG_ 159 EPS_Lenkmoment_QBit 0;
BA_ "GenSigSendType" SG_ 159 EPS_Lenkungstyp 0;
BA_ "GenSigStartValue" SG_ 159 EPS_Lenkungstyp 15;
BA_ "GenSigSwitchedByIgnition" SG_ 159 EPS_Lenkungstyp 0;
BA_ "GenSigSendType" SG_ 159 EPS_VZ_BLW 0;
BA_ "GenSigSwitchedByIgnition" SG_ 159 EPS_VZ_BLW 0;
BA_ "GenSigSendType" SG_ 159 EPS_VZ_Lenkmoment 0;
BA_ "GenSigSwitchedByIgnition" SG_ 159 EPS_VZ_Lenkmoment 0;
BA_ "GenSigSendType" SG_ 110 EPS_05_BZ 0;
BA_ "GenSigFuncType" SG_ 110 EPS_05_BZ 1;
BA_ "GenSigSwitchedByIgnition" SG_ 110 EPS_05_BZ 0;
BA_ "GenSigSendType" SG_ 110 EPS_05_CRC 0;
BA_ "GenSigFuncType" SG_ 110 EPS_05_CRC 2;
BA_ "GenSigSwitchedByIgnition" SG_ 110 EPS_05_CRC 0;
BA_ "GenSigSendType" SG_ 110 EPS_QBit_Zahnstangen_Grad 0;
BA_ "GenSigStartValue" SG_ 110 EPS_QBit_Zahnstangen_Grad 1;
BA_ "GenSigSwitchedByIgnition" SG_ 110 EPS_QBit_Zahnstangen_Grad 0;
BA_ "GenSigSendType" SG_ 110 EPS_QBit_Zahnstangen_Pos 0;
BA_ "GenSigSwitchedByIgnition" SG_ 110 EPS_QBit_Zahnstangen_Pos 0;
BA_ "GenSigSendType" SG_ 110 EPS_Sensorikstatus 0;
BA_ "GenSigSwitchedByIgnition" SG_ 110 EPS_Sensorikstatus 0;
BA_ "GenSigSendType" SG_ 110 EPS_VZ_Zahnstangen_Grad 0;
BA_ "GenSigSwitchedByIgnition" SG_ 110 EPS_VZ_Zahnstangen_Grad 0;
BA_ "GenSigSendType" SG_ 110 EPS_VZ_Zahnstangenposition 0;
BA_ "GenSigSwitchedByIgnition" SG_ 110 EPS_VZ_Zahnstangenposition 0;
BA_ "GenSigSendType" SG_ 110 EPS_Zahnstangen_Grad 0;
BA_ "GenSigSwitchedByIgnition" SG_ 110 EPS_Zahnstangen_Grad 0;
BA_ "Fehlerwert" SG_ 110 EPS_Zahnstangen_Grad 32767;
BA_ "GenSigSendType" SG_ 110 EPS_Zahnstangen_Pos_02 0;
BA_ "GenSigStartValue" SG_ 110 EPS_Zahnstangen_Pos_02 32766;
BA_ "GenSigSwitchedByIgnition" SG_ 110 EPS_Zahnstangen_Pos_02 0;
BA_ "Fehlerwert" SG_ 110 EPS_Zahnstangen_Pos_02 32767;
BA_ "GenSigSendType" SG_ 110 SOK_LH_EPS_05_Signatur 0;
BA_ "GenSigFuncType" SG_ 110 SOK_LH_EPS_05_Signatur 15;
BA_ "GenSigSendType" SG_ 981 BCM1_Abblendlicht_Anf 0;
BA_ "GenSigSwitchedByIgnition" SG_ 981 BCM1_Abblendlicht_Anf 0;
BA_ "GenSigSendType" SG_ 981 BCM1_Adaptive_Lichtvert_Anf 0;
BA_ "GenSigSwitchedByIgnition" SG_ 981 BCM1_Adaptive_Lichtvert_Anf 0;
BA_ "GenSigSendType" SG_ 981 BCM1_Allwetterlicht_Anf 0;
BA_ "GenSigSwitchedByIgnition" SG_ 981 BCM1_Allwetterlicht_Anf 0;
BA_ "GenSigSendType" SG_ 981 BCM1_Animationssperrung 3;
BA_ "GenSigStartValue" SG_ 981 BCM1_Animationssperrung 1;
BA_ "GenSigSwitchedByIgnition" SG_ 981 BCM1_Animationssperrung 0;
BA_ "GenSigSendType" SG_ 981 BCM1_Autobahnlicht_Anf 0;
BA_ "GenSigSwitchedByIgnition" SG_ 981 BCM1_Autobahnlicht_Anf 0;
BA_ "GenSigSendType" SG_ 981 BCM1_CH_aktiv 0;
BA_ "NWM-WakeupAllowed" SG_ 981 BCM1_CH_aktiv 1;
BA_ "GenSigSwitchedByIgnition" SG_ 981 BCM1_CH_aktiv 0;
BA_ "GenSigSendType" SG_ 981 BCM1_CH_LH_aktiv 0;
BA_ "GenSigSwitchedByIgnition" SG_ 981 BCM1_CH_LH_aktiv 0;
BA_ "GenSigSendType" SG_ 981 BCM1_Fernlicht_Anf 0;
BA_ "GenSigSwitchedByIgnition" SG_ 981 BCM1_Fernlicht_Anf 0;
BA_ "GenSigSendType" SG_ 981 BCM1_Gleitende_Leuchtw_Anf 0;
BA_ "GenSigSwitchedByIgnition" SG_ 981 BCM1_Gleitende_Leuchtw_Anf 0;
BA_ "GenSigSendType" SG_ 981 BCM1_GLW_Fernlicht_Anf 3;
BA_ "GenSigSwitchedByIgnition" SG_ 981 BCM1_GLW_Fernlicht_Anf 0;
BA_ "GenSigSendType" SG_ 981 BCM1_Kurvenlicht_links_Anf 0;
BA_ "GenSigSwitchedByIgnition" SG_ 981 BCM1_Kurvenlicht_links_Anf 0;
BA_ "GenSigSendType" SG_ 981 BCM1_Kurvenlicht_rechts_Anf 0;
BA_ "GenSigSwitchedByIgnition" SG_ 981 BCM1_Kurvenlicht_rechts_Anf 0;
BA_ "GenSigSendType" SG_ 981 BCM1_LH_aktiv 0;
BA_ "NWM-WakeupAllowed" SG_ 981 BCM1_LH_aktiv 1;
BA_ "GenSigSwitchedByIgnition" SG_ 981 BCM1_LH_aktiv 0;
BA_ "GenSigSendType" SG_ 981 BCM1_Nebellicht_Anf 0;
BA_ "GenSigSwitchedByIgnition" SG_ 981 BCM1_Nebellicht_Anf 0;
BA_ "GenSigSendType" SG_ 981 BCM1_Nebelschluss_Ahg_Anf 0;
BA_ "GenSigSwitchedByIgnition" SG_ 981 BCM1_Nebelschluss_Ahg_Anf 0;
BA_ "GenSigSendType" SG_ 981 BCM1_Nebelschluss_Fzg_Anf 0;
BA_ "GenSigSwitchedByIgnition" SG_ 981 BCM1_Nebelschluss_Fzg_Anf 0;
BA_ "GenSigSendType" SG_ 981 BCM1_Parklicht_li_Anf 0;
BA_ "GenSigSwitchedByIgnition" SG_ 981 BCM1_Parklicht_li_Anf 0;
BA_ "GenSigSendType" SG_ 981 BCM1_Parklicht_re_Anf 0;
BA_ "GenSigSwitchedByIgnition" SG_ 981 BCM1_Parklicht_re_Anf 0;
BA_ "GenSigSendType" SG_ 981 BCM1_Regenlicht_Anf 0;
BA_ "GenSigSwitchedByIgnition" SG_ 981 BCM1_Regenlicht_Anf 0;
BA_ "GenSigSendType" SG_ 981 BCM1_Schlusslicht_Anf 0;
BA_ "GenSigSwitchedByIgnition" SG_ 981 BCM1_Schlusslicht_Anf 0;
BA_ "GenSigSendType" SG_ 981 BCM1_Signaturlicht_Anf 0;
BA_ "GenSigSwitchedByIgnition" SG_ 981 BCM1_Signaturlicht_Anf 0;
BA_ "GenSigSendType" SG_ 981 BCM1_Standlicht_Anf 0;
BA_ "GenSigSwitchedByIgnition" SG_ 981 BCM1_Standlicht_Anf 0;
BA_ "GenSigSendType" SG_ 981 BCM1_Tagfahrlicht_Anf 0;
BA_ "GenSigSwitchedByIgnition" SG_ 981 BCM1_Tagfahrlicht_Anf 0;
BA_ "GenSigSendType" SG_ 981 BCM1_Touristen_Licht_Anf 0;
BA_ "GenSigSwitchedByIgnition" SG_ 981 BCM1_Touristen_Licht_Anf 0;
BA_ "GenSigSendType" SG_ 981 BCM1_Umfeldleuchten_Anf 0;
BA_ "GenSigSwitchedByIgnition" SG_ 981 BCM1_Umfeldleuchten_Anf 0;
BA_ "GenSigSendType" SG_ 981 BCM_Rueckfahrlicht_Anf 0;
BA_ "GenSigSwitchedByIgnition" SG_ 981 BCM_Rueckfahrlicht_Anf 0;
BA_ "GenSigSendType" SG_ 981 Licht_Anf_01_BZ 0;
BA_ "GenSigFuncType" SG_ 981 Licht_Anf_01_BZ 1;
BA_ "GenSigSwitchedByIgnition" SG_ 981 Licht_Anf_01_BZ 0;
BA_ "GenSigSendType" SG_ 981 Licht_Anf_01_CRC 0;
BA_ "GenSigFuncType" SG_ 981 Licht_Anf_01_CRC 2;
BA_ "GenSigSwitchedByIgnition" SG_ 981 Licht_Anf_01_CRC 0;
BA_ "GenSigSendType" SG_ 981 TFL_Matrix_Variante01_Anf 3;
BA_ "GenSigSendType" SG_ 981 TFL_Matrix_Variante02_Anf 3;
BA_ "GenSigSendType" SG_ 981 TFL_Matrix_Variante03_Anf 3;
BA_ "GenSigSendType" SG_ 981 TFL_Matrix_Variante04_Anf 3;
BA_ "GenSigSendType" SG_ 982 BCM2_Bremsl_durch_ECD 0;
BA_ "GenSigSwitchedByIgnition" SG_ 982 BCM2_Bremsl_durch_ECD 0;
BA_ "GenSigSendType" SG_ 982 BCM2_Bremsl_durch_ECD_invers 0;
BA_ "GenSigStartValue" SG_ 982 BCM2_Bremsl_durch_ECD_invers 1;
BA_ "GenSigSwitchedByIgnition" SG_ 982 BCM2_Bremsl_durch_ECD_invers 0;
BA_ "GenSigSendType" SG_ 982 LH_3_Bremsl_def 0;
BA_ "GenSigSwitchedByIgnition" SG_ 982 LH_3_Bremsl_def 0;
BA_ "GenSigSendType" SG_ 982 LH_Aussenlicht_def 0;
BA_ "GenSigSwitchedByIgnition" SG_ 982 LH_Aussenlicht_def 0;
BA_ "GenSigSendType" SG_ 982 LH_Blinker_HL_akt 0;
BA_ "GenSigSwitchedByIgnition" SG_ 982 LH_Blinker_HL_akt 0;
BA_ "GenSigSendType" SG_ 982 LH_Blinker_HR_akt 0;
BA_ "GenSigSwitchedByIgnition" SG_ 982 LH_Blinker_HR_akt 0;
BA_ "GenSigSendType" SG_ 982 LH_Blinker_li_def 0;
BA_ "GenSigSwitchedByIgnition" SG_ 982 LH_Blinker_li_def 0;
BA_ "GenSigSendType" SG_ 982 LH_Blinker_re_def 0;
BA_ "GenSigSwitchedByIgnition" SG_ 982 LH_Blinker_re_def 0;
BA_ "GenSigSendType" SG_ 982 LH_Brems_Blk_li_def 0;
BA_ "GenSigSwitchedByIgnition" SG_ 982 LH_Brems_Blk_li_def 0;
BA_ "GenSigSendType" SG_ 982 LH_Brems_Blk_re_def 0;
BA_ "GenSigSwitchedByIgnition" SG_ 982 LH_Brems_Blk_re_def 0;
BA_ "GenSigSendType" SG_ 982 LH_Bremsl_li_def 0;
BA_ "GenSigSwitchedByIgnition" SG_ 982 LH_Bremsl_li_def 0;
BA_ "GenSigSendType" SG_ 982 LH_Bremsl_li_ges_def 0;
BA_ "GenSigSwitchedByIgnition" SG_ 982 LH_Bremsl_li_ges_def 0;
BA_ "GenSigSendType" SG_ 982 LH_Bremsl_re_def 0;
BA_ "GenSigSwitchedByIgnition" SG_ 982 LH_Bremsl_re_def 0;
BA_ "GenSigSendType" SG_ 982 LH_Bremsl_re_ges_def 0;
BA_ "GenSigSwitchedByIgnition" SG_ 982 LH_Bremsl_re_ges_def 0;
BA_ "GenSigSendType" SG_ 982 LH_Bremslicht_H_aktiv 0;
BA_ "GenSigSwitchedByIgnition" SG_ 982 LH_Bremslicht_H_aktiv 0;
BA_ "GenSigSendType" SG_ 982 LH_Diag_LED_li_def 0;
BA_ "GenSigSwitchedByIgnition" SG_ 982 LH_Diag_LED_li_def 0;
BA_ "GenSigSendType" SG_ 982 LH_Diag_LED_re_def 0;
BA_ "GenSigSwitchedByIgnition" SG_ 982 LH_Diag_LED_re_def 0;
BA_ "GenSigSendType" SG_ 982 LH_Diag_Status_li_def 0;
BA_ "GenSigSwitchedByIgnition" SG_ 982 LH_Diag_Status_li_def 0;
BA_ "GenSigSendType" SG_ 982 LH_Diag_Status_re_def 0;
BA_ "GenSigSwitchedByIgnition" SG_ 982 LH_Diag_Status_re_def 0;
BA_ "GenSigSendType" SG_ 982 LH_Kennzl_def 0;
BA_ "GenSigSwitchedByIgnition" SG_ 982 LH_Kennzl_def 0;
BA_ "GenSigSendType" SG_ 982 LH_Nebel_li_def 0;
BA_ "GenSigSwitchedByIgnition" SG_ 982 LH_Nebel_li_def 0;
BA_ "GenSigSendType" SG_ 982 LH_Nebel_mi_def 0;
BA_ "GenSigSwitchedByIgnition" SG_ 982 LH_Nebel_mi_def 0;
BA_ "GenSigSendType" SG_ 982 LH_Nebel_re_def 0;
BA_ "GenSigSwitchedByIgnition" SG_ 982 LH_Nebel_re_def 0;
BA_ "GenSigSendType" SG_ 982 LH_Nebelschluss_aktiv 0;
BA_ "GenSigSwitchedByIgnition" SG_ 982 LH_Nebelschluss_aktiv 0;
BA_ "GenSigSendType" SG_ 982 LH_Parklicht_HL_aktiv 0;
BA_ "GenSigSwitchedByIgnition" SG_ 982 LH_Parklicht_HL_aktiv 0;
BA_ "GenSigSendType" SG_ 982 LH_Parklicht_HR_aktiv 0;
BA_ "GenSigSwitchedByIgnition" SG_ 982 LH_Parklicht_HR_aktiv 0;
BA_ "GenSigSendType" SG_ 982 LH_Rueckf_li_def 0;
BA_ "GenSigSwitchedByIgnition" SG_ 982 LH_Rueckf_li_def 0;
BA_ "GenSigSendType" SG_ 982 LH_Rueckf_mi_def 0;
BA_ "GenSigSwitchedByIgnition" SG_ 982 LH_Rueckf_mi_def 0;
BA_ "GenSigSendType" SG_ 982 LH_Rueckf_re_def 0;
BA_ "GenSigSwitchedByIgnition" SG_ 982 LH_Rueckf_re_def 0;
BA_ "GenSigSendType" SG_ 982 LH_Rueckfahrlicht_aktiv 0;
BA_ "GenSigSwitchedByIgnition" SG_ 982 LH_Rueckfahrlicht_aktiv 0;
BA_ "GenSigSendType" SG_ 982 LH_Schluss_Brems_li_def 0;
BA_ "GenSigSwitchedByIgnition" SG_ 982 LH_Schluss_Brems_li_def 0;
BA_ "GenSigSendType" SG_ 982 LH_Schluss_Brems_Nebel_li_def 0;
BA_ "GenSigSwitchedByIgnition" SG_ 982 LH_Schluss_Brems_Nebel_li_def 0;
BA_ "GenSigSendType" SG_ 982 LH_Schluss_Brems_Nebel_re_def 0;
BA_ "GenSigSwitchedByIgnition" SG_ 982 LH_Schluss_Brems_Nebel_re_def 0;
BA_ "GenSigSendType" SG_ 982 LH_Schluss_Brems_re_def 0;
BA_ "GenSigSwitchedByIgnition" SG_ 982 LH_Schluss_Brems_re_def 0;
BA_ "GenSigSendType" SG_ 982 LH_Schluss_Nebel_li_def 0;
BA_ "GenSigSwitchedByIgnition" SG_ 982 LH_Schluss_Nebel_li_def 0;
BA_ "GenSigSendType" SG_ 982 LH_Schluss_Nebel_re_def 0;
BA_ "GenSigSwitchedByIgnition" SG_ 982 LH_Schluss_Nebel_re_def 0;
BA_ "GenSigSendType" SG_ 982 LH_Schlusslicht_li_def 0;
BA_ "GenSigSwitchedByIgnition" SG_ 982 LH_Schlusslicht_li_def 0;
BA_ "GenSigSendType" SG_ 982 LH_Schlusslicht_re_def 0;
BA_ "GenSigSwitchedByIgnition" SG_ 982 LH_Schlusslicht_re_def 0;
BA_ "GenSigSendType" SG_ 982 LH_SL_BRL_BLK_li_def 0;
BA_ "GenSigSwitchedByIgnition" SG_ 982 LH_SL_BRL_BLK_li_def 0;
BA_ "GenSigSendType" SG_ 982 LH_SL_BRL_BLK_re_def 0;
BA_ "GenSigSwitchedByIgnition" SG_ 982 LH_SL_BRL_BLK_re_def 0;
BA_ "GenSigSendType" SG_ 982 LH_Standlicht_H_aktiv 0;
BA_ "GenSigSwitchedByIgnition" SG_ 982 LH_Standlicht_H_aktiv 0;
BA_ "GenSigSendType" SG_ 982 LH_Zusatzschlussl_def 0;
BA_ "GenSigSwitchedByIgnition" SG_ 982 LH_Zusatzschlussl_def 0;
BA_ "GenSigSendType" SG_ 982 Licht_hinten_01_BZ 0;
BA_ "GenSigFuncType" SG_ 982 Licht_hinten_01_BZ 1;
BA_ "GenSigSwitchedByIgnition" SG_ 982 Licht_hinten_01_BZ 0;
BA_ "GenSigSendType" SG_ 134 LWI_01_BZ 0;
BA_ "GenSigFuncType" SG_ 134 LWI_01_BZ 1;
BA_ "GenSigSendType" SG_ 134 LWI_01_CRC 0;
BA_ "GenSigFuncType" SG_ 134 LWI_01_CRC 2;
BA_ "GenSigSwitchedByIgnition" SG_ 134 LWI_01_CRC 0;
BA_ "GenSigSendType" SG_ 134 LWI_Lenkradw_Geschw 0;
BA_ "GenSigStartValue" SG_ 134 LWI_Lenkradw_Geschw 510;
BA_ "Fehlerwert" SG_ 134 LWI_Lenkradw_Geschw 511;
BA_ "GenSigSendType" SG_ 134 LWI_Lenkradwinkel 0;
BA_ "GenSigStartValue" SG_ 134 LWI_Lenkradwinkel 8190;
BA_ "Fehlerwert" SG_ 134 LWI_Lenkradwinkel 8191;
BA_ "GenSigSendType" SG_ 134 LWI_QBit_Lenkradwinkel 0;
BA_ "GenSigStartValue" SG_ 134 LWI_QBit_Lenkradwinkel 1;
BA_ "GenSigSendType" SG_ 134 LWI_QBit_Sub_Daten 0;
BA_ "GenSigSendType" SG_ 134 LWI_Sensorstatus 0;
BA_ "GenSigSendType" SG_ 134 LWI_Sub_Daten 0;
BA_ "GenSigSendType" SG_ 134 LWI_VZ_Lenkradw_Geschw 0;
BA_ "GenSigSendType" SG_ 134 LWI_VZ_Lenkradwinkel 0;
BA_ "GenSigSendType" SG_ 2463978889 Mem_BFS_Fond_03_BZ 0;
BA_ "GenSigFuncType" SG_ 2463978889 Mem_BFS_Fond_03_BZ 1;
BA_ "GenSigSwitchedByIgnition" SG_ 2463978889 Mem_BFS_Fond_03_BZ 0;
BA_ "GenSigSendType" SG_ 2463978889 Mem_BFS_Fond_03_CRC 0;
BA_ "GenSigFuncType" SG_ 2463978889 Mem_BFS_Fond_03_CRC 2;
BA_ "GenSigSwitchedByIgnition" SG_ 2463978889 Mem_BFS_Fond_03_CRC 0;
BA_ "GenSigSendType" SG_ 2463978889 Mem_HBFSFo_Abschaltanf_SRAB 3;
BA_ "GenSigStartValue" SG_ 2463978889 Mem_HBFSFo_Abschaltanf_SRAB 2;
BA_ "GenSigSwitchedByIgnition" SG_ 2463978889 Mem_HBFSFo_Abschaltanf_SRAB 0;
BA_ "Fehlerwert" SG_ 2463978889 Mem_HBFSFo_Abschaltanf_SRAB 3;
BA_ "GenSigSendType" SG_ 2463978889 Mem_HBFSFo_Anzeige_Komfort_HBFS 3;
BA_ "GenSigSwitchedByIgnition" SG_ 2463978889 Mem_HBFSFo_Anzeige_Komfort_HBFS 0;
BA_ "GenSigSendType" SG_ 2463978889 Mem_HBFSFo_ARMTuer_aktiv 3;
BA_ "GenSigSwitchedByIgnition" SG_ 2463978889 Mem_HBFSFo_ARMTuer_aktiv 0;
BA_ "GenSigSendType" SG_ 2463978889 Mem_HBFSFo_ARMTunnel_aktiv 3;
BA_ "GenSigSwitchedByIgnition" SG_ 2463978889 Mem_HBFSFo_ARMTunnel_aktiv 0;
BA_ "GenSigSendType" SG_ 2463978889 Mem_HBFSFo_BANV_aktiv 3;
BA_ "GenSigSwitchedByIgnition" SG_ 2463978889 Mem_HBFSFo_BANV_aktiv 0;
BA_ "GenSigSendType" SG_ 2463978889 Mem_HBFSFo_BATV_aktiv 3;
BA_ "GenSigSwitchedByIgnition" SG_ 2463978889 Mem_HBFSFo_BATV_aktiv 0;
BA_ "GenSigSendType" SG_ 2463978889 Mem_HBFSFo_EE_Entriegl_Motor 3;
BA_ "GenSigSwitchedByIgnition" SG_ 2463978889 Mem_HBFSFo_EE_Entriegl_Motor 0;
BA_ "GenSigSendType" SG_ 2463978889 Mem_HBFSFo_EE_Verr_Sensor_re 3;
BA_ "GenSigSwitchedByIgnition" SG_ 2463978889 Mem_HBFSFo_EE_Verr_Sensor_re 0;
BA_ "Fehlerwert" SG_ 2463978889 Mem_HBFSFo_EE_Verr_Sensor_re 5;
BA_ "GenSigSendType" SG_ 2463978889 Mem_HBFSFo_globaler_Lehnenwinkel 0;
BA_ "GenSigStartValue" SG_ 2463978889 Mem_HBFSFo_globaler_Lehnenwinkel 254;
BA_ "GenSigSwitchedByIgnition" SG_ 2463978889 Mem_HBFSFo_globaler_Lehnenwinkel 0;
BA_ "Fehlerwert" SG_ 2463978889 Mem_HBFSFo_globaler_Lehnenwinkel 255;
BA_ "GenSigSendType" SG_ 2463978889 Mem_HBFSFo_globaler_Sitzflachenw 0;
BA_ "GenSigStartValue" SG_ 2463978889 Mem_HBFSFo_globaler_Sitzflachenw 254;
BA_ "GenSigSwitchedByIgnition" SG_ 2463978889 Mem_HBFSFo_globaler_Sitzflachenw 0;
BA_ "Fehlerwert" SG_ 2463978889 Mem_HBFSFo_globaler_Sitzflachenw 255;
BA_ "GenSigSendType" SG_ 2463978889 Mem_HBFSFo_KSV_aktiv 3;
BA_ "GenSigSwitchedByIgnition" SG_ 2463978889 Mem_HBFSFo_KSV_aktiv 0;
BA_ "GenSigSendType" SG_ 2463978889 Mem_HBFSFo_LED_EA_Taster 3;
BA_ "GenSigSwitchedByIgnition" SG_ 2463978889 Mem_HBFSFo_LED_EA_Taster 0;
BA_ "GenSigSendType" SG_ 2463978889 Mem_HBFSFo_LKV_aktiv 3;
BA_ "GenSigSwitchedByIgnition" SG_ 2463978889 Mem_HBFSFo_LKV_aktiv 0;
BA_ "GenSigSendType" SG_ 2463978889 Mem_HBFSFo_LNV_aktiv 3;
BA_ "GenSigSwitchedByIgnition" SG_ 2463978889 Mem_HBFSFo_LNV_aktiv 0;
BA_ "GenSigSendType" SG_ 2463978889 Mem_HBFSFo_SHV_aktiv 3;
BA_ "GenSigSwitchedByIgnition" SG_ 2463978889 Mem_HBFSFo_SHV_aktiv 0;
BA_ "GenSigSendType" SG_ 2463978889 Mem_HBFSFo_SLV_aktiv 3;
BA_ "GenSigSwitchedByIgnition" SG_ 2463978889 Mem_HBFSFo_SLV_aktiv 0;
BA_ "GenSigSendType" SG_ 2463978889 Mem_HBFSFo_SLV_hinten 3;
BA_ "GenSigSwitchedByIgnition" SG_ 2463978889 Mem_HBFSFo_SLV_hinten 0;
BA_ "GenSigSendType" SG_ 2463978889 Mem_HBFSFo_SNV_aktiv 3;
BA_ "GenSigSwitchedByIgnition" SG_ 2463978889 Mem_HBFSFo_SNV_aktiv 0;
BA_ "GenSigSendType" SG_ 2463978889 Mem_HBFSFo_Sperre_Sitzdisplay 3;
BA_ "GenSigSwitchedByIgnition" SG_ 2463978889 Mem_HBFSFo_Sperre_Sitzdisplay 0;
BA_ "GenSigSendType" SG_ 2463978889 Mem_HBFSFo_Status_Schalter_Ki_Si 3;
BA_ "GenSigStartValue" SG_ 2463978889 Mem_HBFSFo_Status_Schalter_Ki_Si 2;
BA_ "GenSigSwitchedByIgnition" SG_ 2463978889 Mem_HBFSFo_Status_Schalter_Ki_Si 0;
BA_ "Fehlerwert" SG_ 2463978889 Mem_HBFSFo_Status_Schalter_Ki_Si 3;
BA_ "GenSigSendType" SG_ 2463978889 Mem_HBFSFo_Stoerung 3;
BA_ "GenSigSwitchedByIgnition" SG_ 2463978889 Mem_HBFSFo_Stoerung 0;
BA_ "GenSigSendType" SG_ 2463978889 Mem_HBFSFo_STV_aktiv 3;
BA_ "GenSigSwitchedByIgnition" SG_ 2463978889 Mem_HBFSFo_STV_aktiv 0;
BA_ "GenSigSendType" SG_ 2463978889 Mem_HBFSFo_Verr_Sensor_oben_re 3;
BA_ "GenSigSwitchedByIgnition" SG_ 2463978889 Mem_HBFSFo_Verr_Sensor_oben_re 0;
BA_ "Fehlerwert" SG_ 2463978889 Mem_HBFSFo_Verr_Sensor_oben_re 5;
BA_ "GenSigSendType" SG_ 2463978889 Mem_HBFSFo_Verr_Sensor_unten_re 3;
BA_ "GenSigSwitchedByIgnition" SG_ 2463978889 Mem_HBFSFo_Verr_Sensor_unten_re 0;
BA_ "Fehlerwert" SG_ 2463978889 Mem_HBFSFo_Verr_Sensor_unten_re 5;
BA_ "GenSigSendType" SG_ 2463978889 Mem_HBFSFo_Warnung_Softstop 3;
BA_ "GenSigSwitchedByIgnition" SG_ 2463978889 Mem_HBFSFo_Warnung_Softstop 0;
BA_ "Fehlerwert" SG_ 2463978889 Mem_HBFSFo_Warnung_Softstop 3;
BA_ "GenSigSendType" SG_ 2463978890 Mem_FS_Fond_03_BZ 0;
BA_ "GenSigFuncType" SG_ 2463978890 Mem_FS_Fond_03_BZ 1;
BA_ "GenSigSwitchedByIgnition" SG_ 2463978890 Mem_FS_Fond_03_BZ 0;
BA_ "GenSigSendType" SG_ 2463978890 Mem_FS_Fond_03_CRC 0;
BA_ "GenSigFuncType" SG_ 2463978890 Mem_FS_Fond_03_CRC 2;
BA_ "GenSigSwitchedByIgnition" SG_ 2463978890 Mem_FS_Fond_03_CRC 0;
BA_ "GenSigSendType" SG_ 2463978890 Mem_HFSFo_Abschaltanf_SRAB 3;
BA_ "GenSigStartValue" SG_ 2463978890 Mem_HFSFo_Abschaltanf_SRAB 2;
BA_ "GenSigSwitchedByIgnition" SG_ 2463978890 Mem_HFSFo_Abschaltanf_SRAB 0;
BA_ "Fehlerwert" SG_ 2463978890 Mem_HFSFo_Abschaltanf_SRAB 3;
BA_ "GenSigSendType" SG_ 2463978890 Mem_HFSFo_Anzeige_Komfort_HFS 3;
BA_ "GenSigSwitchedByIgnition" SG_ 2463978890 Mem_HFSFo_Anzeige_Komfort_HFS 0;
BA_ "GenSigSendType" SG_ 2463978890 Mem_HFSFo_ARMTuer_aktiv 3;
BA_ "GenSigSwitchedByIgnition" SG_ 2463978890 Mem_HFSFo_ARMTuer_aktiv 0;
BA_ "GenSigSendType" SG_ 2463978890 Mem_HFSFo_ARMTunnel_aktiv 3;
BA_ "GenSigSwitchedByIgnition" SG_ 2463978890 Mem_HFSFo_ARMTunnel_aktiv 0;
BA_ "GenSigSendType" SG_ 2463978890 Mem_HFSFo_BANV_aktiv 3;
BA_ "GenSigSwitchedByIgnition" SG_ 2463978890 Mem_HFSFo_BANV_aktiv 0;
BA_ "GenSigSendType" SG_ 2463978890 Mem_HFSFo_BATV_aktiv 3;
BA_ "GenSigSwitchedByIgnition" SG_ 2463978890 Mem_HFSFo_BATV_aktiv 0;
BA_ "GenSigSendType" SG_ 2463978890 Mem_HFSFo_EA_Position 3;
BA_ "GenSigSwitchedByIgnition" SG_ 2463978890 Mem_HFSFo_EA_Position 0;
BA_ "GenSigSendType" SG_ 2463978890 Mem_HFSFo_EE_Verr_Sensor_li 3;
BA_ "GenSigSwitchedByIgnition" SG_ 2463978890 Mem_HFSFo_EE_Verr_Sensor_li 0;
BA_ "Fehlerwert" SG_ 2463978890 Mem_HFSFo_EE_Verr_Sensor_li 5;
BA_ "GenSigSendType" SG_ 2463978890 Mem_HFSFo_globaler_Lehnenwinkel 0;
BA_ "GenSigStartValue" SG_ 2463978890 Mem_HFSFo_globaler_Lehnenwinkel 254;
BA_ "GenSigSwitchedByIgnition" SG_ 2463978890 Mem_HFSFo_globaler_Lehnenwinkel 0;
BA_ "Fehlerwert" SG_ 2463978890 Mem_HFSFo_globaler_Lehnenwinkel 255;
BA_ "GenSigSendType" SG_ 2463978890 Mem_HFSFo_globaler_Sitzflachenwi 0;
BA_ "GenSigStartValue" SG_ 2463978890 Mem_HFSFo_globaler_Sitzflachenwi 254;
BA_ "GenSigSwitchedByIgnition" SG_ 2463978890 Mem_HFSFo_globaler_Sitzflachenwi 0;
BA_ "Fehlerwert" SG_ 2463978890 Mem_HFSFo_globaler_Sitzflachenwi 255;
BA_ "GenSigSendType" SG_ 2463978890 Mem_HFSFo_KSV_aktiv 3;
BA_ "GenSigSwitchedByIgnition" SG_ 2463978890 Mem_HFSFo_KSV_aktiv 0;
BA_ "GenSigSendType" SG_ 2463978890 Mem_HFSFo_LED_EA_Taster 3;
BA_ "GenSigSwitchedByIgnition" SG_ 2463978890 Mem_HFSFo_LED_EA_Taster 0;
BA_ "GenSigSendType" SG_ 2463978890 Mem_HFSFo_LKV_aktiv 3;
BA_ "GenSigSwitchedByIgnition" SG_ 2463978890 Mem_HFSFo_LKV_aktiv 0;
BA_ "GenSigSendType" SG_ 2463978890 Mem_HFSFo_LNV_aktiv 3;
BA_ "GenSigSwitchedByIgnition" SG_ 2463978890 Mem_HFSFo_LNV_aktiv 0;
BA_ "GenSigSendType" SG_ 2463978890 Mem_HFSFo_SHV_aktiv 3;
BA_ "GenSigSwitchedByIgnition" SG_ 2463978890 Mem_HFSFo_SHV_aktiv 0;
BA_ "GenSigSendType" SG_ 2463978890 Mem_HFSFo_SLV_aktiv 3;
BA_ "GenSigSwitchedByIgnition" SG_ 2463978890 Mem_HFSFo_SLV_aktiv 0;
BA_ "GenSigSendType" SG_ 2463978890 Mem_HFSFo_SLV_hinten 3;
BA_ "GenSigSwitchedByIgnition" SG_ 2463978890 Mem_HFSFo_SLV_hinten 0;
BA_ "GenSigSendType" SG_ 2463978890 Mem_HFSFo_SNV_aktiv 3;
BA_ "GenSigSwitchedByIgnition" SG_ 2463978890 Mem_HFSFo_SNV_aktiv 0;
BA_ "GenSigSendType" SG_ 2463978890 Mem_HFSFo_Sperre_Sitzdisplay 3;
BA_ "GenSigSwitchedByIgnition" SG_ 2463978890 Mem_HFSFo_Sperre_Sitzdisplay 0;
BA_ "GenSigSendType" SG_ 2463978890 Mem_HFSFo_Status_Schalter_Ki_Si 3;
BA_ "GenSigStartValue" SG_ 2463978890 Mem_HFSFo_Status_Schalter_Ki_Si 2;
BA_ "GenSigSwitchedByIgnition" SG_ 2463978890 Mem_HFSFo_Status_Schalter_Ki_Si 0;
BA_ "Fehlerwert" SG_ 2463978890 Mem_HFSFo_Status_Schalter_Ki_Si 3;
BA_ "GenSigSendType" SG_ 2463978890 Mem_HFSFo_Stoerung 3;
BA_ "GenSigSwitchedByIgnition" SG_ 2463978890 Mem_HFSFo_Stoerung 0;
BA_ "GenSigSendType" SG_ 2463978890 Mem_HFSFo_STV_aktiv 3;
BA_ "GenSigSwitchedByIgnition" SG_ 2463978890 Mem_HFSFo_STV_aktiv 0;
BA_ "GenSigSendType" SG_ 2463978890 Mem_HFSFo_Verr_Sensor_oben_li 3;
BA_ "GenSigSwitchedByIgnition" SG_ 2463978890 Mem_HFSFo_Verr_Sensor_oben_li 0;
BA_ "Fehlerwert" SG_ 2463978890 Mem_HFSFo_Verr_Sensor_oben_li 5;
BA_ "GenSigSendType" SG_ 2463978890 Mem_HFSFo_Verr_Sensor_unten_li 3;
BA_ "GenSigSwitchedByIgnition" SG_ 2463978890 Mem_HFSFo_Verr_Sensor_unten_li 0;
BA_ "Fehlerwert" SG_ 2463978890 Mem_HFSFo_Verr_Sensor_unten_li 5;
BA_ "GenSigSendType" SG_ 2463978890 Mem_HFSFo_Warnung_Softstop 3;
BA_ "GenSigSwitchedByIgnition" SG_ 2463978890 Mem_HFSFo_Warnung_Softstop 0;
BA_ "Fehlerwert" SG_ 2463978890 Mem_HFSFo_Warnung_Softstop 3;
BA_ "GenSigSendType" SG_ 245 MFDR_01_BZ 0;
BA_ "GenSigFuncType" SG_ 245 MFDR_01_BZ 1;
BA_ "GenSigSwitchedByIgnition" SG_ 245 MFDR_01_BZ 0;
BA_ "GenSigSendType" SG_ 245 MFDR_01_CRC 0;
BA_ "GenSigFuncType" SG_ 245 MFDR_01_CRC 2;
BA_ "GenSigSwitchedByIgnition" SG_ 245 MFDR_01_CRC 0;
BA_ "GenSigSendType" SG_ 245 MFDR_01_Sendestatus 6;
BA_ "GenSigSwitchedByIgnition" SG_ 245 MFDR_01_Sendestatus 0;
BA_ "GenSigSendType" SG_ 245 MFDR_Active_DCC 0;
BA_ "GenSigSwitchedByIgnition" SG_ 245 MFDR_Active_DCC 0;
BA_ "GenSigSendType" SG_ 245 MFDR_Beschleunigung_yAchse 0;
BA_ "GenSigStartValue" SG_ 245 MFDR_Beschleunigung_yAchse 4094;
BA_ "GenSigSwitchedByIgnition" SG_ 245 MFDR_Beschleunigung_yAchse 0;
BA_ "Fehlerwert" SG_ 245 MFDR_Beschleunigung_yAchse 4095;
BA_ "GenSigSendType" SG_ 245 MFDR_DeltaKuppMom_Soll_L 0;
BA_ "GenSigStartValue" SG_ 245 MFDR_DeltaKuppMom_Soll_L 4094;
BA_ "GenSigSwitchedByIgnition" SG_ 245 MFDR_DeltaKuppMom_Soll_L 0;
BA_ "Fehlerwert" SG_ 245 MFDR_DeltaKuppMom_Soll_L 4095;
BA_ "GenSigSendType" SG_ 245 MFDR_DeltaKuppMom_Soll_R 0;
BA_ "GenSigStartValue" SG_ 245 MFDR_DeltaKuppMom_Soll_R 4094;
BA_ "GenSigSwitchedByIgnition" SG_ 245 MFDR_DeltaKuppMom_Soll_R 0;
BA_ "Fehlerwert" SG_ 245 MFDR_DeltaKuppMom_Soll_R 4095;
BA_ "GenSigSendType" SG_ 245 MFDR_Kurvenrichtung 0;
BA_ "GenSigStartValue" SG_ 245 MFDR_Kurvenrichtung 2;
BA_ "GenSigSwitchedByIgnition" SG_ 245 MFDR_Kurvenrichtung 0;
BA_ "Fehlerwert" SG_ 245 MFDR_Kurvenrichtung 3;
BA_ "GenSigSendType" SG_ 245 MFDR_Offset_DCC_HL 0;
BA_ "GenSigStartValue" SG_ 245 MFDR_Offset_DCC_HL 1022;
BA_ "GenSigSwitchedByIgnition" SG_ 245 MFDR_Offset_DCC_HL 0;
BA_ "Fehlerwert" SG_ 245 MFDR_Offset_DCC_HL 1023;
BA_ "GenSigSendType" SG_ 245 MFDR_Offset_DCC_HR 0;
BA_ "GenSigStartValue" SG_ 245 MFDR_Offset_DCC_HR 1022;
BA_ "GenSigSwitchedByIgnition" SG_ 245 MFDR_Offset_DCC_HR 0;
BA_ "Fehlerwert" SG_ 245 MFDR_Offset_DCC_HR 1023;
BA_ "GenSigSendType" SG_ 245 MFDR_Offset_DCC_VL 0;
BA_ "GenSigStartValue" SG_ 245 MFDR_Offset_DCC_VL 1022;
BA_ "GenSigSwitchedByIgnition" SG_ 245 MFDR_Offset_DCC_VL 0;
BA_ "Fehlerwert" SG_ 245 MFDR_Offset_DCC_VL 1023;
BA_ "GenSigSendType" SG_ 245 MFDR_Offset_DCC_VR 0;
BA_ "GenSigStartValue" SG_ 245 MFDR_Offset_DCC_VR 1022;
BA_ "GenSigSwitchedByIgnition" SG_ 245 MFDR_Offset_DCC_VR 0;
BA_ "Fehlerwert" SG_ 245 MFDR_Offset_DCC_VR 1023;
BA_ "GenSigSendType" SG_ 245 MFDR_Sollfaktor_DCC_HL 0;
BA_ "GenSigStartValue" SG_ 245 MFDR_Sollfaktor_DCC_HL 254;
BA_ "GenSigSwitchedByIgnition" SG_ 245 MFDR_Sollfaktor_DCC_HL 0;
BA_ "Fehlerwert" SG_ 245 MFDR_Sollfaktor_DCC_HL 255;
BA_ "GenSigSendType" SG_ 245 MFDR_Sollfaktor_DCC_HR 0;
BA_ "GenSigStartValue" SG_ 245 MFDR_Sollfaktor_DCC_HR 254;
BA_ "GenSigSwitchedByIgnition" SG_ 245 MFDR_Sollfaktor_DCC_HR 0;
BA_ "Fehlerwert" SG_ 245 MFDR_Sollfaktor_DCC_HR 255;
BA_ "GenSigSendType" SG_ 245 MFDR_Sollfaktor_DCC_VL 0;
BA_ "GenSigStartValue" SG_ 245 MFDR_Sollfaktor_DCC_VL 254;
BA_ "GenSigSwitchedByIgnition" SG_ 245 MFDR_Sollfaktor_DCC_VL 0;
BA_ "Fehlerwert" SG_ 245 MFDR_Sollfaktor_DCC_VL 255;
BA_ "GenSigSendType" SG_ 245 MFDR_Sollfaktor_DCC_VR 0;
BA_ "GenSigStartValue" SG_ 245 MFDR_Sollfaktor_DCC_VR 254;
BA_ "GenSigSwitchedByIgnition" SG_ 245 MFDR_Sollfaktor_DCC_VR 0;
BA_ "Fehlerwert" SG_ 245 MFDR_Sollfaktor_DCC_VR 255;
BA_ "GenSigSendType" SG_ 245 MFDR_UnterUebersteuern 0;
BA_ "GenSigStartValue" SG_ 245 MFDR_UnterUebersteuern 1022;
BA_ "GenSigSwitchedByIgnition" SG_ 245 MFDR_UnterUebersteuern 0;
BA_ "Fehlerwert" SG_ 245 MFDR_UnterUebersteuern 1023;
BA_ "GenSigSendType" SG_ 1471 MFL_Eventcode_1 9;
BA_ "GenSigSwitchedByIgnition" SG_ 1471 MFL_Eventcode_1 0;
BA_ "GenSigSendType" SG_ 1471 MFL_Eventcode_2 9;
BA_ "GenSigSwitchedByIgnition" SG_ 1471 MFL_Eventcode_2 0;
BA_ "GenSigFuncType" SG_ 1471 MFL_Marke 8;
BA_ "GenSigSwitchedByIgnition" SG_ 1471 MFL_Marke 0;
BA_ "GenSigSendType" SG_ 1471 MFL_Tastencode_1 9;
BA_ "GenSigSwitchedByIgnition" SG_ 1471 MFL_Tastencode_1 0;
BA_ "GenSigSendType" SG_ 1471 MFL_Tastencode_2 9;
BA_ "GenSigSwitchedByIgnition" SG_ 1471 MFL_Tastencode_2 0;
BA_ "GenSigFuncType" SG_ 1471 MFL_Variante 8;
BA_ "GenSigSwitchedByIgnition" SG_ 1471 MFL_Variante 0;
BA_ "GenSigSendType" SG_ 1600 MO_Absperrventil_oeffnen 0;
BA_ "GenSigSwitchedByIgnition" SG_ 1600 MO_Absperrventil_oeffnen 0;
BA_ "GenSigSendType" SG_ 1600 MO_aktives_Getriebeheizen 0;
BA_ "GenSigSwitchedByIgnition" SG_ 1600 MO_aktives_Getriebeheizen 0;
BA_ "GenSigSendType" SG_ 1600 MO_Ansaugluft_Temp 0;
BA_ "GenSigStartValue" SG_ 1600 MO_Ansaugluft_Temp 254;
BA_ "GenSigSwitchedByIgnition" SG_ 1600 MO_Ansaugluft_Temp 0;
BA_ "Fehlerwert" SG_ 1600 MO_Ansaugluft_Temp 255;
BA_ "GenSigSendType" SG_ 1600 MO_Getriebe_kuehlen 0;
BA_ "GenSigSwitchedByIgnition" SG_ 1600 MO_Getriebe_kuehlen 0;
BA_ "GenSigSendType" SG_ 1600 MO_Heizungspumpenansteuerung 0;
BA_ "GenSigStartValue" SG_ 1600 MO_Heizungspumpenansteuerung 14;
BA_ "GenSigSwitchedByIgnition" SG_ 1600 MO_Heizungspumpenansteuerung 0;
BA_ "Fehlerwert" SG_ 1600 MO_Heizungspumpenansteuerung 13;
BA_ "GenSigSendType" SG_ 1600 MO_Hoeheninfo 0;
BA_ "GenSigSwitchedByIgnition" SG_ 1600 MO_Hoeheninfo 0;
BA_ "Fehlerwert" SG_ 1600 MO_Hoeheninfo 255;
BA_ "GenSigSendType" SG_ 1600 MO_HYB_Fehler_HV_Netz 0;
BA_ "GenSigSwitchedByIgnition" SG_ 1600 MO_HYB_Fehler_HV_Netz 0;
BA_ "GenSigSendType" SG_ 1600 MO_Kennfeldk 0;
BA_ "GenSigSwitchedByIgnition" SG_ 1600 MO_Kennfeldk 0;
BA_ "GenSigSendType" SG_ 1600 MO_KL15_Abschaltempfehlung 0;
BA_ "GenSigSwitchedByIgnition" SG_ 1600 MO_KL15_Abschaltempfehlung 0;
BA_ "GenSigSendType" SG_ 1600 MO_Kuehlmittel_Temp 0;
BA_ "GenSigStartValue" SG_ 1600 MO_Kuehlmittel_Temp 254;
BA_ "GenSigSwitchedByIgnition" SG_ 1600 MO_Kuehlmittel_Temp 0;
BA_ "Fehlerwert" SG_ 1600 MO_Kuehlmittel_Temp 255;
BA_ "GenSigSendType" SG_ 1600 MO_Mom_Traegheit_02 0;
BA_ "GenSigSwitchedByIgnition" SG_ 1600 MO_Mom_Traegheit_02 0;
BA_ "GenSigSendType" SG_ 1600 MO_Nachlaufzeit_Heizungspumpe 0;
BA_ "GenSigSwitchedByIgnition" SG_ 1600 MO_Nachlaufzeit_Heizungspumpe 0;
BA_ "GenSigSendType" SG_ 1600 MO_Oel_Temp 0;
BA_ "GenSigStartValue" SG_ 1600 MO_Oel_Temp 254;
BA_ "GenSigSwitchedByIgnition" SG_ 1600 MO_Oel_Temp 0;
BA_ "Fehlerwert" SG_ 1600 MO_Oel_Temp 255;
BA_ "GenSigSendType" SG_ 1600 MO_QBit_Ansaugluft_Temp 0;
BA_ "GenSigStartValue" SG_ 1600 MO_QBit_Ansaugluft_Temp 1;
BA_ "GenSigSwitchedByIgnition" SG_ 1600 MO_QBit_Ansaugluft_Temp 0;
BA_ "GenSigSendType" SG_ 1600 MO_QBit_Hoeheninfo 0;
BA_ "GenSigStartValue" SG_ 1600 MO_QBit_Hoeheninfo 1;
BA_ "GenSigSwitchedByIgnition" SG_ 1600 MO_QBit_Hoeheninfo 0;
BA_ "GenSigSendType" SG_ 1600 MO_QBit_Kuehlmittel_Temp 0;
BA_ "GenSigStartValue" SG_ 1600 MO_QBit_Kuehlmittel_Temp 1;
BA_ "GenSigSwitchedByIgnition" SG_ 1600 MO_QBit_Kuehlmittel_Temp 0;
BA_ "GenSigSendType" SG_ 1600 MO_QBit_Oel_Temp 0;
BA_ "GenSigStartValue" SG_ 1600 MO_QBit_Oel_Temp 1;
BA_ "GenSigSwitchedByIgnition" SG_ 1600 MO_QBit_Oel_Temp 0;
BA_ "GenSigSendType" SG_ 1600 MO_SpannungsAnf 0;
BA_ "GenSigSwitchedByIgnition" SG_ 1600 MO_SpannungsAnf 0;
BA_ "GenSigSendType" SG_ 1600 MO_Versionsinfo_02 0;
BA_ "GenSigSwitchedByIgnition" SG_ 1600 MO_Versionsinfo_02 0;
BA_REL_ "GenSigTimeoutTime" BU_SG_REL_ Airbag SG_ 779 KBI_angez_Geschw 500;
BA_REL_ "GenSigTimeoutTime" BU_SG_REL_ Airbag SG_ 1719 KBI_QBit_Aussen_Temp_gef 5000;
BA_REL_ "GenSigTimeoutTime" BU_SG_REL_ Airbag SG_ 1719 KBI_Aussen_Temp_gef 5000;
BA_REL_ "GenSigTimeoutTime" BU_SG_REL_ Airbag SG_ 134 LWI_01_CRC 500;
BA_REL_ "GenSigTimeoutTime" BU_SG_REL_ Airbag SG_ 134 LWI_01_BZ 500;
BA_REL_ "GenSigTimeoutTime" BU_SG_REL_ Airbag SG_ 134 LWI_Sensorstatus 500;
BA_REL_ "GenSigTimeoutTime" BU_SG_REL_ Airbag SG_ 134 LWI_QBit_Lenkradwinkel 500;
BA_REL_ "GenSigTimeoutTime" BU_SG_REL_ Airbag SG_ 134 LWI_Lenkradwinkel 500;
BA_REL_ "GenSigTimeoutTime" BU_SG_REL_ Airbag SG_ 134 LWI_VZ_Lenkradwinkel 500;
BA_REL_ "GenSigTimeoutTime" BU_SG_REL_ Airbag SG_ 134 LWI_Lenkradw_Geschw 500;
BA_REL_ "GenSigTimeoutTime" BU_SG_REL_ Airbag SG_ 2463978889 Mem_BFS_Fond_03_CRC 2000;
BA_REL_ "GenSigTimeoutTime" BU_SG_REL_ Airbag SG_ 2463978889 Mem_BFS_Fond_03_BZ 2000;
BA_REL_ "GenSigTimeoutTime" BU_SG_REL_ Airbag SG_ 2463978889 Mem_HBFSFo_globaler_Lehnenwinkel 2000;
BA_REL_ "GenSigTimeoutTime" BU_SG_REL_ Airbag SG_ 2463978889 Mem_HBFSFo_globaler_Sitzflachenw 2000;
BA_REL_ "GenSigTimeoutTime" BU_SG_REL_ Airbag SG_ 2463978889 Mem_HBFSFo_Abschaltanf_SRAB 2000;
BA_REL_ "GenSigTimeoutTime" BU_SG_REL_ Airbag SG_ 2463978889 Mem_HBFSFo_Status_Schalter_Ki_Si 2000;
BA_REL_ "GenSigTimeoutTime" BU_SG_REL_ Airbag SG_ 2463978890 Mem_FS_Fond_03_CRC 2000;
BA_REL_ "GenSigTimeoutTime" BU_SG_REL_ Airbag SG_ 2463978890 Mem_FS_Fond_03_BZ 2000;
BA_REL_ "GenSigTimeoutTime" BU_SG_REL_ Airbag SG_ 2463978890 Mem_HFSFo_globaler_Lehnenwinkel 2000;
BA_REL_ "GenSigTimeoutTime" BU_SG_REL_ Airbag SG_ 2463978890 Mem_HFSFo_globaler_Sitzflachenwi 2000;
BA_REL_ "GenSigTimeoutTime" BU_SG_REL_ Airbag SG_ 2463978890 Mem_HFSFo_Abschaltanf_SRAB 2000;
BA_REL_ "GenSigTimeoutTime" BU_SG_REL_ Airbag SG_ 2463978890 Mem_HFSFo_Status_Schalter_Ki_Si 2000;
BA_REL_ "GenSigTimeoutTime" BU_SG_REL_ Allrad_Haldex SG_ 1719 KBI_Standzeit_02 5000;
BA_REL_ "GenSigTimeoutTime" BU_SG_REL_ Allrad_Haldex SG_ 1719 KBI_QBit_Aussen_Temp_gef 5000;
BA_REL_ "GenSigTimeoutTime" BU_SG_REL_ Allrad_Haldex SG_ 1719 KBI_Aussen_Temp_gef 5000;
BA_REL_ "GenSigTimeoutTime" BU_SG_REL_ Allrad_Haldex SG_ 134 LWI_01_BZ 500;
BA_REL_ "GenSigTimeoutTime" BU_SG_REL_ Allrad_Haldex SG_ 134 LWI_Sensorstatus 500;
BA_REL_ "GenSigTimeoutTime" BU_SG_REL_ Allrad_Haldex SG_ 134 LWI_QBit_Lenkradwinkel 500;
BA_REL_ "GenSigTimeoutTime" BU_SG_REL_ Allrad_Haldex SG_ 134 LWI_Lenkradwinkel 500;
BA_REL_ "GenSigTimeoutTime" BU_SG_REL_ Allrad_Haldex SG_ 134 LWI_VZ_Lenkradwinkel 500;
BA_REL_ "GenSigTimeoutTime" BU_SG_REL_ DCC_Gen3 SG_ 110 EPS_Zahnstangen_Pos_02 500;
BA_REL_ "GenSigTimeoutTime" BU_SG_REL_ DCC_Gen3 SG_ 110 EPS_VZ_Zahnstangenposition 500;
BA_REL_ "GenSigTimeoutTime" BU_SG_REL_ DCC_Gen3 SG_ 110 EPS_Zahnstangen_Grad 500;
BA_REL_ "GenSigTimeoutTime" BU_SG_REL_ DCC_Gen3 SG_ 110 EPS_VZ_Zahnstangen_Grad 500;
BA_REL_ "GenSigTimeoutTime" BU_SG_REL_ DCC_Gen3 SG_ 245 MFDR_Active_DCC 500;
BA_REL_ "GenSigTimeoutTime" BU_SG_REL_ DCC_Gen3 SG_ 245 MFDR_Kurvenrichtung 500;
BA_REL_ "GenSigTimeoutTime" BU_SG_REL_ DCC_Gen3 SG_ 245 MFDR_Offset_DCC_HL 500;
BA_REL_ "GenSigTimeoutTime" BU_SG_REL_ DCC_Gen3 SG_ 245 MFDR_Offset_DCC_HR 500;
BA_REL_ "GenSigTimeoutTime" BU_SG_REL_ DCC_Gen3 SG_ 245 MFDR_Offset_DCC_VL 500;
BA_REL_ "GenSigTimeoutTime" BU_SG_REL_ DCC_Gen3 SG_ 245 MFDR_Offset_DCC_VR 500;
BA_REL_ "GenSigTimeoutTime" BU_SG_REL_ ESC_MQBW SG_ 779 KBI_Bestaetigung_ESP_Off 500;
BA_REL_ "GenSigTimeoutTime" BU_SG_REL_ ESC_MQBW SG_ 1719 KBI_Standzeit_02 5000;
BA_REL_ "GenSigTimeoutTime" BU_SG_REL_ ESC_MQBW SG_ 1719 KBI_QBit_Aussen_Temp_gef 5000;
BA_REL_ "GenSigTimeoutTime" BU_SG_REL_ ESC_MQBW SG_ 1719 KBI_Aussen_Temp_gef 5000;
BA_REL_ "GenSigTimeoutTime" BU_SG_REL_ ESC_MQBW SG_ 1720 KBI_Reifenumfang 5000;
BA_REL_ "GenSigTimeoutTime" BU_SG_REL_ ESC_MQBW SG_ 110 EPS_05_CRC 500;
BA_REL_ "GenSigTimeoutTime" BU_SG_REL_ ESC_MQBW SG_ 110 EPS_05_BZ 500;
BA_REL_ "GenSigTimeoutTime" BU_SG_REL_ ESC_MQBW SG_ 110 EPS_QBit_Zahnstangen_Pos 500;
BA_REL_ "GenSigTimeoutTime" BU_SG_REL_ ESC_MQBW SG_ 110 EPS_Zahnstangen_Pos_02 500;
BA_REL_ "GenSigTimeoutTime" BU_SG_REL_ ESC_MQBW SG_ 110 EPS_VZ_Zahnstangenposition 500;
BA_REL_ "GenSigTimeoutTime" BU_SG_REL_ ESC_MQBW SG_ 110 EPS_Zahnstangen_Grad 500;
BA_REL_ "GenSigTimeoutTime" BU_SG_REL_ ESC_MQBW SG_ 110 EPS_VZ_Zahnstangen_Grad 500;
BA_REL_ "GenSigTimeoutTime" BU_SG_REL_ ESC_MQBW SG_ 982 Licht_hinten_01_BZ 1000;
BA_REL_ "GenSigTimeoutTime" BU_SG_REL_ ESC_MQBW SG_ 982 BCM2_Bremsl_durch_ECD_invers 1000;
BA_REL_ "GenSigTimeoutTime" BU_SG_REL_ ESC_MQBW SG_ 982 BCM2_Bremsl_durch_ECD 1000;
BA_REL_ "GenSigTimeoutTime" BU_SG_REL_ ESC_MQBW SG_ 982 LH_Bremsl_li_def 1000;
BA_REL_ "GenSigTimeoutTime" BU_SG_REL_ ESC_MQBW SG_ 982 LH_Bremsl_re_def 1000;
BA_REL_ "GenSigTimeoutTime" BU_SG_REL_ ESC_MQBW SG_ 982 LH_Bremsl_li_ges_def 1000;
BA_REL_ "GenSigTimeoutTime" BU_SG_REL_ ESC_MQBW SG_ 982 LH_Bremsl_re_ges_def 1000;
BA_REL_ "GenSigTimeoutTime" BU_SG_REL_ ESC_MQBW SG_ 134 LWI_01_CRC 500;
BA_REL_ "GenSigTimeoutTime" BU_SG_REL_ ESC_MQBW SG_ 134 LWI_01_BZ 500;
BA_REL_ "GenSigTimeoutTime" BU_SG_REL_ ESC_MQBW SG_ 134 LWI_Sensorstatus 500;
BA_REL_ "GenSigTimeoutTime" BU_SG_REL_ ESC_MQBW SG_ 134 LWI_QBit_Lenkradwinkel 500;
BA_REL_ "GenSigTimeoutTime" BU_SG_REL_ ESC_MQBW SG_ 134 LWI_Lenkradwinkel 500;
BA_REL_ "GenSigTimeoutTime" BU_SG_REL_ ESC_MQBW SG_ 134 LWI_VZ_Lenkradwinkel 500;
BA_REL_ "GenSigTimeoutTime" BU_SG_REL_ ESC_MQBW SG_ 134 LWI_VZ_Lenkradw_Geschw 500;
BA_REL_ "GenSigTimeoutTime" BU_SG_REL_ ESC_MQBW SG_ 134 LWI_Lenkradw_Geschw 500;
BA_REL_ "GenSigTimeoutTime" BU_SG_REL_ ESC_MQBW SG_ 1600 MO_Hoeheninfo 5000;
BA_REL_ "GenSigTimeoutTime" BU_SG_REL_ ESC_MQBW SG_ 1600 MO_Mom_Traegheit_02 5000;
BA_REL_ "GenSigTimeoutTime" BU_SG_REL_ Gateway_Max SG_ 2549088271 Allrad_Nachlauftyp 5000;
BA_REL_ "GenSigTimeoutTime" BU_SG_REL_ Gateway_Max SG_ 2549088271 KN_ALR_DiagPfad 5000;
BA_REL_ "GenSigTimeoutTime" BU_SG_REL_ Gateway_Max SG_ 2549088271 ALR_KD_Fehler 2500;
BA_REL_ "GenSigTimeoutTime" BU_SG_REL_ Gateway_Max SG_ 2549088370 Daempfer_Nachlauftyp 5000;
BA_REL_ "GenSigTimeoutTime" BU_SG_REL_ Gateway_Max SG_ 2549088370 KN_DR_DiagPfad 5000;
BA_REL_ "GenSigTimeoutTime" BU_SG_REL_ Gateway_Max SG_ 2549088370 DR_KD_Fehler 2500;
BA_REL_ "GenSigTimeoutTime" BU_SG_REL_ Gateway_Max SG_ 2549088315 EBKV_Nachlauftyp 5000;
BA_REL_ "GenSigTimeoutTime" BU_SG_REL_ Gateway_Max SG_ 2549088315 KN_EBKV_DiagPfad 5000;
BA_REL_ "GenSigTimeoutTime" BU_SG_REL_ Gateway_Max SG_ 2549088315 EBKV_KD_Fehler 2500;
BA_REL_ "GenSigTimeoutTime" BU_SG_REL_ Gateway_Max SG_ 2549088274 Lenkhilfe_Nachlauftyp 5000;
BA_REL_ "GenSigTimeoutTime" BU_SG_REL_ Gateway_Max SG_ 2549088274 KN_EPS_DiagPfad 5000;
BA_REL_ "GenSigTimeoutTime" BU_SG_REL_ Gateway_Max SG_ 2549088274 EPS_KD_Fehler 2500;
BA_REL_ "GenSigTimeoutTime" BU_SG_REL_ Gateway_Max SG_ 810 EPS_Lenkerposition 500;
BA_REL_ "GenSigTimeoutTime" BU_SG_REL_ Gateway_Max SG_ 285 EPS_Notlauf 500;
BA_REL_ "GenSigTimeoutTime" BU_SG_REL_ Gateway_Max SG_ 285 EPS_Unterstuetzungsleistung 500;
BA_REL_ "GenSigTimeoutTime" BU_SG_REL_ Gateway_Max SG_ 285 EPS_StartStopp_Info 500;
BA_REL_ "GenSigTimeoutTime" BU_SG_REL_ Gateway_Max SG_ 159 EPS_Berechneter_LW 500;
BA_REL_ "GenSigTimeoutTime" BU_SG_REL_ Gateway_Max SG_ 159 EPS_BLW_QBit 500;
BA_REL_ "GenSigTimeoutTime" BU_SG_REL_ Gateway_Max SG_ 159 EPS_VZ_BLW 500;
BA_REL_ "GenSigTimeoutTime" BU_SG_REL_ Gateway_Max SG_ 159 EPS_Lenkmoment 500;
BA_REL_ "GenSigTimeoutTime" BU_SG_REL_ Gateway_Max SG_ 159 EPS_Lenkmoment_QBit 500;
BA_REL_ "GenSigTimeoutTime" BU_SG_REL_ Gateway_Max SG_ 159 EPS_VZ_Lenkmoment 500;
BA_REL_ "GenSigTimeoutTime" BU_SG_REL_ Gateway_Max SG_ 110 EPS_Zahnstangen_Pos_02 500;
BA_REL_ "GenSigTimeoutTime" BU_SG_REL_ Gateway_Max SG_ 134 LWI_VZ_Lenkradw_Geschw 500;
BA_REL_ "GenSigTimeoutTime" BU_SG_REL_ Gateway_Max SG_ 134 LWI_Lenkradw_Geschw 500;
BA_REL_ "GenSigTimeoutTime" BU_SG_REL_ Lenkhilfe_REPS SG_ 1600 MO_KL15_Abschaltempfehlung 5000;
VAL_ 2549088271 Allrad_KompSchutz 0 "inaktiv" 1 "aktiv" ;
VAL_ 2549088271 Allrad_Abschaltstufe 0 "keine_Einschraenkung" 1 "Funktionseinschraenkung" ;
VAL_ 2549088271 Allrad_Transport_Mode 0 "keine_Einschraenkung" 1 "Funktionseinschraenkung" ;
VAL_ 2549088271 Allrad_Nachlauftyp 0 "Komm_bei_KL15_EIN" 1 "Komm_nach_KL15_AUS" 2 "Komm_bei_KL15_AUS" ;
VAL_ 2549088271 KN_Allrad_BusKnockOutTimer 255 "BusKnockOut_deaktiviert" ;
VAL_ 2549088271 KN_ALR_DiagPfad 0 "aktiv" 1 "inaktiv" ;
VAL_ 2549088271 ALR_KD_Fehler 0 "kein_KD_Fehler" 1 "KD_Fehler" ;
VAL_ 2549088370 Daempfer_KompSchutz 0 "inaktiv" 1 "aktiv" ;
VAL_ 2549088370 Daempfer_Abschaltstufe 0 "keine_Einschraenkung" 1 "Funktionseinschraenkung" ;
VAL_ 2549088370 Daempfer_Transport_Mode 0 "keine_Einschraenkung" 1 "Funktionseinschraenkung" ;
VAL_ 2549088370 Daempfer_Nachlauftyp 0 "Komm_bei_KL15_EIN" 1 "Komm_nach_KL15_AUS" 2 "Komm_bei_KL15_AUS" ;
VAL_ 2549088370 NM_Daempfer_Wakeup 0 "Peripherie_Wakeup__Ursache_nicht_bekannt" 1 "Bus_Wakeup" ;
VAL_ 2549088370 KN_DR_DiagPfad 0 "aktiv" 1 "inaktiv" ;
VAL_ 2549088370 DR_KD_Fehler 0 "kein_KD_Fehler" 1 "KD_Fehler" ;
VAL_ 2549088315 EBKV_KompSchutz 0 "inaktiv" 1 "aktiv" ;
VAL_ 2549088315 EBKV_Abschaltstufe 0 "keine_Einschraenkung" 1 "Funktionseinschraenkung" ;
VAL_ 2549088315 EBKV_Transport_Mode 0 "keine_Einschraenkung" 1 "Funktionseinschraenkung" ;
VAL_ 2549088315 EBKV_Nachlauftyp 0 "Komm_bei_KL15_EIN" 1 "Komm_nach_KL15_AUS" 2 "Komm_bei_KL15_AUS" ;
VAL_ 2549088315 KN_EBKV_ECUKnockOutTimer 63 "ECUKnockOut_deaktiviert" ;
VAL_ 2549088315 KN_EBKV_BusKnockOut 0 "Funktion_nicht_ausgeloest" 1 "Veto_aktiv" 2 "Funktion_ausgeloest" 3 "Funktion_deaktiviert" ;
VAL_ 2549088315 KN_EBKV_BusKnockOutTimer 255 "BusKnockOut_deaktiviert" ;
VAL_ 2549088315 NM_EBKV_Wakeup 0 "Peripherie_Wakeup__Ursache_nicht_bekannt" 1 "Bus_Wakeup" 2 "KL15_HW" 3 "Bremspedal" 128 "Bewarnung" ;
VAL_ 2549088315 KN_EBKV_ECUKnockOut 0 "Funktion_nicht_ausgeloest" 1 "Veto_war_aktiv" 2 "Funktion_ausgeloest" 3 "Funktion_deaktiviert" ;
VAL_ 2549088315 KN_EBKV_DiagPfad 0 "aktiv" 1 "inaktiv" ;
VAL_ 2549088315 NM_EBKV_Lokalaktiv 0 "war_nicht_lokal_aktiv" 1 "war_lokal_aktiv" ;
VAL_ 2549088315 NM_EBKV_Subsystemaktiv 0 "Subsystem_war_nicht_lokalaktiv" 1 "war_lokalaktiv" ;
VAL_ 2549088315 EBKV_KD_Fehler 0 "kein_KD_Fehler" 1 "KD_Fehler" ;
VAL_ 2549088272 Gateway_KompSchutz 0 "inaktiv" 1 "aktiv" ;
VAL_ 2549088272 Gateway_Abschaltstufe 0 "keine_Einschraenkung" 1 "Funktionseinschraenkung" ;
VAL_ 2549088272 Gateway_Transport_Mode 0 "keine_Einschraenkung" 1 "Funktionseinschraenkung" ;
VAL_ 2549088272 Gateway_Nachlauftyp 0 "Komm_bei_KL15_EIN" 1 "Komm_nach_KL15_AUS" 2 "Komm_bei_KL15_AUS" ;
VAL_ 2549088272 NM_Gateway_Wakeup 0 "Peripherie_Wakeup__Ursache_nicht_bekannt" 1 "Bus_Wakeup" 2 "KL15_HW" 3 "ACAN_Wakeup" 4 "FCAN_Wakeup" 5 "KCAN_Wakeup" 6 "ICAN_Wakeup" 7 "DiagCAN_Wakeup" 8 "ECAN_Wakeup" 9 "Energie_LIN_Wakeup" 10 "Bedien_LIN_Wakeup" 11 "HybridCAN_Wakeup" 12 "Flexray_Wakeup" 13 "MFL_WakeUp" 14 "Ethernet" 15 "DCAN_Wakeup" 16 "K2CAN_Wakeup" 17 "CCAN" 18 "AFSCAN_Wakeup" 19 "LIN1" 20 "LIN2" 21 "LIN3" 22 "LIN4" 23 "LIN5" 24 "LIN6" 25 "FASCAN" 26 "FAS2CAN" 27 "MDKCAN" 32 "FlexRay_Branch1_WakeUp" 33 "FlexRay_Branch2_WakeUp" 34 "FlexRay_Branch3_WakeUp" 35 "FlexRay_Branch4_WakeUp" 36 "FlexRay_Branch5_WakeUp" 37 "FlexRay_Branch6_WakeUp" 38 "FlexRay_Branch7_WakeUp" 39 "FlexRay_Branch8_WakeUp" 40 "FlexRay_Branch9_WakeUp" 41 "FlexRay_Branch10_WakeUp" 42 "FlexRay_Branch11_WakeUp" 43 "FlexRay_Branch12_WakeUp" 44 "FlexRay_Branch13_WakeUp" 45 "FlexRay_Branch14_WakeUp" 46 "FlexRay_Branch15_WakeUp" 47 "FlexRay_Branch16_WakeUp" 128 "Energiemanagement" 129 "Funktionswakeup_OBDC" 130 "Hochvoltenergiemanagement" 131 "CWU_empfangen" 132 "Fuer_Bus_relevanten_FC_empfangen" 133 "OnlineDienst_empfangen" 134 "HV_Aktivieren" 135 "HV_Deaktivieren" 136 "VTS_Suche_DriverCard" 137 "VTS_Hupen_Blinken" 138 "Remote_Vehicle_Status" 139 "Plug_and_Charge" 140 "VTS_Wakeup_Infotainment" 141 "EMHLR" 142 "NFcGW_fordert_OTA_FC_an" 143 "Komponentenschutz" 144 "UserStateServer" 145 "Dimmung" 146 "Kessy" 147 "StandardAussenlicht" 148 "ParkKoordinator" 149 "HVLMDynamicChargingPOI" 150 "HVLMChargingManagementServer" 151 "HVLMExtendedChargingMonitoring" 152 "Zentralverriegelung" 153 "FunctionOnDemand" 154 "IAA" 155 "StandKlimatisierung" 156 "RealTimeMonitor" 157 "Klemmensteuerung" 158 "Fremdladung_erkannt" ;
VAL_ 2549088272 KN_GW_DiagPfad 0 "aktiv" 1 "inaktiv" ;
VAL_ 2549088272 GW_KD_Fehler 0 "kein_KD_Fehler" 1 "KD_Fehler" ;
VAL_ 2549088274 Lenkhilfe_KompSchutz 0 "inaktiv" 1 "aktiv" ;
VAL_ 2549088274 Lenkhilfe_Abschaltstufe 0 "keine_Einschraenkung" 1 "Funktionseinschraenkung" ;
VAL_ 2549088274 Lenkhilfe_Transport_Mode 0 "keine_Einschraenkung" 1 "Funktionseinschraenkung" ;
VAL_ 2549088274 Lenkhilfe_Nachlauftyp 0 "Komm_bei_KL15_EIN" 1 "Komm_nach_KL15_AUS" 2 "Komm_bei_KL15_AUS" ;
VAL_ 2549088274 NM_EPS_Wakeup 0 "Peripherie_Wakeup__Ursache_nicht_bekannt" 1 "Bus_Wakeup" 2 "KL15_HW" 3 "KL30_Reset" ;
VAL_ 2549088274 KN_EPS_DiagPfad 0 "aktiv" 1 "inaktiv" ;
VAL_ 2549088274 EPS_KD_Fehler 0 "kein_KD_Fehler" 1 "KD_Fehler" ;
VAL_ 779 KBI_ABS_Lampe 0 "ABS Lampe aus" 1 "ABS Lampe ein" ;
VAL_ 779 KBI_ESP_Lampe 0 "ESP Lampe aus" 1 "ESP Lampe ein" ;
VAL_ 779 KBI_BKL_Lampe 0 "BKL aus" 1 "BKL ein" ;
VAL_ 779 KBI_Airbag_Lampe 0 "Airbag Lampe aus" 1 "Airbag Lampe ein" ;
VAL_ 779 KBI_SILA_gueltig 0 "ungueltig" 1 "gueltig" ;
VAL_ 779 KBI_Vorglueh_System_Lampe 0 "Lampe aus" 1 "Lampe ein" ;
VAL_ 779 KBI_NV_in_Anzeige 0 "NV_nicht_in_Anzeige" 1 "NV_in_Anzeige" ;
VAL_ 779 KBI_Anzeigestatus_ACC 0 "keine_ACC_Anzeige" 1 "ACC_Anzeige_aktiv" ;
VAL_ 779 KBI_Anzeigestatus_GRA 0 "nicht_vorhanden" 1 "Anzeigemoeglichkeit_vorhanden" 2 "reserviert" 3 "Fehler" ;
VAL_ 779 KBI_Oeldruck_Schalter 0 "offen____p_kleiner_pnenn" 1 "geschlossen____p_groessergleich_pnenn" ;
VAL_ 779 KBI_Tankwarnung 0 "Lampe aus" 1 "Lampe ein" ;
VAL_ 779 KBI_MFA_v_Einheit_01 0 "kmh" 1 "mph" ;
VAL_ 779 KBI_im_Stellgliedtest 0 "kein Stellgliedtest" 1 "Kombi im Stellgliedtest" ;
VAL_ 779 KBI_Anzeigefehler_LDW 0 "nicht vorhanden bzw. unterstützt" 1 "Anzeige iO" 2 "Anzeigefehler" 3 "nicht definiert" ;
VAL_ 779 KBI_Tankwarnung_ungueltig 0 "KBI_Tankwarnung_gueltig" 1 "KBI_Tankwarnung_ungueltig" ;
VAL_ 779 KBI_Oeldruckwarnung 0 "inaktiv" 1 "aktiv" ;
VAL_ 779 KBI_Handbremse 0 "nicht_angezogen" 1 "angezogen" ;
VAL_ 779 KBI_PLA_in_Anzeige 0 "PLA_nicht_in_Anzeige" 1 "PLA_in_Anzeige" ;
VAL_ 779 KBI_Anzeigefehler_NV 0 "kein_Anzeigefehler" 1 "Anzeigefehler" ;
VAL_ 779 KBI_Anzeigestatus_LIM 0 "nicht_vorhanden" 1 "Anzeigemoeglichkeit_vorhanden" 2 "reserviert" 3 "Fehler" ;
VAL_ 779 KBI_ARA_in_Anzeige 0 "ARA nicht in Anzeige" 1 "ARA in Anzeige" ;
VAL_ 779 KBI_Taster_Lift 0 "nicht_betaetigt" 1 "betaetigt" ;
VAL_ 779 KBI_Taster_Fahrwerk 0 "nicht_betaetigt" 1 "betaetigt" ;
VAL_ 779 KBI_Audioabsenkung_MIB 0 "keine_Audio_Absenkung" 1 "Audio_Absenkung_Stufe_1" 2 "Audio_Absenkung_Stufe_2" 3 "Audio_Absenkung_Stufe_3" ;
VAL_ 779 KBI_Bestaetigung_ESP_Off 0 "ESP_off_nicht_quittiert" 1 "ESP_off_quittiert" 2 "Abbruch" ;
VAL_ 779 KBI_Anzeigestatus_RHP 0 "nicht_unterstuetzt_oder_Startup" 1 "Anzeige iO" 2 "Anzeigefehler" 3 "nicht definiert" ;
VAL_ 779 KBI_Konsistenz_ACC 0 "ACC Botschaft konsistent" 1 "ACC Botschaft inkonsistent" ;
VAL_ 779 KBI_Fehler_Anzeige_ACC 0 " iO" 1 "Anzeigefehler ACC" ;
VAL_ 779 KBI_Anzeigefehler_SWA 0 "nicht vorhanden bzw. unterstützt" 1 "Anzeige iO" 2 "Anzeigefehler" 3 "nicht definiert" ;
VAL_ 779 KBI_Systemstatus 0 "KBI_IO" 1 "KBI_System_Failure" ;
VAL_ 1719 KBI_Kilometerstand 1048574 "Init" 1048575 "Fehler" ;
VAL_ 1719 KBI_Standzeit_02 131069 "nicht_verfuegbar" 131070 "Init" 131071 "Fehler" ;
VAL_ 1719 KBI_Reserve_Warnung_Sek 0 "Keine_Warnung" 1 "Sekundaere_Reservewarnung" ;
VAL_ 1719 KBI_RDK_Kalibrier_Anf 0 "keine_Kalibrieranforderung" 1 "Kalibrieranforderung" ;
VAL_ 1719 KBI_Inhalt_Tank 126 "Init" 127 "Fehler" ;
VAL_ 1719 KBI_FStatus_Tank 0 "Tankfüllstand i.O." 1 "Tankfüllstand n.i.O" ;
VAL_ 1719 KBI_aktive_Laengsfunktion_02 0 "Init" 1 "Speedlimiter" 2 "GRA_oder_ACC" 3 "PACCh" 4 "HDC" 5 "p_GRA" 6 "p_Lim" 7 "ACC_im_GRA_Modus" 8 "Travel_Assist" 9 "RHP" ;
VAL_ 1719 KBI_FoD_PopUP_Quittiert 0 "nicht_quittiert" 1 "Meldung_quittiert" ;
VAL_ 1719 KBI_GRA_im_ACC 0 "GRA_im_ACC_nicht_ausgewaehlt" 1 "GRA_im_ACC_ausgewaehlt" ;
VAL_ 1719 KBI_Oelwechsel_durchgefuehrt 0 "Oelwechsel_nicht_durchgefuehrt" 1 "Oelwechsel_durchgefuehrt" ;
VAL_ 1719 KBI_QBit_Aussen_Temp_gef 0 "gueltiger_Wert" 1 "Ersatz_Init_oder_Fehlerwert" ;
VAL_ 1719 KBI_Aussen_Temp_gef 253 "nicht verbaut" 254 "Init" 255 "Fehler" ;
VAL_ 1720 KBI_Variante_USA 0 "keine USA-Variante" 1 "USA-Variante" ;
VAL_ 1720 KBI_Variante 0 "Zeiger Kombiinstrument" 1 "Volldisplay Kombiinstrument" ;
VAL_ 1720 KBI_GAP_Warn_Zeit_abgelaufen 0 "Zaehler_nicht_abgelaufen" 1 "Zaehler_abgelaufen" ;
VAL_ 1720 KBI_Quittierung_Naesse 0 "nicht_quittiert" 1 "quittiert" ;
VAL_ 1720 KBI_BCmE_aktiv 0 "Anzeige_nicht_aktiv" 1 "Anzeige_aktiv" ;
VAL_ 1720 KBI_Sparhinweis_quittiert 0 "nicht_quittiert" 1 "quittiert" ;
VAL_ 1720 KBI_Tankfuellstand_Prozent 126 "Init" 127 "Fehler" ;
VAL_ 1720 KBI_Nachtanken_erkannt 0 "Geberbetrieb" 1 "Nachtankmodus" ;
VAL_ 1720 KBI_Tankinhalt_hochaufl 16382 "Init" 16383 "Fehler" ;
VAL_ 1720 KBI_Max_Tankinhalt 254 "Init" 255 "Fehler" ;
VAL_ 1720 KBI_Quittierung_cAQP 0 "nicht_quittiert" 1 "quittiert" ;
VAL_ 810 EPS_SpannungsAnf 0 "keine_Anforderung" 1 "Anforderung_Stufe1" 2 "Anforderung_Stufe2" 3 "Anforderung_Stufe3" ;
VAL_ 810 EPS_Endanschlag 0 "Init_bzw_Defaultlenkhub" 1 "Lenkhubaufweitung_1" 2 "EA_nicht_angelernt_bzw_Initialisierung_nicht_abgeschlossen" 3 "Fehler" ;
VAL_ 810 EPS_Akustiksignal 0 "Akustiksignal_nicht_aktiv" 1 "Akustiksignal_aktiv" ;
VAL_ 810 EPS_Fehlerlampe 0 "Lampe_aus" 1 "Lampe_ein" ;
VAL_ 810 EPS_Warnungen 0 "kein_Text" 1 "Text_1" 2 "Text_2" 3 "Text_3" 4 "Text_4" 5 "Text_5" ;
VAL_ 810 EPS_PLA_Status 0 "EPS_PLA_Deaktiv" 1 "EPS_PLA_Init" 2 "EPS_PLA_Fehler_mit_Eintrag" 3 "reserviert" 4 "reserviert" 5 "reserviert" 6 "EPS_PLA_Lenkwinkel_aktiv" 7 "EPS_PLA_Abgewiesen" 8 "EPS_PLA_Funktionsbereit" 9 "reserviert" 10 "EPS_PLA_Abbruch" 11 "reserviert" 12 "reserviert" 13 "reserviert" 14 "reserviert" 15 "reserviert" ;
VAL_ 810 EPS_Charisma_FahrPr 0 "keine_Funktion" 1 "Programm_1" 2 "Programm_2" 3 "Programm_3" 4 "Programm_4" 5 "Programm_5" 6 "Programm_6" 7 "Programm_7" 8 "Programm_8" 9 "Programm_9" 10 "Programm_10" 11 "Programm_11" 12 "Programm_12" 13 "Programm_13" 14 "Programm_14" 15 "Programm_15" ;
VAL_ 810 EPS_Charisma_Status 0 "Init" 1 "verfuegbar" 2 "nicht_verfuegbar" 3 "asynchron_durch_Fahrerwunsch" ;
VAL_ 810 EPS_VZ_Zst_Offset_Geradeaus 0 "pos_VZ" 1 "neg_VZ" ;
VAL_ 810 EPS_Lenkerposition 0 "unbekannt" 1 "Linkslenker" 2 "Rechtslenker" ;
VAL_ 810 EPS_Anf_KL 0 "keine_Anforderung" 1 "Anforderung_Kuehlung" ;
VAL_ 810 EPS_ARA_Status 0 "EPS_ARA_Deaktiv" 1 "EPS_ARA_Init" 2 "EPS_ARA_Fehler_mit_Eintrag" 3 "reserviert" 4 "reserviert" 5 "reserviert" 6 "EPS_ARA_Lenkwinkel_aktiv" 7 "EPS_ARA_Abgewiesen" 8 "EPS_ARA_Funktionsbereit" 9 "reserviert" 10 "EPS_ARA_Abbruch" 11 "reserviert" 12 "reserviert" 13 "reserviert" 14 "reserviert" 15 "reserviert" ;
VAL_ 810 EPS_Zst_Offset_Geradeaus 510 "Init" 511 "Fehler" ;
VAL_ 285 EPS_Notlauf 0 "kein_Notlauf" 1 "Notlauf_Unterspannung" 2 "Notlauf_Ueberspannung" 3 "reserviert" 4 "Notlauf_Uebertemperatur" 5 "Notlauf_Unterspannung_und_Uebertemperatur" 6 "Notlauf_Ueberspannung_und_Uebertemperatur" 7 "reserviert" 8 "reserviert" 9 "reserviert" 10 "reserviert" 11 "reserviert" 12 "reserviert" 13 "reserviert" 14 "reserviert" 15 "reserviert" ;
VAL_ 285 EPS_Lastinfo 254 "Init" 255 "Fehler" ;
VAL_ 285 EPS_Unterstuetzungsleistung 254 "Init" 255 "Fehler" ;
VAL_ 285 EPS_Drehzahlreserve 126 "Init" 127 "Fehler" ;
VAL_ 285 EPS_VZ_Drehzahlreserve 0 "positiv" 1 "negativ" ;
VAL_ 285 EPS_Leistungsanforderung 0 "keine_Anforderung" 1 "Anforderung_hoehere_Spannung_oder_Leistung" ;
VAL_ 285 EPS_StartStopp_Info 0 "Motorlauf_nicht_notwendig_(Stoppfreigabe)" 1 "Motoranlauf_nicht_zwingend_notwendig_(Stoppverbot,keine_Startanforderung)" 2 "Motoranlauf_zwingend_notwendig_(Startanforderung)" 3 "Systemfehler" ;
VAL_ 285 EPS_Motorstartverzoegerung 0 "Motoranlauf_Freigabe" 1 "Motoranlauf_verzoegern" 3 "Systemfehler" ;
VAL_ 285 EPS_Warmstartunterstuetzung 0 "keine_Lenkunterstuetzung_im_Stopp_Modus_moeglich" 1 "Lenkung_fordert_keine_erhoehte_Startspannung" ;
VAL_ 285 EPS_Versorgungsspannung 254 "Init" 255 "Fehler" ;
VAL_ 159 EPS_DSR_Status 0 "DSR_deaktiviert" 1 "DSR_Anforderung_nicht_ausfuehrbar" 2 "Kommunikation_ESP_gestoert" 3 "EPS_bzgl_DSR_funktionsbereit" 4 "DSR_Anforderung_abgewiesen" 5 "externer_Momenteneingriff_aktiv" 6 "externer_Lenkwinkeleingriff_aktiv" 7 "externer_Momenten_und_Lenkwinkeleingriff_aktiv" ;
VAL_ 159 EPS_Berechneter_LW 4094 "Init" 4095 "Fehler" ;
VAL_ 159 EPS_BLW_QBit 0 "gueltiger_Wert" 1 "Ersatz_Init_oder_Fehlerwert" ;
VAL_ 159 EPS_VZ_BLW 0 "positiv" 1 "negativ" ;
VAL_ 159 EPS_HCA_Status 0 "HCA_in_der_EPS_deaktiviert" 1 "HCA_Anforderung_nicht_ausfuehrbar_HCA_Fehlerstatus_Initialisierung_Ausschaltphase" 2 "Kommunikation_zum_HCA_SG_gestoert" 3 "EPS_bzgl_HCA_fuktionsbereit" 4 "HCA_Anforderung_abgewiesen_aufgrund_Fehler_in_HCA" 5 "HCA_Momenteneingriff_1_aktiv" 6 "reserviert" 7 "HCA_Momenteneingriff_2_aktiv" 8 "HCA_abgewiesen_aufgrund_Momentenpriorisierung" ;
VAL_ 159 EPS_AWA_Status 0 "AWA_deaktiviert" 1 "AWA_Anf_nicht_ausfuehrbar" 2 "Kom_AWA_gestoert" 3 "EPS_bzgl_AWA_funktionsbereit" 4 "AWA_Anf_abgew" 5 "AWA_Momeingriff_1_aktiv" 6 "reserviert" 7 "AWA_Momeingriff_2_aktiv" 8 "AWA_abgewiesen_aufgrund_Momentenpriorisierung" 9 "Anf_abgewiesen_Bedienueblich" 14 "Init" ;
VAL_ 159 EPS_Lenkmoment 1022 "Init" 1023 "Fehler" ;
VAL_ 159 EPS_Lenkmoment_QBit 0 "gueltiger_Wert" 1 "Ersatz_Init_oder_Fehlerwert" ;
VAL_ 159 EPS_VZ_Lenkmoment 0 "positiv" 1 "negativ" ;
VAL_ 159 EPS_Lenkungstyp 0 "RCEPS_Serie" 1 "RCEPS_Dynamiklenkung" 2 "MQB_DP" 3 "MQB_APA" 4 "MQB_Direktlenkung" 15 "unbekannt" ;
VAL_ 110 EPS_QBit_Zahnstangen_Grad 0 "gueltiger_Wert" 1 "Ersatz_Init_oder_Fehlerwert" ;
VAL_ 110 EPS_Sensorikstatus 0 "iO" 1 "nicht_kalibriert" ;
VAL_ 110 EPS_QBit_Zahnstangen_Pos 0 "gueltiger_Wert" 1 "Ersatz_Init_oder_Fehlerwert" ;
VAL_ 110 EPS_Zahnstangen_Pos_02 32766 "Init" 32767 "Fehler" ;
VAL_ 110 EPS_VZ_Zahnstangenposition 0 "pos_VZ" 1 "neg_VZ" ;
VAL_ 110 EPS_Zahnstangen_Grad 32767 "Fehler" ;
VAL_ 110 EPS_VZ_Zahnstangen_Grad 0 "pos_in_Richt_links_Nullstellung" 1 "neg_in_Richt_rechts_Nullstellung" ;
VAL_ 981 BCM1_Kurvenlicht_links_Anf 0 "linkes_Kurvenlicht/Abbiegelicht_durch_BCM1_nicht_angesteuert" 1 "linkes_Kurven/Abbiegelicht_durch_BCM1_angesteuert" ;
VAL_ 981 BCM1_Kurvenlicht_rechts_Anf 0 "rechtes_Kurvenlicht/Abbiegelicht_durch_BCM1_nicht_angesteuert" 1 "rechtes_Kurvenlicht/Abbiegelicht_durch_BCM1_angesteuert" ;
VAL_ 981 BCM1_Standlicht_Anf 0 "Licht_nicht_angefordert" 1 "Licht ist einzuschalten" ;
VAL_ 981 BCM1_Abblendlicht_Anf 0 "Licht_nicht_angefordert" 1 "Licht ist einzuschalten" ;
VAL_ 981 BCM1_Fernlicht_Anf 0 "Licht_nicht_angefordert" 1 "Licht ist einzuschalten" ;
VAL_ 981 BCM1_Nebellicht_Anf 0 "Licht_nicht_angefordert" 1 "Licht ist einzuschalten" ;
VAL_ 981 BCM1_Parklicht_li_Anf 0 "Licht_nicht_angefordert" 1 "Licht ist einzuschalten" ;
VAL_ 981 BCM1_Parklicht_re_Anf 0 "Licht_nicht_angefordert" 1 "Licht ist einzuschalten" ;
VAL_ 981 BCM1_Nebelschluss_Ahg_Anf 0 "Licht_nicht_angefordert" 1 "Licht ist einzuschalten" ;
VAL_ 981 BCM1_Nebelschluss_Fzg_Anf 0 "Licht_nicht_angefordert" 1 "Licht_ist_einzuschalten" ;
VAL_ 981 BCM1_Schlusslicht_Anf 0 "Licht_nicht_angefordert" 1 "Licht ist einzuschalten" ;
VAL_ 981 BCM_Rueckfahrlicht_Anf 0 "Licht_nicht_angefordert" 1 "Licht_angefordert" ;
VAL_ 981 BCM1_Signaturlicht_Anf 0 "Licht_nicht_angefordert" 1 "Licht_ist_einzuschalten" ;
VAL_ 981 BCM1_Umfeldleuchten_Anf 0 "Licht_nicht_angefordert" 1 "Licht_ist_einzuschalten" ;
VAL_ 981 BCM1_Tagfahrlicht_Anf 0 "Licht_nicht_angefordert" 1 "Licht ist einzuschalten" ;
VAL_ 981 BCM1_Regenlicht_Anf 0 "Licht_nicht_angefordert" 1 "Licht ist einzuschalten" ;
VAL_ 981 BCM1_Autobahnlicht_Anf 0 "Licht_nicht_angefordert" 1 "Licht ist einzuschalten" ;
VAL_ 981 BCM1_Touristen_Licht_Anf 0 "Licht_nicht_angefordert" 1 "Anforderung von Touristenlicht" ;
VAL_ 981 BCM1_CH_aktiv 0 "Inaktiv" 1 "Aktiv" ;
VAL_ 981 BCM1_LH_aktiv 0 "Inaktiv" 1 "Aktiv" ;
VAL_ 981 BCM1_Gleitende_Leuchtw_Anf 0 "Aus" 1 "Ein" ;
VAL_ 981 BCM1_GLW_Fernlicht_Anf 0 "Aus" 1 "Ein" ;
VAL_ 981 BCM1_Adaptive_Lichtvert_Anf 0 "Aus" 1 "Ein" ;
VAL_ 981 BCM1_Animationssperrung 0 "keine_Sperrung" 1 "Sperrung" ;
VAL_ 981 BCM1_CH_LH_aktiv 0 "Comming_Home_Bzw._Leaving_Home_nicht_aktiv" 1 "Comming Home bzw. Leaving Home aktiv" ;
VAL_ 981 BCM1_Allwetterlicht_Anf 0 "Licht_nicht_angefordert" 1 "Licht_ist_einzuschalten" ;
VAL_ 981 TFL_Matrix_Variante01_Anf 0 "nicht_angefordert" 1 "angefordert" ;
VAL_ 981 TFL_Matrix_Variante02_Anf 0 "nicht_angefordert" 1 "angefordert" ;
VAL_ 981 TFL_Matrix_Variante03_Anf 0 "nicht_angefordert" 1 "angefordert" ;
VAL_ 981 TFL_Matrix_Variante04_Anf 0 "nicht_angefordert" 1 "angefordert" ;
VAL_ 982 BCM2_Bremsl_durch_ECD_invers 0 "Bremslicht_durch_ECD_aktiv" 1 "Bremslicht_ist_aus" ;
VAL_ 982 BCM2_Bremsl_durch_ECD 0 "Bremslicht_ist_aus" 1 "Bremslicht_durch_ECD_aktiv" ;
VAL_ 982 LH_Aussenlicht_def 0 "OK" 1 "defekt" ;
VAL_ 982 LH_Standlicht_H_aktiv 1 "Standlicht hinten aktiv" ;
VAL_ 982 LH_Parklicht_HL_aktiv 0 "nicht aktiv" 1 "Parklicht hinten links aktiv" ;
VAL_ 982 LH_Parklicht_HR_aktiv 0 "nicht aktiv" 1 "Parklicht hinten rechts aktiv" ;
VAL_ 982 LH_Bremslicht_H_aktiv 1 "Bremslicht hinten aktiv" ;
VAL_ 982 LH_Nebelschluss_aktiv 0 "nicht aktiv" 1 "aktiv" ;
VAL_ 982 LH_Rueckfahrlicht_aktiv 0 "nicht_aktiv" 1 "aktiv" ;
VAL_ 982 LH_Blinker_HL_akt 1 "Blinker hinten links aktiv" ;
VAL_ 982 LH_Blinker_HR_akt 1 "Blinker hinten rechts aktiv" ;
VAL_ 982 LH_Blinker_li_def 0 "OK" 1 "Blinker hinten links defekt" ;
VAL_ 982 LH_Bremsl_li_def 0 "OK" 1 "mindestens ein Bremslicht hinten links defekt" ;
VAL_ 982 LH_Schlusslicht_li_def 0 "OK" 1 "mindestens ein Schlusslicht hinten links defekt" ;
VAL_ 982 LH_Rueckf_li_def 0 "OK" 1 "Rückfahrlicht hinten links defekt" ;
VAL_ 982 LH_Nebel_li_def 0 "OK" 1 "Nebelschlusslicht_hinten_links_defekt" ;
VAL_ 982 LH_Schluss_Brems_Nebel_li_def 0 "iO" 1 "defekt" ;
VAL_ 982 LH_Schluss_Brems_Nebel_re_def 0 "iO" 1 "defekt" ;
VAL_ 982 LH_Zusatzschlussl_def 0 "OK" 1 "mindestens_ein_Zusatzschlusslicht_defekt" ;
VAL_ 982 LH_Schluss_Brems_li_def 0 "OK" 1 "defekt" ;
VAL_ 982 LH_Schluss_Nebel_li_def 0 "OK" 1 "defekt" ;
VAL_ 982 LH_SL_BRL_BLK_li_def 0 "OK" 1 "defekt" ;
VAL_ 982 LH_Brems_Blk_li_def 0 "OK" 1 "defekt" ;
VAL_ 982 LH_Diag_Status_re_def 0 "OK" 1 "Aussenlict_Diagnose_Systemstoerung_rechts" ;
VAL_ 982 LH_Diag_Status_li_def 0 "OK" 1 "Aussenlicht_Diagnose_Systemstoerung_links" ;
VAL_ 982 LH_Diag_LED_li_def 0 "OK" 1 "Heckleuchte_links_defekt" ;
VAL_ 982 LH_Diag_LED_re_def 0 "OK" 1 "Heckleuchte_rechts_defekt" ;
VAL_ 982 LH_Blinker_re_def 0 "OK" 1 "Blinker hinten rechts defekt" ;
VAL_ 982 LH_Bremsl_re_def 0 "OK" 1 "mindestens ein Bremslicht hinten rechts defekt" ;
VAL_ 982 LH_Schlusslicht_re_def 0 "OK" 1 "mindestens_ein_Schlusslicht_hinten_rechts_defekt" ;
VAL_ 982 LH_Rueckf_re_def 0 "OK" 1 "Rückfahrlicht hinten rechts defekt" ;
VAL_ 982 LH_Nebel_re_def 0 "OK" 1 "Nebelschlusslicht hinten rechts defekt" ;
VAL_ 982 LH_Schluss_Brems_re_def 0 "OK" 1 "defekt" ;
VAL_ 982 LH_Schluss_Nebel_re_def 0 "OK" 1 "defekt" ;
VAL_ 982 LH_SL_BRL_BLK_re_def 0 "OK" 1 "defekt" ;
VAL_ 982 LH_Brems_Blk_re_def 0 "OK" 1 "defekt" ;
VAL_ 982 LH_Kennzl_def 0 "OK" 1 "Kennzeichenbeleuchtung hinten defekt" ;
VAL_ 982 LH_3_Bremsl_def 0 "OK" 1 "hochgesetzte  Bremsleuchte defekt" ;
VAL_ 982 LH_Nebel_mi_def 0 "OK" 1 " Nebelschlusslicht hinten Mitte defekt" ;
VAL_ 982 LH_Rueckf_mi_def 0 "OK" 1 "Rückfahllicht Mitte defekt" ;
VAL_ 982 LH_Bremsl_li_ges_def 0 "OK" 1 "Alle Bremslichter hinten links defekt" ;
VAL_ 982 LH_Bremsl_re_ges_def 0 "OK" 1 "Alle Bremslichter hinten rechts defekt" ;
VAL_ 134 LWI_Sensorstatus 0 "iO" 1 "nicht kalibriert" ;
VAL_ 134 LWI_QBit_Sub_Daten 0 "LWS-Subinfo real (Lenkradwinkelinformation ADS-tauglich) " 1 "LWS-Subinfo simuliert (Lenkradwinkelinformation nicht ADS-tauglich )" ;
VAL_ 134 LWI_QBit_Lenkradwinkel 0 "gültiger Wert" 1 "ausserhalb der Spezifikation" ;
VAL_ 134 LWI_Lenkradwinkel 8190 "Init" 8191 "Fehler" ;
VAL_ 134 LWI_VZ_Lenkradwinkel 0 "positiv_links_von_der_Nullstellung" 1 "negativ" ;
VAL_ 134 LWI_VZ_Lenkradw_Geschw 0 "positiv_links_von_der_Nullstellung" 1 "negativ" ;
VAL_ 134 LWI_Lenkradw_Geschw 510 "Init" 511 "Fehler" ;
VAL_ 2463978889 Mem_HBFSFo_Warnung_Softstop 0 "keine_Warnmeldung" 1 "Warnmeldung" 2 "Reserve" 3 "Fehler" ;
VAL_ 2463978889 Mem_HBFSFo_Stoerung 0 "kein_Fehler_Sitz" 1 "Fehler_Sitz_aktiv" ;
VAL_ 2463978889 Mem_HBFSFo_globaler_Lehnenwinkel 254 "init" 255 "Fehler" ;
VAL_ 2463978889 Mem_HBFSFo_globaler_Sitzflachenw 254 "init" 255 "Fehler" ;
VAL_ 2463978889 Mem_HBFSFo_Sperre_Sitzdisplay 0 "Displaysperre_HBFS_aus" 1 "Displaysperre_HBFS_an" ;
VAL_ 2463978889 Mem_HBFSFo_Abschaltanf_SRAB 0 "Einschaltung_SRAB" 1 "Abschaltung_SRAB" 2 "Init" 3 "Fehler" ;
VAL_ 2463978889 Mem_HBFSFo_Anzeige_Komfort_HBFS 0 "keine_Statusanzeige" 1 "Anzeige_Lehne_ein_mitTon" 2 "Anzeige_SNV_ein_mitTon" 3 "Anzeige_Lehne_UND_SNV_ein_mitTon" 4 "Anzeige_Lehne_ein_oTon" 5 "Anzeige_SNV_ein_oTon" 6 "Anzeige_Lehne_UND_SNV_ein_oTon" ;
VAL_ 2463978889 Mem_HBFSFo_Status_Schalter_Ki_Si 0 "Schalter_Kindersitz_ein" 1 "Schalter_Kindersitz_aus" 2 "Init" 3 "Fehler" ;
VAL_ 2463978889 Mem_HBFSFo_ARMTuer_aktiv 0 "inaktiv" 1 "aktiv" ;
VAL_ 2463978889 Mem_HBFSFo_ARMTunnel_aktiv 0 "inaktiv" 1 "aktiv" ;
VAL_ 2463978889 Mem_HBFSFo_SHV_aktiv 0 "inaktiv" 1 "aktiv" ;
VAL_ 2463978889 Mem_HBFSFo_SLV_aktiv 0 "inaktiv" 1 "aktiv" ;
VAL_ 2463978889 Mem_HBFSFo_SLV_hinten 0 "nicht_hinten" 1 "hinten" ;
VAL_ 2463978889 Mem_HBFSFo_BATV_aktiv 0 "inaktiv" 1 "aktiv" ;
VAL_ 2463978889 Mem_HBFSFo_EE_Entriegl_Motor 0 "geschlossen" 1 "offen" ;
VAL_ 2463978889 Mem_HBFSFo_EE_Verr_Sensor_re 0 "init" 1 "offen" 2 "geschlossen_innen" 3 "geschlossen_aussen" 4 "geschlossen_beide" 5 "Fehler" ;
VAL_ 2463978889 Mem_HBFSFo_Verr_Sensor_oben_re 0 "init" 1 "offen" 2 "geschlossen_innen" 3 "geschlossen_aussen" 4 "geschlossen_beide" 5 "Fehler" ;
VAL_ 2463978889 Mem_HBFSFo_Verr_Sensor_unten_re 0 "init" 1 "offen" 2 "geschlossen_innen" 3 "geschlossen_aussen" 4 "geschlossen_beide" 5 "Fehler" ;
VAL_ 2463978889 Mem_HBFSFo_LNV_aktiv 0 "inaktiv" 1 "aktiv" ;
VAL_ 2463978889 Mem_HBFSFo_SNV_aktiv 0 "inaktiv" 1 "aktiv" ;
VAL_ 2463978889 Mem_HBFSFo_KSV_aktiv 0 "inaktiv" 1 "aktiv" ;
VAL_ 2463978889 Mem_HBFSFo_LKV_aktiv 0 "inaktiv" 1 "aktiv" ;
VAL_ 2463978889 Mem_HBFSFo_STV_aktiv 0 "inaktiv" 1 "aktiv" ;
VAL_ 2463978889 Mem_HBFSFo_BANV_aktiv 0 "inaktiv" 1 "aktiv" ;
VAL_ 2463978889 Mem_HBFSFo_LED_EA_Taster 0 "aus" 1 "Blinken_1Hz" 2 "Blinken_2Hz" 3 "an" ;
VAL_ 2463978890 Mem_HFSFo_Warnung_Softstop 0 "keine_Warnmeldung" 1 "Warnmeldung" 2 "Reserve" 3 "Fehler" ;
VAL_ 2463978890 Mem_HFSFo_Stoerung 0 "kein_Fehler_Sitz" 1 "Fehler_Sitz_aktiv" ;
VAL_ 2463978890 Mem_HFSFo_globaler_Lehnenwinkel 254 "init" 255 "Fehler" ;
VAL_ 2463978890 Mem_HFSFo_globaler_Sitzflachenwi 254 "init" 255 "Fehler" ;
VAL_ 2463978890 Mem_HFSFo_Sperre_Sitzdisplay 0 "Displaysperre_HFS_aus" 1 "Displaysperre_HFS_an" ;
VAL_ 2463978890 Mem_HFSFo_Abschaltanf_SRAB 0 "Einschaltung_SRAB" 1 "Abschaltung_SRAB" 2 "Init" 3 "Fehler" ;
VAL_ 2463978890 Mem_HFSFo_Anzeige_Komfort_HFS 0 "keine_Statusanzeige" 1 "Anzeige_Lehne_ein_mitTon" 2 "Anzeige_SNV_ein_mitTon" 3 "Anzeige_Lehne_UND_SNV_ein_mitTon" 4 "Anzeige_Lehne_ein_oTon" 5 "Anzeige_SNV_ein_oTon" 6 "Anzeige_Lehne_UND_SNV_ein_oTon" ;
VAL_ 2463978890 Mem_HFSFo_Status_Schalter_Ki_Si 0 "Schalter_Kindersitz_ein" 1 "Schalter_Kindersitz_aus" 2 "Init" 3 "Fehler" ;
VAL_ 2463978890 Mem_HFSFo_ARMTuer_aktiv 0 "inaktiv" 1 "aktiv" ;
VAL_ 2463978890 Mem_HFSFo_ARMTunnel_aktiv 0 "inaktiv" 1 "aktiv" ;
VAL_ 2463978890 Mem_HFSFo_SHV_aktiv 0 "inaktiv" 1 "aktiv" ;
VAL_ 2463978890 Mem_HFSFo_SLV_aktiv 0 "inaktiv" 1 "aktiv" ;
VAL_ 2463978890 Mem_HFSFo_SLV_hinten 0 "nicht_hinten" 1 "hinten" ;
VAL_ 2463978890 Mem_HFSFo_BATV_aktiv 0 "inaktiv" 1 "aktiv" ;
VAL_ 2463978890 Mem_HFSFo_EE_Verr_Sensor_li 0 "init" 1 "offen" 2 "geschlossen_innen" 3 "geschlossen_aussen" 4 "geschlossen_beide" 5 "Fehler" ;
VAL_ 2463978890 Mem_HFSFo_Verr_Sensor_oben_li 0 "init" 1 "offen" 2 "geschlossen_innen" 3 "geschlossen_aussen" 4 "geschlossen_beide" 5 "Fehler" ;
VAL_ 2463978890 Mem_HFSFo_Verr_Sensor_unten_li 0 "init" 1 "offen" 2 "geschlossen_innen" 3 "geschlossen_aussen" 4 "geschlossen_beide" 5 "Fehler" ;
VAL_ 2463978890 Mem_HFSFo_LNV_aktiv 0 "inaktiv" 1 "aktiv" ;
VAL_ 2463978890 Mem_HFSFo_SNV_aktiv 0 "inaktiv" 1 "aktiv" ;
VAL_ 2463978890 Mem_HFSFo_KSV_aktiv 0 "inaktiv" 1 "aktiv" ;
VAL_ 2463978890 Mem_HFSFo_LKV_aktiv 0 "inaktiv" 1 "aktiv" ;
VAL_ 2463978890 Mem_HFSFo_STV_aktiv 0 "inaktiv" 1 "aktiv" ;
VAL_ 2463978890 Mem_HFSFo_BANV_aktiv 0 "inaktiv" 1 "aktiv" ;
VAL_ 2463978890 Mem_HFSFo_LED_EA_Taster 0 "aus" 1 "Blinken_1Hz" 2 "Blinken_2Hz" 3 "an" ;
VAL_ 2463978890 Mem_HFSFo_EA_Position 0 "nicht_EA_Position" 1 "EA_Position" ;
VAL_ 245 MFDR_01_Sendestatus 0 "MFDR_01_im_langsamen_Zyklus" 1 "MFDR_01_im_schnellen_Zyklus" ;
VAL_ 245 MFDR_Active_DCC 0 "Init" 1 "DCC_nicht_aktiviert" 2 "DCC_aktiviert_Offset" 3 "DCC_aktiviert_Sollfaktor" ;
VAL_ 245 MFDR_Kurvenrichtung 0 "Linkskurve" 1 "Rechtskurve" 2 "Init" 3 "Fehler" ;
VAL_ 245 MFDR_UnterUebersteuern 1022 "Init" 1023 "Fehler" ;
VAL_ 245 MFDR_Sollfaktor_DCC_HL 254 "Init" 255 "Fehler" ;
VAL_ 245 MFDR_Sollfaktor_DCC_HR 254 "Init" 255 "Fehler" ;
VAL_ 245 MFDR_Sollfaktor_DCC_VL 254 "Init" 255 "Fehler" ;
VAL_ 245 MFDR_Sollfaktor_DCC_VR 254 "Init" 255 "Fehler" ;
VAL_ 245 MFDR_Beschleunigung_yAchse 4094 "Init" 4095 "Fehler" ;
VAL_ 245 MFDR_DeltaKuppMom_Soll_L 4094 "Init" 4095 "Fehler" ;
VAL_ 245 MFDR_DeltaKuppMom_Soll_R 4094 "Init" 4095 "Fehler" ;
VAL_ 245 MFDR_Offset_DCC_HL 1022 "Init" 1023 "Fehler" ;
VAL_ 245 MFDR_Offset_DCC_HR 1022 "Init" 1023 "Fehler" ;
VAL_ 245 MFDR_Offset_DCC_VL 1022 "Init" 1023 "Fehler" ;
VAL_ 245 MFDR_Offset_DCC_VR 1022 "Init" 1023 "Fehler" ;
VAL_ 1471 MFL_Tastencode_1 0 "Key_Released__No_Key" 1 "Context_Menu" 2 "Menu_Up__Next_Screen" 3 "Menu_Down__Previous_Screen" 4 "Up" 5 "Down" 6 "Up__Down_ThumbWheel" 7 "OK__ThumbWheel_Button" 8 "Cancel__Escape" 9 "Main_Menu" 10 "Side_Menu_left" 11 "Side_Menu_right" 12 "FAS_Menu" 13 "Left__Right_ThumbWheel" 14 "FAS_Menu_ThumbWheel" 16 "Volume_Up" 17 "Volume_Down" 18 "Volume_Up__Down_ThumbWheel" 19 "Volume_ThumbWheel_Button" 20 "Audio_Source" 21 "Arrow_A_Up__Right" 22 "Arrow_A_Down__Left" 23 "Arrow_B_Up__Right" 24 "Arrow_B_Down__Left" 25 "PTT__PushToTalk" 26 "PTT_Cancel" 27 "Route_Info" 28 "Hook" 29 "Hang_Up" 30 "Off_Hook" 31 "Light_On__Off" 32 "Mute" 33 "Joker1" 34 "Joker2" 35 "View" 36 "Arrow_A_Up__Down_ThumbWheel" 37 "Lenkradheizung" 38 "Rekuperation" 39 "Tube_Toggle" 40 "DRS_Drag_Reduction_System" 41 "Stopwatch_Start_Stop" 42 "Stopwatch_Nextlap" 100 "MAP" 101 "MAP_Boost" 102 "Turn_signal_left" 103 "Turn_signal_right" 104 "Turn_signal_off" 105 "Flashlight" 106 "Highbeam" 107 "Washer_button" 108 "Wiper_button_left" 109 "Wiper_button_right" 110 "Wiper_button_cancel" 111 "Exhaust_Sound" 112 "Drive_Select_button" 113 "Sport_button" 114 "ESP_Drift_Selection_ThumbWheel" 115 "PTT_special_vehicle" 116 "TravelAssist" 117 "Launch_Control" 118 "Drift_Mode_Button_Increase" 119 "Drift_Mode_Button_Decrease" 120 "Drift_Mode_Button_Select" 121 "Drive_Mode_Button_Increase" 122 "Drive_Mode_Button_Decrease" 123 "Drive_Mode_Button_Select" 124 "E_Boost_Button_Increase" 125 "E_Boost_Button_Decrease" 126 "E_Boost_Button_Select" 127 "PerformanceHybridButton_Increase" 128 "PerformanceHybridButton_Decrease" 129 "EV_Mode_Button" 130 "HUD_Button" 131 "PASM_Wheel" 132 "PASM_Button" 133 "PTV_Wheel" 134 "PTV_Button" 135 "TC_ESC_Wheel" 136 "TC_ESC_Button" 240 "Startup_Reset" 241 "Initialization" ;
VAL_ 1471 MFL_Tastencode_2 0 "Key_Released__No_Key" 1 "Context_Menu" 2 "Menu_Up__Next_Screen" 3 "Menu_Down__Previous_Screen" 4 "Up" 5 "Down" 6 "Up__Down_ThumbWheel" 7 "OK__ThumbWheel_Button" 8 "Cancel__Escape" 9 "Main_Menu" 10 "Side_Menu_left" 11 "Side_Menu_right" 12 "FAS_Menu" 13 "Left__Right_ThumbWheel" 14 "FAS_Menu_ThumbWheel" 16 "Volume_Up" 17 "Volume_Down" 18 "Volume_Up__Down_ThumbWheel" 19 "Volume_ThumbWheel_Button" 20 "Audio_Source" 21 "Arrow_A_Up__Right" 22 "Arrow_A_Down__Left" 23 "Arrow_B_Up__Right" 24 "Arrow_B_Down__Left" 25 "PTT__PushToTalk" 26 "PTT_Cancel" 27 "Route_Info" 28 "Hook" 29 "Hang_Up" 30 "Off_Hook" 31 "Light_On__Off" 32 "Mute" 33 "Joker1" 34 "Joker2" 35 "View" 36 "Arrow_A_Up_Right_Down_Left_ThumbWheel" 37 "Lenkradheizung" 38 "Rekuperation" 39 "Tube_Toggle" 40 "DRS_Drag_Reduction_System" 41 "Stopwatch_Start_Stop" 42 "Stopwatch_Nextlap" 100 "MAP" 101 "MAP_Boost" 102 "Turn_signal_left" 103 "Turn_signal_right" 104 "Turn_signal_off" 105 "Flashlight" 106 "Highbeam" 107 "Washer_button" 108 "Wiper_button_left" 109 "Wiper_button_right" 110 "Wiper_button_cancel" 111 "Exhaust_Sound" 112 "Drive_Select_button" 113 "Sport_button" 114 "ESP_Drift_Selection_ThumbWheel" 115 "PTT_special_vehicle" 116 "TravelAssist" 117 "Launch_Control" 118 "Drift_Mode_Button_Increase" 119 "Drift_Mode_Button_Decrease" 120 "Drift_Mode_Button_Select" 121 "Drive_Mode_Button_Increase" 122 "Drive_Mode_Button_Decrease" 123 "Drive_Mode_Button_Select" 124 "E_Boost_Button_Increase" 125 "E_Boost_Button_Decrease" 126 "E_Boost_Button_Select" 127 "PerformanceHybridButton_Increase" 128 "PerformanceHybridButton_Decrease" 129 "EV_Mode_Button" 130 "HUD_Button" 131 "PASM_Wheel" 132 "PASM_Button" 133 "PTV_Wheel" 134 "PTV_Button" 135 "TC_ESC_Wheel" 136 "TC_ESC_Button" 240 "Startup_Reset" 241 "Initialization" ;
VAL_ 1471 MFL_Eventcode_1 0 "W_no_event____T_no_event" 1 "W_1_Tick_up__T_pressed_normal" 2 "W_2_Ticks_up__T_touched" 3 "W_3_Ticks_up__T_double_click_nor" 4 "W_4_Ticks_up__T_long_press_nor_1" 5 "W_5_Ticks_up__T_long_press_nor_2" 6 "W_6_Ticks_up__T_long_press_nor_3" 7 "W_7_Ticks_up" 9 "W_7_Ticks_dn__T_pressed_strong" 10 "W_6_Ticks_dn" 11 "W_5_Ticks_dn__T_double_click_str" 12 "W_4_Ticks_dn__T_long_press_str_1" 13 "W_3_Ticks_dn__T_long_press_str_2" 14 "W_2_Ticks_dn__T_long_press_str_3" 15 "W_1_Tick_dn" ;
VAL_ 1471 MFL_Eventcode_2 0 "W_no_event____T_no_event" 1 "W_1_Tick_up__T_pressed_normal" 2 "W_2_Ticks_up__T_touched" 3 "W_3_Ticks_up__T_double_click_nor" 4 "W_4_Ticks_up__T_long_press_nor_1" 5 "W_5_Ticks_up__T_long_press_nor_2" 6 "W_6_Ticks_up__T_long_press_nor_3" 7 "W_7_Ticks_up" 9 "W_7_Ticks_dn__T_pressed_strong" 10 "W_6_Ticks_dn" 11 "W_5_Ticks_dn__T_double_click_str" 12 "W_4_Ticks_dn__T_long_press_str_1" 13 "W_3_Ticks_dn__T_long_press_str_2" 14 "W_2_Ticks_dn__T_long_press_str_3" 15 "W_1_Tick_dn" ;
VAL_ 1471 MFL_Marke 0 "VW" 1 "Audi" 2 "Seat" 3 "Skoda" 4 "VW_Nutzf" 5 "Bugatti" 6 "Lamborghini" 7 "Bentley" 8 "Rolls Royce" 9 "Quattro" 10 "kein_Hersteller_1" 11 "kein_Hersteller_2" 12 "kein_Hersteller_3" 13 "kein_Hersteller_4" 14 "Ford" 15 "Porsche" ;
VAL_ 1600 MO_QBit_Ansaugluft_Temp 0 "gueltiger_Wert" 1 "Ersatz_Init_oder_Fehlerwert" ;
VAL_ 1600 MO_QBit_Oel_Temp 0 "gueltiger_Wert" 1 "Ersatz_Init_oder_Fehlerwert" ;
VAL_ 1600 MO_QBit_Kuehlmittel_Temp 0 "gueltiger_Wert" 1 "Ersatz_Init_oder_Fehlerwert" ;
VAL_ 1600 MO_KL15_Abschaltempfehlung 0 "Keine Empfehlung" 1 "Abschaltempfehlung" ;
VAL_ 1600 MO_HYB_Fehler_HV_Netz 0 "i_O" 1 "kein_generatorischer_Betrieb_moeglich" ;
VAL_ 1600 MO_aktives_Getriebeheizen 0 "kein_Ventil_ansteuern" 1 "Ventil_muss_angesteuert_werden" ;
VAL_ 1600 MO_Absperrventil_oeffnen 0 "nicht_verfuegbar" 1 "Ansteuerung_Ventil_zulaessig" 2 "Ventil_oeffnen_oder_geoeffnet" 3 "Ventil_schliessen_oder_geschlossen" ;
VAL_ 1600 MO_Ansaugluft_Temp 254 "Init" 255 "Fehler" ;
VAL_ 1600 MO_Oel_Temp 253 "nicht_verbaut" 254 "Init" 255 "Fehler" ;
VAL_ 1600 MO_Kuehlmittel_Temp 254 "Init" 255 "Fehler" ;
VAL_ 1600 MO_Hoeheninfo 255 "Fehler" ;
VAL_ 1600 MO_Kennfeldk 0 "keine Kennfeldkühlung vorhanden" 1 "Kennfeldkühlung vorhanden" ;
VAL_ 1600 MO_Versionsinfo_02 0 "zum_Projektbeginn_aufgeraeumter_CAN" 1 "Motor_03_mit_10ms" 16 "MQB_mit_neuer_Momentenschnittstelle" ;
VAL_ 1600 MO_QBit_Hoeheninfo 0 "gueltiger_Wert" 1 "Ersatz_Init_oder_Fehlerwert" ;
VAL_ 1600 MO_Getriebe_kuehlen 0 "nicht_kuehlen" 1 "kuehlen" ;
VAL_ 1600 MO_Heizungspumpenansteuerung 13 "Fehler" 14 "Init" 15 "nicht_verbaut" ;
VAL_ 1600 MO_SpannungsAnf 0 "keine_Anforderung" 1 "Anforderung" ;
